VERSION "DNNBNNNYNNNNNNNNNNNNNNNNNNNNNNNNNNNNNNNNNN/4/%%%/4/'%**4NNN///"

NS_ :

BS_:

BU_: Vector__XXX Verdeck TSG_Fahrer TSG_Beifahrer Standheizung SMLS SitzMemo_Fahrer SitzMemo_Beifahrer Reifendruck_VW Reifendruck_Audi PTC_Heizung Multifunktions_SG Komfort_SG Gateway_K FHSG_hinten_rechts FHSG_hinten_links Einparkhilfe Clima BSG Anhaenger_SG

BO_ 1425 mZKE_4: 7 Komfort_SG
 SG_ ZK4_ZVOeffnung : 40|2@1+ (1,0) [0|3] ""  Gateway_K
 SG_ ZK4_verriegelt_int : 8|1@1+ (1,0) [0|1] ""  SitzMemo_Fahrer,BSG,TSG_Beifahrer,TSG_Fahrer,Gateway_K
 SG_ ZK4_verriegelt_ext : 9|1@1+ (1,0) [0|1] ""  SitzMemo_Fahrer,BSG,TSG_Beifahrer,TSG_Fahrer,Gateway_K
 SG_ ZK4_Verdeck_enable : 21|1@1+ (1,0) [0|1] ""  Verdeck,Gateway_K
 SG_ ZK4_Verbau_ZV : 19|1@1+ (1,0) [0|1] ""  Gateway_K
 SG_ ZK4_Verbau_Viertuerer : 16|1@1+ (1,0) [0|1] ""  Gateway_K
 SG_ ZK4_Verbau_Neigung : 34|1@1+ (1,0) [0|1] ""  Gateway_K
 SG_ ZK4_Verbau_eFH_vorn : 17|1@1+ (1,0) [0|1] ""  Gateway_K
 SG_ ZK4_Verbau_eFH_hinten : 18|1@1+ (1,0) [0|1] ""  Gateway_K
 SG_ ZK4_Synchro_Spiegel : 38|1@1+ (1,0) [0|1] ""  TSG_Beifahrer,TSG_Fahrer,Gateway_K
 SG_ ZK4_SD_Komfortoeffnen : 45|1@1+ (1,0) [0|1] ""  Gateway_K
 SG_ ZK4_Schlosstyp : 49|1@1+ (1,0) [0|1] ""  TSG_Beifahrer,TSG_Fahrer
 SG_ ZK4_SAD_Freigabe : 1|1@1+ (1,0) [0|1] ""  Verdeck,BSG,Gateway_K
 SG_ ZK4_Rechtslenker : 20|1@1+ (1,0) [0|1] "" Vector__XXX
 SG_ ZK4_Neigung_aktiv : 27|1@1+ (1,0) [0|1] ""  TSG_Fahrer,Gateway_K
 SG_ ZK4_Komfortfkt_Enable : 2|1@1+ (1,0) [0|1] ""  Verdeck,FHSG_hinten_rechts,FHSG_hinten_links,TSG_Beifahrer,TSG_Fahrer,Gateway_K
 SG_ ZK4_KD_Fehler : 23|1@1+ (1,0) [0|1] ""  Gateway_K
 SG_ ZK4_ist_verriegelt_intern : 35|1@1+ (1,0) [0|1] ""  TSG_Beifahrer,TSG_Fahrer,Gateway_K
 SG_ ZK4_IRUE_aktiv : 28|1@1+ (1,0) [0|1] ""  Gateway_K
 SG_ ZK4_HR_Tuer_offen : 37|1@1+ (1,0) [0|1] ""  BSG,TSG_Beifahrer,TSG_Fahrer,Gateway_K
 SG_ ZK4_HL_Tuer_offen : 36|1@1+ (1,0) [0|1] ""  BSG,TSG_Beifahrer,TSG_Fahrer,Gateway_K
 SG_ ZK4_HDOeffnung : 42|1@1+ (1,0) [0|1] ""  Gateway_K
 SG_ ZK4_HD_Vorraste : 4|1@1+ (1,0) [0|1] ""  Gateway_K
 SG_ ZK4_HD_Hauptraste : 5|1@1+ (1,0) [0|1] ""  Verdeck,BSG,Gateway_K
 SG_ ZK4_HD_Auf_Taster : 26|1@1+ (1,0) [0|1] ""  TSG_Fahrer,Gateway_K
 SG_ ZK4_Handbremse_aktiv : 7|1@1+ (1,0) [0|1] ""  Gateway_K
 SG_ ZK4_gesafet_ext : 10|1@1+ (1,0) [0|1] ""  SitzMemo_Fahrer,BSG,TSG_Beifahrer,TSG_Fahrer,Gateway_K
 SG_ ZK4_FH_Komfortoeffnen : 44|1@1+ (1,0) [0|1] ""  Gateway_K
 SG_ ZK4_FH_Freigabe : 0|1@1+ (1,0) [0|1] ""  BSG,FHSG_hinten_rechts,FHSG_hinten_links,TSG_Beifahrer,TSG_Fahrer,Gateway_K
 SG_ ZK4_Einzeltuerentrieg : 11|1@1+ (1,0) [0|1] ""  SitzMemo_Fahrer,BSG,TSG_Beifahrer,TSG_Fahrer,Gateway_K
 SG_ ZK4_DWA_Akku_leer : 14|1@1+ (1,0) [0|1] ""  Gateway_K
 SG_ ZK4_Autolock : 43|1@1+ (1,0) [0|1] ""  Gateway_K
 SG_ ZK4_Auto_Unlock : 47|1@1+ (1,0) [0|1] ""  Gateway_K
 SG_ ZK4_AD_Komfortoeffnen : 46|1@1+ (1,0) [0|1] ""  Gateway_K
 SG_ ZK4_Absenk_Spiegel : 39|1@1+ (1,0) [0|1] ""  TSG_Beifahrer,TSG_Fahrer,Gateway_K

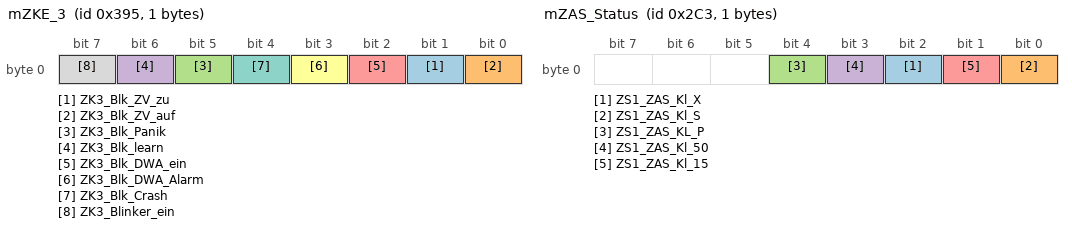
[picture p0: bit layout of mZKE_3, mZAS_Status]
BO_ 917 mZKE_3: 1 Komfort_SG
 SG_ ZK3_Blk_ZV_zu : 1|1@1+ (1,0) [0|1] ""  BSG
 SG_ ZK3_Blk_ZV_auf : 0|1@1+ (1,0) [0|1] ""  BSG
 SG_ ZK3_Blk_Panik : 5|1@1+ (1,0) [0|1] ""  BSG
 SG_ ZK3_Blk_learn : 6|1@1+ (1,0) [0|1] ""  BSG
 SG_ ZK3_Blk_DWA_ein : 2|1@1+ (1,0) [0|1] ""  BSG
 SG_ ZK3_Blk_DWA_Alarm : 3|1@1+ (1,0) [0|1] ""  BSG
 SG_ ZK3_Blk_Crash : 4|1@1+ (1,0) [0|1] ""  BSG
 SG_ ZK3_Blinker_ein : 7|1@1+ (1,0) [0|1] ""  BSG

BO_ 913 mZKE_2: 3 Komfort_SG
 SG_ ZK2_ZV_zu_Heck : 13|1@1+ (1,0) [0|1] ""  FHSG_hinten_rechts,FHSG_hinten_links,TSG_Beifahrer,TSG_Fahrer
 SG_ ZK2_ZV_zu_Funk : 15|1@1+ (1,0) [0|1] ""  BSG,FHSG_hinten_rechts,FHSG_hinten_links,TSG_Beifahrer,TSG_Fahrer
 SG_ ZK2_ZV_zu_FT : 9|1@1+ (1,0) [0|1] ""  BSG,FHSG_hinten_rechts,FHSG_hinten_links,TSG_Beifahrer,TSG_Fahrer
 SG_ ZK2_ZV_zu_BT : 11|1@1+ (1,0) [0|1] ""  BSG,FHSG_hinten_rechts,FHSG_hinten_links,TSG_Beifahrer,TSG_Fahrer
 SG_ ZK2_ZV_auf_Heck : 12|1@1+ (1,0) [0|1] ""  FHSG_hinten_rechts,FHSG_hinten_links,TSG_Beifahrer,TSG_Fahrer
 SG_ ZK2_ZV_auf_Funk : 14|1@1+ (1,0) [0|1] ""  BSG,FHSG_hinten_rechts,FHSG_hinten_links,TSG_Beifahrer,TSG_Fahrer
 SG_ ZK2_ZV_auf_FT : 8|1@1+ (1,0) [0|1] ""  BSG,FHSG_hinten_rechts,FHSG_hinten_links,TSG_Beifahrer,TSG_Fahrer
 SG_ ZK2_ZV_auf_BT : 10|1@1+ (1,0) [0|1] ""  BSG,FHSG_hinten_rechts,FHSG_hinten_links,TSG_Beifahrer,TSG_Fahrer
 SG_ ZK2_SAD_Zu : 18|1@1+ (1,0) [0|1] ""  Verdeck
 SG_ ZK2_SAD_Hoch : 16|1@1+ (1,0) [0|1] ""  Verdeck
 SG_ ZK2_SAD_Auf : 17|1@1+ (1,0) [0|1] ""  Verdeck
 SG_ ZK2_FH_Zu_Z_man : 20|1@1+ (1,0) [0|1] ""  FHSG_hinten_rechts,FHSG_hinten_links,TSG_Beifahrer,TSG_Fahrer
 SG_ ZK2_FH_Zu_Z_auto : 21|1@1+ (1,0) [0|1] ""  FHSG_hinten_rechts,FHSG_hinten_links,TSG_Beifahrer,TSG_Fahrer
 SG_ ZK2_FH_HR_tief : 7|1@1+ (1,0) [0|1] ""  FHSG_hinten_rechts
 SG_ ZK2_FH_HR_hoch : 6|1@1+ (1,0) [0|1] ""  FHSG_hinten_rechts
 SG_ ZK2_FH_HL_tief : 5|1@1+ (1,0) [0|1] ""  FHSG_hinten_links
 SG_ ZK2_FH_HL_hoch : 4|1@1+ (1,0) [0|1] ""  FHSG_hinten_links
 SG_ ZK2_FH_FT_tief : 1|1@1+ (1,0) [0|1] ""  TSG_Fahrer
 SG_ ZK2_FH_FT_hoch : 0|1@1+ (1,0) [0|1] ""  TSG_Fahrer
 SG_ ZK2_FH_BT_tief : 3|1@1+ (1,0) [0|1] ""  TSG_Beifahrer
 SG_ ZK2_FH_BT_hoch : 2|1@1+ (1,0) [0|1] ""  TSG_Beifahrer
 SG_ ZK2_FH_Auf_Z_man : 22|1@1+ (1,0) [0|1] ""  FHSG_hinten_rechts,FHSG_hinten_links,TSG_Beifahrer,TSG_Fahrer
 SG_ ZK2_FH_Auf_Z_auto : 23|1@1+ (1,0) [0|1] ""  FHSG_hinten_rechts,FHSG_hinten_links,TSG_Beifahrer,TSG_Fahrer

BO_ 657 mZKE_1: 5 Komfort_SG
 SG_ ZK1_Zent_safen : 16|1@1+ (1,0) [0|1] ""  BSG,TSG_Beifahrer,TSG_Fahrer
 SG_ ZK1_Zent_entsafen : 17|1@1+ (1,0) [0|1] ""  BSG,TSG_Beifahrer,TSG_Fahrer
 SG_ ZK1_Taste_Zu : 7|1@1+ (1,0) [0|1] ""  SitzMemo_Fahrer,FHSG_hinten_rechts,FHSG_hinten_links,TSG_Beifahrer,TSG_Fahrer
 SG_ ZK1_Taste_Panik : 5|1@1+ (1,0) [0|1] ""  TSG_Beifahrer,TSG_Fahrer
 SG_ ZK1_Taste_HDF : 4|1@1+ (1,0) [0|1] ""  TSG_Beifahrer,TSG_Fahrer
 SG_ ZK1_Taste_Auf : 6|1@1+ (1,0) [0|1] ""  SitzMemo_Fahrer,FHSG_hinten_rechts,FHSG_hinten_links,TSG_Beifahrer,TSG_Fahrer
 SG_ ZK1_LED_Uebernahme : 23|1@1+ (1,0) [0|1] ""  TSG_Fahrer
 SG_ ZK1_LED_Steuerung : 22|1@1+ (1,0) [0|1] ""  TSG_Fahrer
 SG_ ZK1_HR_verriegeln : 14|1@1+ (1,0) [0|1] "" Vector__XXX
 SG_ ZK1_HR_Tuer_offen : 37|1@1+ (1,0) [0|1] ""  FHSG_hinten_rechts
 SG_ ZK1_HR_entriegeln : 15|1@1+ (1,0) [0|1] "" Vector__XXX
 SG_ ZK1_HL_verriegeln : 12|1@1+ (1,0) [0|1] "" Vector__XXX
 SG_ ZK1_HL_Tuer_offen : 36|1@1+ (1,0) [0|1] ""  FHSG_hinten_links
 SG_ ZK1_HL_entriegeln : 13|1@1+ (1,0) [0|1] "" Vector__XXX
 SG_ ZK1_HD_verriegeln : 18|1@1+ (1,0) [0|1] "" Vector__XXX
 SG_ ZK1_HD_schliessen : 21|1@1+ (1,0) [0|1] "" Vector__XXX
 SG_ ZK1_HD_oeffnen : 20|1@1+ (1,0) [0|1] "" Vector__XXX
 SG_ ZK1_HD_entriegeln : 19|1@1+ (1,0) [0|1] "" Vector__XXX
 SG_ ZK1_Funkschl_Nr : 0|3@1+ (1,0) [0|7] ""  SitzMemo_Fahrer
 SG_ ZK1_FT_verriegeln : 8|1@1+ (1,0) [0|1] ""  SitzMemo_Fahrer,TSG_Fahrer
 SG_ ZK1_FT_entriegeln : 9|1@1+ (1,0) [0|1] ""  SitzMemo_Fahrer,TSG_Fahrer
 SG_ ZK1_BT_verriegeln : 10|1@1+ (1,0) [0|1] ""  TSG_Beifahrer
 SG_ ZK1_BT_entriegeln : 11|1@1+ (1,0) [0|1] ""  TSG_Beifahrer
 SG_ ZK1_433_MHz : 3|1@1+ (1,0) [0|1] ""  Reifendruck_VW,Reifendruck_Audi

BO_ 707 mZAS_Status: 1 SMLS
 SG_ ZS1_ZAS_Kl_X : 2|1@1+ (1,0) [0|1] ""  BSG,Gateway_K
 SG_ ZS1_ZAS_Kl_S : 0|1@1+ (1,0) [0|1] ""  Reifendruck_VW,Multifunktions_SG,SitzMemo_Beifahrer,SitzMemo_Fahrer,Anhaenger_SG,BSG,FHSG_hinten_rechts,FHSG_hinten_links,TSG_Beifahrer,TSG_Fahrer,Komfort_SG,Gateway_K
 SG_ ZS1_ZAS_KL_P : 4|1@1+ (1,0) [0|1] ""  BSG,Gateway_K
 SG_ ZS1_ZAS_Kl_50 : 3|1@1+ (1,0) [0|1] ""  BSG,Gateway_K
 SG_ ZS1_ZAS_Kl_15 : 1|1@1+ (1,0) [0|1] ""  BSG,Gateway_K

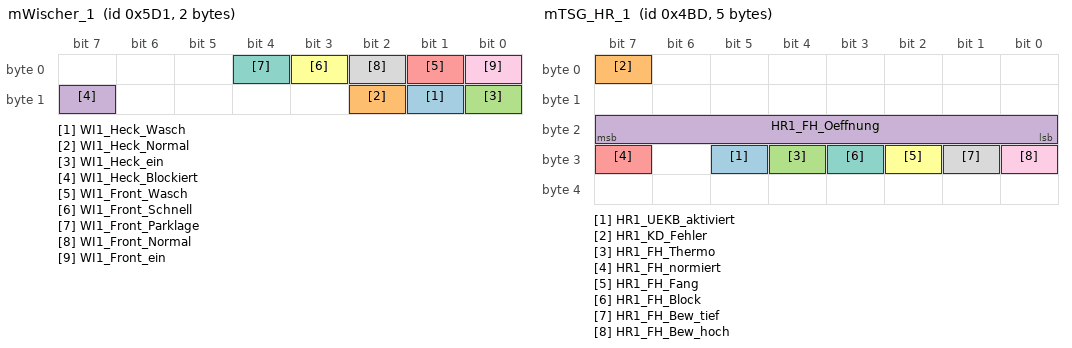
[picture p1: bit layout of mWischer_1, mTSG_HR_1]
BO_ 1489 mWischer_1: 2 BSG
 SG_ WI1_Heck_Wasch : 9|1@1+ (1,0) [0|1] "" Vector__XXX
 SG_ WI1_Heck_Normal : 10|1@1+ (1,0) [0|1] "" Vector__XXX
 SG_ WI1_Heck_ein : 8|1@1+ (1,0) [0|1] ""  Komfort_SG
 SG_ WI1_Heck_Blockiert : 15|1@1+ (1,0) [0|1] "" Vector__XXX
 SG_ WI1_Front_Wasch : 1|1@1+ (1,0) [0|1] ""  Multifunktions_SG
 SG_ WI1_Front_Schnell : 3|1@1+ (1,0) [0|1] ""  Multifunktions_SG
 SG_ WI1_Front_Parklage : 4|1@1+ (1,0) [0|1] "" Vector__XXX
 SG_ WI1_Front_Normal : 2|1@1+ (1,0) [0|1] ""  Multifunktions_SG
 SG_ WI1_Front_ein : 0|1@1+ (1,0) [0|1] ""  Gateway_K

BO_ 1361 mWFS_1: 1 Gateway_K
 SG_ WF1_Schluessel : 0|4@1+ (1,0) [0|15] ""  SitzMemo_Beifahrer,SitzMemo_Fahrer,Clima,Komfort_SG

BO_ 1497 mVSG_1: 5 Verdeck
 SG_ VS1_Verdeck_Anf : 22|1@1+ (1,0) [0|1] ""  Komfort_SG
 SG_ VS1_VD_Zwischenposition : 19|1@1+ (1,0) [0|1] "" Vector__XXX
 SG_ VS1_VD_zu_ver : 16|1@1+ (1,0) [0|1] ""  Komfort_SG
 SG_ VS1_VD_offen_ver : 18|1@1+ (1,0) [0|1] ""  Komfort_SG
 SG_ VS1_VD_Fehler : 24|1@1+ (1,0) [0|1] "" Vector__XXX
 SG_ VS1_VD_entriegelt : 17|1@1+ (1,0) [0|1] "" Vector__XXX
 SG_ VS1_VD_Bew_zu : 21|1@1+ (1,0) [0|1] ""  BSG
 SG_ VS1_VD_Bew_auf : 20|1@1+ (1,0) [0|1] ""  BSG
 SG_ VS1_Texte : 32|8@1+ (1,0) [0|255] "Tabelle"  Gateway_K
 SG_ VS1_Lampe_Blk : 25|1@1+ (1,0) [0|1] ""  Gateway_K
 SG_ VS1_KD_Fehler : 31|1@1+ (1,0) [0|1] "" Vector__XXX
 SG_ VS1_HHS_enable : 28|1@1+ (1,0) [0|1] ""  BSG
 SG_ VS1_Hardtop : 23|1@1+ (1,0) [0|1] "" Vector__XXX
 SG_ VS1_Freigabe_FH : 8|1@1+ (1,0) [0|1] ""  FHSG_hinten_rechts,FHSG_hinten_links,TSG_Beifahrer,TSG_Fahrer
 SG_ VS1_FH_HR_tief : 7|1@1+ (1,0) [0|1] ""  FHSG_hinten_rechts
 SG_ VS1_FH_HR_hoch : 6|1@1+ (1,0) [0|1] ""  FHSG_hinten_rechts
 SG_ VS1_FH_HL_tief : 5|1@1+ (1,0) [0|1] ""  FHSG_hinten_links
 SG_ VS1_FH_HL_hoch : 4|1@1+ (1,0) [0|1] ""  FHSG_hinten_links
 SG_ VS1_FH_FT_tief : 1|1@1+ (1,0) [0|1] ""  TSG_Fahrer
 SG_ VS1_FH_FT_hoch : 0|1@1+ (1,0) [0|1] ""  TSG_Fahrer
 SG_ VS1_FH_BT_tief : 3|1@1+ (1,0) [0|1] ""  TSG_Beifahrer
 SG_ VS1_FH_BT_hoch : 2|1@1+ (1,0) [0|1] ""  TSG_Beifahrer
 SG_ VS1_Buzzer : 27|1@1+ (1,0) [0|1] ""  Gateway_K

BO_ 1213 mTSG_HR_1: 5 FHSG_hinten_rechts
 SG_ HR1_UEKB_aktiviert : 29|1@1+ (1,0) [0|1] ""  Komfort_SG
 SG_ HR1_KD_Fehler : 7|1@1+ (1,0) [0|1] ""  Gateway_K
 SG_ HR1_FH_Thermo : 28|1@1+ (1,0) [0|1] ""  Komfort_SG
 SG_ HR1_FH_Oeffnung : 16|8@1+ (0.5,0) [0|100] "%"  Verdeck,Komfort_SG
 SG_ HR1_FH_normiert : 31|1@1+ (1,0) [0|1] ""  Komfort_SG
 SG_ HR1_FH_Fang : 26|1@1+ (1,0) [0|1] ""  Komfort_SG
 SG_ HR1_FH_Block : 27|1@1+ (1,0) [0|1] ""  Komfort_SG
 SG_ HR1_FH_Bew_tief : 25|1@1+ (1,0) [0|1] ""  BSG,Komfort_SG
 SG_ HR1_FH_Bew_hoch : 24|1@1+ (1,0) [0|1] ""  BSG,Komfort_SG

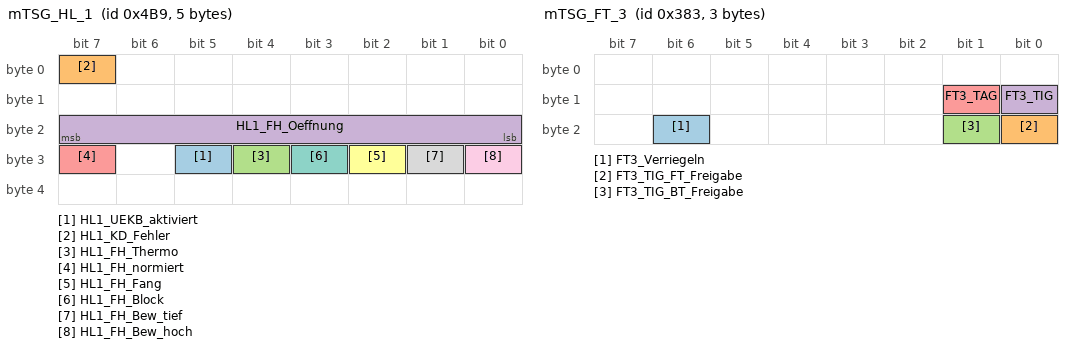
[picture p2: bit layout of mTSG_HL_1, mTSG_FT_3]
BO_ 1209 mTSG_HL_1: 5 FHSG_hinten_links
 SG_ HL1_UEKB_aktiviert : 29|1@1+ (1,0) [0|1] ""  Komfort_SG
 SG_ HL1_KD_Fehler : 7|1@1+ (1,0) [0|1] ""  Gateway_K
 SG_ HL1_FH_Thermo : 28|1@1+ (1,0) [0|1] ""  Komfort_SG
 SG_ HL1_FH_Oeffnung : 16|8@1+ (0.5,0) [0|100] "%"  Verdeck,Komfort_SG
 SG_ HL1_FH_normiert : 31|1@1+ (1,0) [0|1] ""  Komfort_SG
 SG_ HL1_FH_Fang : 26|1@1+ (1,0) [0|1] ""  Komfort_SG
 SG_ HL1_FH_Block : 27|1@1+ (1,0) [0|1] ""  Komfort_SG
 SG_ HL1_FH_Bew_tief : 25|1@1+ (1,0) [0|1] ""  BSG,Komfort_SG
 SG_ HL1_FH_Bew_hoch : 24|1@1+ (1,0) [0|1] ""  BSG,Komfort_SG

BO_ 899 mTSG_FT_3: 3 TSG_Fahrer
 SG_ FT3_Verriegeln : 22|1@1+ (1,0) [0|1] "" Vector__XXX
 SG_ FT3_TIG_FT_Freigabe : 16|1@1+ (1,0) [0|1] "" Vector__XXX
 SG_ FT3_TIG_BT_Freigabe : 17|1@1+ (1,0) [0|1] ""  TSG_Beifahrer
 SG_ FT3_TIG : 8|1@1+ (1,0) [0|1] "" Vector__XXX
 SG_ FT3_TAG : 9|1@1+ (1,0) [0|1] "" Vector__XXX

BO_ 897 mTSG_FT_1: 5 TSG_Fahrer
 SG_ FT1_verriegelt : 1|1@1+ (1,0) [0|1] ""  Komfort_SG
 SG_ FT1_Unlock_Taster : 5|1@1+ (1,0) [0|1] ""  Komfort_SG
 SG_ FT1_UEKB_aktiviert : 29|1@1+ (1,0) [0|1] ""  Komfort_SG
 SG_ FT1_Tuer_geoeffnet : 0|1@1+ (1,0) [0|1] ""  Reifendruck_Audi,Multifunktions_SG,BSG,TSG_Beifahrer,Komfort_SG
 SG_ FT1_Tankklappe_oeffnen : 36|1@1+ (1,0) [0|1] ""  Komfort_SG
 SG_ FT1_SP_Heizung_ein : 34|1@1+ (1,0) [0|1] ""  BSG
 SG_ FT1_SP_ausgerastet : 32|1@1+ (1,0) [0|1] "" Vector__XXX
 SG_ FT1_SP_AS_verbaut : 33|1@1+ (1,0) [0|1] "" Vector__XXX
 SG_ FT1_Schl_zu : 4|1@1+ (1,0) [0|1] ""  TSG_Beifahrer,Komfort_SG
 SG_ FT1_Schl_auf : 3|1@1+ (1,0) [0|1] ""  TSG_Beifahrer,Komfort_SG
 SG_ FT1_Neig_Taster : 38|1@1+ (1,0) [0|1] ""  Komfort_SG
 SG_ FT1_Lock_Taster : 6|1@1+ (1,0) [0|1] ""  Komfort_SG
 SG_ FT1_KD_Fehler : 7|1@1+ (1,0) [0|1] ""  Gateway_K
 SG_ FT1_IRUE_Taste : 35|1@1+ (1,0) [0|1] ""  Komfort_SG
 SG_ FT1_HD_oeffnen : 37|1@1+ (1,0) [0|1] ""  Komfort_SG
 SG_ FT1_gesafet : 2|1@1+ (1,0) [0|1] ""  Komfort_SG
 SG_ FT1_FH_Thermo : 28|1@1+ (1,0) [0|1] ""  Komfort_SG
 SG_ FT1_FH_Oeffnung : 16|8@1+ (0.5,0) [0|100] "%"  Verdeck,Komfort_SG
 SG_ FT1_FH_normiert : 31|1@1+ (1,0) [0|1] ""  Komfort_SG
 SG_ FT1_FH_HR_Freigabe : 11|1@1+ (1,0) [0|1] ""  FHSG_hinten_rechts
 SG_ FT1_FH_HL_Freigabe : 10|1@1+ (1,0) [0|1] ""  FHSG_hinten_links
 SG_ FT1_FH_FT_Freigabe : 8|1@1+ (1,0) [0|1] "" Vector__XXX
 SG_ FT1_FH_Fang : 26|1@1+ (1,0) [0|1] ""  Komfort_SG
 SG_ FT1_FH_BT_Freigabe : 9|1@1+ (1,0) [0|1] ""  TSG_Beifahrer
 SG_ FT1_FH_Block : 27|1@1+ (1,0) [0|1] ""  Komfort_SG
 SG_ FT1_FH_Bew_tief : 25|1@1+ (1,0) [0|1] ""  BSG,Komfort_SG
 SG_ FT1_FH_Bew_hoch : 24|1@1+ (1,0) [0|1] ""  BSG,Komfort_SG

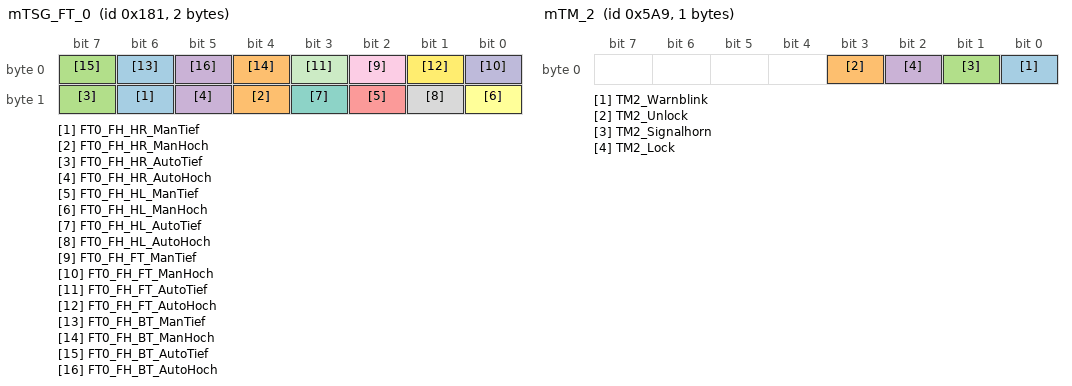
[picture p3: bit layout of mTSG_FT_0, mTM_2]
BO_ 385 mTSG_FT_0: 2 TSG_Fahrer
 SG_ FT0_FH_HR_ManTief : 14|1@1+ (1,0) [0|1] ""  FHSG_hinten_rechts
 SG_ FT0_FH_HR_ManHoch : 12|1@1+ (1,0) [0|1] ""  FHSG_hinten_rechts
 SG_ FT0_FH_HR_AutoTief : 15|1@1+ (1,0) [0|1] ""  FHSG_hinten_rechts
 SG_ FT0_FH_HR_AutoHoch : 13|1@1+ (1,0) [0|1] ""  FHSG_hinten_rechts
 SG_ FT0_FH_HL_ManTief : 10|1@1+ (1,0) [0|1] ""  FHSG_hinten_links
 SG_ FT0_FH_HL_ManHoch : 8|1@1+ (1,0) [0|1] ""  FHSG_hinten_links
 SG_ FT0_FH_HL_AutoTief : 11|1@1+ (1,0) [0|1] ""  FHSG_hinten_links
 SG_ FT0_FH_HL_AutoHoch : 9|1@1+ (1,0) [0|1] ""  FHSG_hinten_links
 SG_ FT0_FH_FT_ManTief : 2|1@1+ (1,0) [0|1] ""  Komfort_SG
 SG_ FT0_FH_FT_ManHoch : 0|1@1+ (1,0) [0|1] ""  Komfort_SG
 SG_ FT0_FH_FT_AutoTief : 3|1@1+ (1,0) [0|1] ""  Multifunktions_SG,Komfort_SG
 SG_ FT0_FH_FT_AutoHoch : 1|1@1+ (1,0) [0|1] ""  Multifunktions_SG,Komfort_SG
 SG_ FT0_FH_BT_ManTief : 6|1@1+ (1,0) [0|1] ""  TSG_Beifahrer
 SG_ FT0_FH_BT_ManHoch : 4|1@1+ (1,0) [0|1] ""  TSG_Beifahrer
 SG_ FT0_FH_BT_AutoTief : 7|1@1+ (1,0) [0|1] ""  Multifunktions_SG,TSG_Beifahrer
 SG_ FT0_FH_BT_AutoHoch : 5|1@1+ (1,0) [0|1] ""  Multifunktions_SG,TSG_Beifahrer

BO_ 949 mTSG_BT_1: 5 TSG_Beifahrer
 SG_ BT1_verriegelt : 1|1@1+ (1,0) [0|1] ""  Komfort_SG
 SG_ BT1_Unlock_Taster : 5|1@1+ (1,0) [0|1] ""  Komfort_SG
 SG_ BT1_UEKB_aktiviert : 29|1@1+ (1,0) [0|1] ""  Komfort_SG
 SG_ BT1_Tuer_geoeffnet : 0|1@1+ (1,0) [0|1] ""  BSG,TSG_Fahrer,Komfort_SG
 SG_ BT1_SP_Heizung_ein : 34|1@1+ (1,0) [0|1] ""  BSG
 SG_ BT1_SP_ausgerastet : 32|1@1+ (1,0) [0|1] ""  TSG_Fahrer
 SG_ BT1_SP_AS_verbaut : 33|1@1+ (1,0) [0|1] "" Vector__XXX
 SG_ BT1_Schl_zu : 4|1@1+ (1,0) [0|1] ""  TSG_Fahrer,Komfort_SG
 SG_ BT1_Schl_auf : 3|1@1+ (1,0) [0|1] ""  TSG_Fahrer,Komfort_SG
 SG_ BT1_Lock_Taster : 6|1@1+ (1,0) [0|1] ""  Komfort_SG
 SG_ BT1_KD_Fehler : 7|1@1+ (1,0) [0|1] ""  Gateway_K
 SG_ BT1_gesafet : 2|1@1+ (1,0) [0|1] ""  Komfort_SG
 SG_ BT1_FH_Thermo : 28|1@1+ (1,0) [0|1] ""  Komfort_SG
 SG_ BT1_FH_Oeffnung : 16|8@1+ (0.5,0) [0|100] "%"  Verdeck,Komfort_SG
 SG_ BT1_FH_normiert : 31|1@1+ (1,0) [0|1] ""  Komfort_SG
 SG_ BT1_FH_Fang : 26|1@1+ (1,0) [0|1] ""  Komfort_SG
 SG_ BT1_FH_Block : 27|1@1+ (1,0) [0|1] ""  Komfort_SG
 SG_ BT1_FH_Bew_tief : 25|1@1+ (1,0) [0|1] ""  BSG,Komfort_SG
 SG_ BT1_FH_Bew_hoch : 24|1@1+ (1,0) [0|1] ""  BSG,Komfort_SG

BO_ 562 mTP_Er_Wischermodul: 7 BSG
 SG_ Wischermodul_TP_Er : 0|56@1+ (1,0) [0|0] ""  Gateway_K

BO_ 560 mTP_Er_VSG: 7 Verdeck
 SG_ VSG_TP_Er : 0|56@1+ (1,0) [0|0] ""  Gateway_K

BO_ 549 mTP_Er_TSG_HR: 7 FHSG_hinten_rechts
 SG_ HR_TP_Er : 0|56@1+ (1,0) [0|0] ""  Gateway_K

BO_ 548 mTP_Er_TSG_HL: 7 FHSG_hinten_links
 SG_ HL_TP_Er : 0|56@1+ (1,0) [0|0] ""  Gateway_K

BO_ 546 mTP_Er_TSG_FT: 7 TSG_Fahrer
 SG_ FT_TP_Er : 0|56@1+ (1,0) [0|0] ""  Gateway_K

BO_ 547 mTP_Er_TSG_BT: 7 TSG_Beifahrer
 SG_ BT_TP_Er : 0|56@1+ (1,0) [0|0] ""  Gateway_K

BO_ 512 mTP_Er_Tester: 7 Gateway_K
 SG_ Tester_TP_Er : 0|56@1+ (1,0) [0|0] ""  Reifendruck_VW,Reifendruck_Audi,Multifunktions_SG,SMLS,SitzMemo_Beifahrer,SitzMemo_Fahrer,Einparkhilfe,Verdeck,PTC_Heizung,Standheizung,Clima,Anhaenger_SG,BSG,FHSG_hinten_rechts,FHSG_hinten_links,TSG_Beifahrer,TSG_Fahrer,Komfort_SG

BO_ 554 mTP_Er_SMLS: 7 SMLS
 SG_ SMLS_TP_Er : 0|56@1+ (1,0) [0|0] ""  Gateway_K

BO_ 559 mTP_Er_SH: 7 Standheizung
 SG_ SH_TP_Er : 0|56@1+ (1,0) [0|0] ""  Gateway_K

BO_ 553 mTP_Er_RDK: 7 Reifendruck_Audi
 SG_ RDK_TP_Er : 0|56@1+ (1,0) [0|0] ""  Gateway_K

BO_ 558 mTP_Er_PTC: 7 PTC_Heizung
 SG_ PTC_TP_Er : 0|56@1+ (1,0) [0|0] ""  Gateway_K

BO_ 570 mTP_Er_MFG: 7 Multifunktions_SG
 SG_ MFG_TP_Er : 0|56@1+ (1,0) [0|0] ""  Gateway_K

BO_ 565 mTP_Er_Mem_BF: 7 SitzMemo_Beifahrer
 SG_ Mem_BF_TP_Er : 0|56@1+ (1,0) [0|0] ""  Gateway_K

BO_ 550 mTP_Er_MEM: 7 SitzMemo_Fahrer
 SG_ MEM_TP_Er : 0|56@1+ (1,0) [0|0] ""  Gateway_K

BO_ 545 mTP_Er_KSG: 7 Komfort_SG
 SG_ KSG_TP_Er : 0|56@1+ (1,0) [0|0] ""  Gateway_K

BO_ 543 mTP_Er_Gateway: 7 Gateway_K
 SG_ Gateway_TP_Er : 0|56@1+ (1,0) [0|0] "" Vector__XXX

BO_ 556 mTP_Er_Clima: 7 Clima
 SG_ CL_TP_Er : 0|56@1+ (1,0) [0|0] ""  Gateway_K

BO_ 544 mTP_Er_BSG: 7 BSG
 SG_ BSG_TP_Er : 0|56@1+ (1,0) [0|0] ""  Gateway_K

BO_ 557 mTP_Er_APS: 7 Einparkhilfe
 SG_ APS_TP_Er : 0|56@1+ (1,0) [0|0] ""  Gateway_K

BO_ 579 mTP_Er_AnhaengerSG: 7 Anhaenger_SG
 SG_ AAG_TP_Er : 0|56@1+ (1,0) [0|0] ""  Gateway_K

BO_ 811 mTP_Dyn_VSG_2: 8 Gateway_K
 SG_ TPDyn_VSG_2 : 0|64@1+ (1,0) [0|0] ""  Verdeck

BO_ 810 mTP_Dyn_VSG_1: 8 Gateway_K
 SG_ TPDyn_VSG_1 : 0|64@1+ (1,0) [0|0] ""  Verdeck

BO_ 791 mTP_Dyn_TSG_HR_2: 8 Gateway_K
 SG_ TPDyn_TSG_HR_2 : 0|64@1+ (1,0) [0|0] ""  FHSG_hinten_rechts

BO_ 790 mTP_Dyn_TSG_HR_1: 8 Gateway_K
 SG_ TPDyn_TSG_HR_1 : 0|64@1+ (1,0) [0|0] ""  FHSG_hinten_rechts

BO_ 789 mTP_Dyn_TSG_HL_2: 8 Gateway_K
 SG_ TPDyn_TSG_HL_2 : 0|64@1+ (1,0) [0|0] ""  FHSG_hinten_links

BO_ 788 mTP_Dyn_TSG_HL_1: 8 Gateway_K
 SG_ TPDyn_TSG_HL_1 : 0|64@1+ (1,0) [0|0] ""  FHSG_hinten_links

BO_ 785 mTP_Dyn_TSG_F_2: 8 Gateway_K
 SG_ TPDyn_TSG_F_2 : 0|64@1+ (1,0) [0|0] ""  TSG_Fahrer

BO_ 784 mTP_Dyn_TSG_F_1: 8 Gateway_K
 SG_ TPDyn_TSG_F_1 : 0|64@1+ (1,0) [0|0] ""  TSG_Fahrer

BO_ 787 mTP_Dyn_TSG_BF_2: 8 Gateway_K
 SG_ TPDyn_TSG_BF_2 : 0|64@1+ (1,0) [0|0] ""  TSG_Beifahrer

BO_ 786 mTP_Dyn_TSG_BF_1: 8 Gateway_K
 SG_ TPDyn_TSG_BF_1 : 0|64@1+ (1,0) [0|0] ""  TSG_Beifahrer

BO_ 765 mTP_Dyn_SMLS_2: 8 Gateway_K
 SG_ TPDyn_SMLS_2 : 0|64@1+ (1,0) [0|0] ""  SMLS

BO_ 764 mTP_Dyn_SMLS_1: 8 Gateway_K
 SG_ TPDyn_SMLS_1 : 0|64@1+ (1,0) [0|0] ""  SMLS

BO_ 805 mTP_Dyn_SH_2: 8 Gateway_K
 SG_ TPDyn_SH_2 : 0|64@1+ (1,0) [0|0] ""  Standheizung

BO_ 804 mTP_Dyn_SH_1: 8 Gateway_K
 SG_ TPDyn_SH_1 : 0|64@1+ (1,0) [0|0] ""  Standheizung

BO_ 803 mTP_Dyn_RDK_2: 8 Gateway_K
 SG_ TPDyn_RDK_2 : 0|64@1+ (1,0) [0|0] ""  Reifendruck_VW,Reifendruck_Audi

BO_ 802 mTP_Dyn_RDK_1: 8 Gateway_K
 SG_ TPDyn_RDK_1 : 0|64@1+ (1,0) [0|0] ""  Reifendruck_VW,Reifendruck_Audi

BO_ 827 mTP_Dyn_PTC_2: 8 Gateway_K
 SG_ TPDyn_PTC_2 : 0|64@1+ (1,0) [0|0] ""  PTC_Heizung

BO_ 826 mTP_Dyn_PTC_1: 8 Gateway_K
 SG_ TPDyn_PTC_1 : 0|64@1+ (1,0) [0|0] ""  PTC_Heizung

BO_ 767 mTP_Dyn_MFG_2: 8 Gateway_K
 SG_ TPDyn_MFG_2 : 0|64@1+ (1,0) [0|0] ""  Multifunktions_SG

BO_ 766 mTP_Dyn_MFG_1: 8 Gateway_K
 SG_ TPDyn_MFG_1 : 0|64@1+ (1,0) [0|0] ""  Multifunktions_SG

BO_ 793 mTP_Dyn_Mem_F_2: 8 Gateway_K
 SG_ TPDyn_Mem_F_2 : 0|64@1+ (1,0) [0|0] ""  SitzMemo_Fahrer

BO_ 792 mTP_Dyn_Mem_F_1: 8 Gateway_K
 SG_ TPDyn_Mem_F_1 : 0|64@1+ (1,0) [0|0] ""  SitzMemo_Fahrer

BO_ 795 mTP_Dyn_MEM_BF_2: 8 Gateway_K
 SG_ TPDyn_MEM_BF_2 : 0|64@1+ (1,0) [0|0] ""  SitzMemo_Beifahrer

BO_ 794 mTP_Dyn_MEM_BF_1: 8 Gateway_K
 SG_ TPDyn_MEM_BF_1 : 0|64@1+ (1,0) [0|0] ""  SitzMemo_Beifahrer

BO_ 809 mTP_Dyn_KSG_2: 8 Gateway_K
 SG_ TPDyn_KSG_2 : 0|64@1+ (1,0) [0|0] ""  Komfort_SG

BO_ 808 mTP_Dyn_KSG_1: 8 Gateway_K
 SG_ TPDyn_KSG_1 : 0|64@1+ (1,0) [0|0] ""  Komfort_SG

BO_ 815 mTP_Dyn_GW_2: 8 Vector__XXX
 SG_ TPDyn_GW_2 : 0|64@1+ (1,0) [0|0] ""  Gateway_K

BO_ 814 mTP_Dyn_GW_1: 8 Vector__XXX
 SG_ TPDyn_GW_1 : 0|64@1+ (1,0) [0|0] ""  Gateway_K

BO_ 1235 mTP_Dyn_Grafik_4: 8 Komfort_SG
 SG_ TPDyn_Grafik_4 : 0|64@1+ (1,0) [0|0] ""  Gateway_K

BO_ 1234 mTP_Dyn_Grafik_3: 8 Komfort_SG
 SG_ TPDyn_Grafik_3 : 0|64@1+ (1,0) [0|0] ""  Gateway_K

BO_ 1233 mTP_Dyn_Grafik_2: 8 Komfort_SG
 SG_ TPDyn_Grafik_2 : 0|64@1+ (1,0) [0|0] ""  Gateway_K

BO_ 1232 mTP_Dyn_Grafik_1: 8 Komfort_SG
 SG_ TPDyn_Grafik_1 : 0|64@1+ (1,0) [0|0] ""  Gateway_K

BO_ 829 mTP_Dyn_Clima_2: 8 Gateway_K
 SG_ TPDyn_Clima_2 : 0|64@1+ (1,0) [0|0] ""  Clima

BO_ 828 mTP_Dyn_Clima_1: 8 Gateway_K
 SG_ TPDyn_Clima_1 : 0|64@1+ (1,0) [0|0] ""  Clima

BO_ 825 mTP_Dyn_BSG_2: 8 Gateway_K
 SG_ TPDyn_BSG_2 : 0|64@1+ (1,0) [0|0] ""  BSG

BO_ 824 mTP_Dyn_BSG_1: 8 Gateway_K
 SG_ TPDyn_BSG_1 : 0|64@1+ (1,0) [0|0] ""  BSG

BO_ 819 mTP_Dyn_APS_2: 8 Gateway_K
 SG_ TPDyn_APS_2 : 0|64@1+ (1,0) [0|0] ""  Einparkhilfe

BO_ 818 mTP_Dyn_APS_1: 8 Gateway_K
 SG_ TPDyn_APS_1 : 0|64@1+ (1,0) [0|0] ""  Einparkhilfe

BO_ 823 mTP_Dyn_AAG_2: 8 Gateway_K
 SG_ TPDyn_AAG_2 : 0|64@1+ (1,0) [0|0] ""  Anhaenger_SG

BO_ 822 mTP_Dyn_AAG_1: 8 Gateway_K
 SG_ TPDyn_AAG_1 : 0|64@1+ (1,0) [0|0] ""  Anhaenger_SG

BO_ 1449 mTM_2: 1 Gateway_K
 SG_ TM2_Warnblink : 0|1@1+ (1,0) [0|1] "" Vector__XXX
 SG_ TM2_Unlock : 3|1@1+ (1,0) [0|1] "" Vector__XXX
 SG_ TM2_Signalhorn : 1|1@1+ (1,0) [0|1] "" Vector__XXX
 SG_ TM2_Lock : 2|1@1+ (1,0) [0|1] "" Vector__XXX

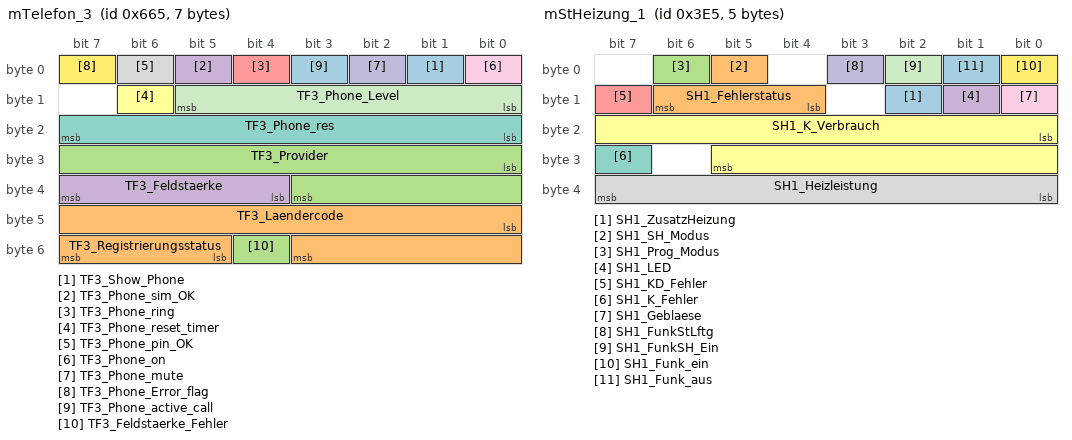
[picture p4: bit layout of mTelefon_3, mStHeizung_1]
BO_ 1637 mTelefon_3: 7 Gateway_K
 SG_ TF3_Show_Phone : 1|1@1+ (1,0) [0|1] "" Vector__XXX
 SG_ TF3_Registrierungsstatus : 53|3@1+ (1,0) [0|7] "" Vector__XXX
 SG_ TF3_Provider : 24|12@1+ (1,0) [0|4095] "" Vector__XXX
 SG_ TF3_Phone_sim_OK : 5|1@1+ (1,0) [0|1] "" Vector__XXX
 SG_ TF3_Phone_ring : 4|1@1+ (1,0) [0|1] ""  SMLS
 SG_ TF3_Phone_reset_timer : 14|1@1+ (1,0) [0|1] "" Vector__XXX
 SG_ TF3_Phone_res : 16|8@1+ (1,0) [0|255] "" Vector__XXX
 SG_ TF3_Phone_pin_OK : 6|1@1+ (1,0) [0|1] "" Vector__XXX
 SG_ TF3_Phone_on : 0|1@1+ (1,0) [0|1] ""  SMLS
 SG_ TF3_Phone_mute : 2|1@1+ (1,0) [0|1] "" Vector__XXX
 SG_ TF3_Phone_Level : 8|6@1+ (1,0) [0|63] "" Vector__XXX
 SG_ TF3_Phone_Error_flag : 7|1@1+ (1,0) [0|1] "" Vector__XXX
 SG_ TF3_Phone_active_call : 3|1@1+ (1,0) [0|1] ""  SMLS
 SG_ TF3_Laendercode : 40|12@1+ (1,0) [0|4095] "" Vector__XXX
 SG_ TF3_Feldstaerke_Fehler : 52|1@1+ (1,0) [0|1] "" Vector__XXX
 SG_ TF3_Feldstaerke : 36|4@1+ (1,0) [0|15] "" Vector__XXX

BO_ 1617 mSysteminfo_1: 6 Gateway_K
 SG_ SY1_Viertuerer : 29|1@1+ (1,0) [0|1] ""  Clima,BSG,FHSG_hinten_rechts,FHSG_hinten_links,TSG_Beifahrer,TSG_Fahrer
 SG_ SY1_VersLowCAN_Komfort : 32|4@1+ (1,0) [0|15] ""  Reifendruck_VW,SitzMemo_Beifahrer,SitzMemo_Fahrer,Einparkhilfe,PTC_Heizung,Standheizung,Clima,Anhaenger_SG,BSG,FHSG_hinten_rechts,FHSG_hinten_links,TSG_Beifahrer,TSG_Fahrer,Komfort_SG
 SG_ SY1_VersLowCAN_Antrieb : 40|4@1+ (1,0) [0|15] ""  Reifendruck_VW,SitzMemo_Beifahrer,SitzMemo_Fahrer,PTC_Heizung,Standheizung,Clima,Anhaenger_SG,BSG,FHSG_hinten_rechts,FHSG_hinten_links,TSG_Beifahrer,TSG_Fahrer,Komfort_SG
 SG_ SY1_VersHighCAN_Komfort : 36|4@1+ (1,0) [0|15] ""  Reifendruck_VW,SitzMemo_Beifahrer,SitzMemo_Fahrer,Einparkhilfe,PTC_Heizung,Standheizung,Clima,Anhaenger_SG,BSG,FHSG_hinten_rechts,FHSG_hinten_links,TSG_Beifahrer,TSG_Fahrer,Komfort_SG
 SG_ SY1_VersHighCAN_Antrieb : 44|4@1+ (1,0) [0|15] ""  Reifendruck_VW,SitzMemo_Beifahrer,SitzMemo_Fahrer,PTC_Heizung,Standheizung,Clima,Anhaenger_SG,BSG,FHSG_hinten_rechts,FHSG_hinten_links,TSG_Beifahrer,TSG_Fahrer,Komfort_SG
 SG_ SY1_Verbauliste_gueltig : 7|1@1+ (1,0) [0|1] ""  Reifendruck_VW,SitzMemo_Beifahrer,SitzMemo_Fahrer,Verdeck,PTC_Heizung,Standheizung,Clima,BSG,FHSG_hinten_rechts,FHSG_hinten_links,TSG_Beifahrer,TSG_Fahrer,Komfort_SG
 SG_ SY1_Transportmode : 30|1@1+ (1,0) [0|1] ""  Reifendruck_VW,Reifendruck_Audi,Multifunktions_SG,SMLS,SitzMemo_Beifahrer,SitzMemo_Fahrer,Einparkhilfe,Verdeck,PTC_Heizung,Standheizung,Clima,Anhaenger_SG,BSG,FHSG_hinten_rechts,FHSG_hinten_links,TSG_Beifahrer,TSG_Fahrer,Komfort_SG
 SG_ SY1_Sleep_Komfort : 2|1@1+ (1,0) [0|1] "" Vector__XXX
 SG_ SY1_Sleep_Infotainment : 4|1@1+ (1,0) [0|1] "" Vector__XXX
 SG_ SY1_Rechtslenker : 28|1@1+ (1,0) [0|1] ""  SitzMemo_Beifahrer,SitzMemo_Fahrer,Standheizung,Clima,BSG,TSG_Beifahrer,TSG_Fahrer
 SG_ SY1_Marke : 12|4@1+ (1,0) [0|4] "Tabelle"  Reifendruck_VW,SitzMemo_Beifahrer,SitzMemo_Fahrer,Verdeck,PTC_Heizung,Standheizung,Clima,Anhaenger_SG,BSG,FHSG_hinten_rechts,FHSG_hinten_links,TSG_Beifahrer,TSG_Fahrer,Komfort_SG
 SG_ SY1_Klasse : 8|4@1+ (1,0) [0|9] "Tabelle"  Reifendruck_VW,SitzMemo_Beifahrer,SitzMemo_Fahrer,Verdeck,PTC_Heizung,Standheizung,Clima,Anhaenger_SG,BSG,FHSG_hinten_rechts,FHSG_hinten_links,TSG_Beifahrer,TSG_Fahrer,Komfort_SG
 SG_ SY1_KD_Fehler : 31|1@1+ (1,0) [0|1] "" Vector__XXX
 SG_ SY1_Infotainment : 6|1@1+ (1,0) [0|1] "" Vector__XXX
 SG_ SY1_Generation : 20|4@1+ (1,0) [0|7] "Tabelle"  Reifendruck_VW,SitzMemo_Beifahrer,SitzMemo_Fahrer,Verdeck,PTC_Heizung,Standheizung,Clima,Anhaenger_SG,BSG,FHSG_hinten_rechts,FHSG_hinten_links,TSG_Beifahrer,TSG_Fahrer,Komfort_SG
 SG_ SY1_Erweiterung : 24|4@1+ (1,0) [0|9] "Tabelle"  Reifendruck_VW,SitzMemo_Beifahrer,SitzMemo_Fahrer,Verdeck,PTC_Heizung,Standheizung,Clima,BSG,FHSG_hinten_rechts,FHSG_hinten_links,TSG_Beifahrer,TSG_Fahrer,Komfort_SG
 SG_ SY1_Diag_Komfort : 3|1@1+ (1,0) [0|1] ""  Reifendruck_VW,SitzMemo_Beifahrer,SitzMemo_Fahrer,Verdeck,PTC_Heizung,Standheizung,Clima,BSG,FHSG_hinten_rechts,FHSG_hinten_links,TSG_Beifahrer,TSG_Fahrer,Komfort_SG
 SG_ SY1_Diag_Infotainment : 5|1@1+ (1,0) [0|1] "" Vector__XXX
 SG_ SY1_Diag_Antrieb : 1|1@1+ (1,0) [0|1] "" Vector__XXX
 SG_ SY1_Derivat : 16|4@1+ (1,0) [0|9] "Tabelle"  Reifendruck_VW,SitzMemo_Beifahrer,SitzMemo_Fahrer,Verdeck,PTC_Heizung,Standheizung,Clima,Anhaenger_SG,BSG,FHSG_hinten_rechts,FHSG_hinten_links,TSG_Beifahrer,TSG_Fahrer,Komfort_SG
 SG_ SY1_CAN_Extern : 0|1@1+ (1,0) [0|1] ""  Reifendruck_VW,Clima

BO_ 997 mStHeizung_1: 5 Standheizung
 SG_ SH1_ZusatzHeizung : 10|1@1+ (1,0) [0|1] ""  Gateway_K
 SG_ SH1_SH_Modus : 5|1@1+ (1,0) [0|1] ""  Clima
 SG_ SH1_Prog_Modus : 6|1@1+ (1,0) [0|1] ""  Gateway_K
 SG_ SH1_LED : 9|1@1+ (1,0) [0|1] ""  BSG,Gateway_K
 SG_ SH1_KD_Fehler : 15|1@1+ (1,0) [0|1] ""  Gateway_K
 SG_ SH1_K_Verbrauch : 16|14@1+ (1,0) [0|8191] "ml"  Gateway_K
 SG_ SH1_K_Fehler : 31|1@1+ (1,0) [0|1] ""  Gateway_K
 SG_ SH1_Heizleistung : 32|8@1+ (1,0) [0|255] ""  Clima
 SG_ SH1_Geblaese : 8|1@1+ (1,0) [0|1] ""  Clima,BSG,Komfort_SG
 SG_ SH1_FunkStLftg : 3|1@1+ (1,0) [0|1] ""  Clima
 SG_ SH1_FunkSH_Ein : 2|1@1+ (1,0) [0|1] ""  Clima
 SG_ SH1_Funk_ein : 0|1@1+ (1,0) [0|1] ""  Clima,Gateway_K
 SG_ SH1_Funk_aus : 1|1@1+ (1,0) [0|1] ""  Clima,Gateway_K
 SG_ SH1_Fehlerstatus : 12|3@1+ (1,0) [0|7] ""  Clima,Gateway_K

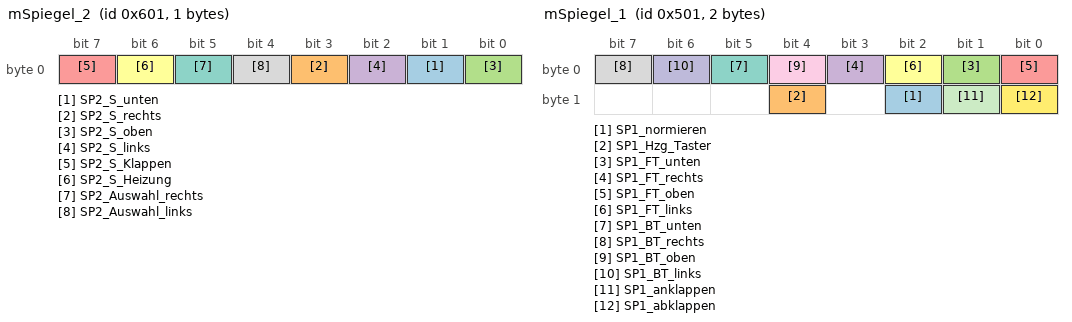
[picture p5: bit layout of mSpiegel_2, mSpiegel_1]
BO_ 1537 mSpiegel_2: 1 TSG_Fahrer
 SG_ SP2_S_unten : 1|1@1+ (1,0) [0|1] "" Vector__XXX
 SG_ SP2_S_rechts : 3|1@1+ (1,0) [0|1] ""  SitzMemo_Fahrer
 SG_ SP2_S_oben : 0|1@1+ (1,0) [0|1] "" Vector__XXX
 SG_ SP2_S_links : 2|1@1+ (1,0) [0|1] "" Vector__XXX
 SG_ SP2_S_Klappen : 7|1@1+ (1,0) [0|1] "" Vector__XXX
 SG_ SP2_S_Heizung : 6|1@1+ (1,0) [0|1] ""  BSG
 SG_ SP2_Auswahl_rechts : 5|1@1+ (1,0) [0|1] ""  TSG_Beifahrer
 SG_ SP2_Auswahl_links : 4|1@1+ (1,0) [0|1] ""  TSG_Beifahrer

BO_ 1281 mSpiegel_1: 2 TSG_Fahrer
 SG_ SP1_normieren : 10|1@1+ (1,0) [0|1] ""  TSG_Beifahrer
 SG_ SP1_Hzg_Taster : 12|1@1+ (1,0) [0|1] ""  BSG,TSG_Beifahrer
 SG_ SP1_FT_unten : 1|1@1+ (1,0) [0|1] ""  TSG_Beifahrer
 SG_ SP1_FT_rechts : 3|1@1+ (1,0) [0|1] ""  TSG_Beifahrer
 SG_ SP1_FT_oben : 0|1@1+ (1,0) [0|1] ""  TSG_Beifahrer
 SG_ SP1_FT_links : 2|1@1+ (1,0) [0|1] ""  TSG_Beifahrer
 SG_ SP1_BT_unten : 5|1@1+ (1,0) [0|1] ""  TSG_Beifahrer
 SG_ SP1_BT_rechts : 7|1@1+ (1,0) [0|1] ""  TSG_Beifahrer
 SG_ SP1_BT_oben : 4|1@1+ (1,0) [0|1] ""  TSG_Beifahrer
 SG_ SP1_BT_links : 6|1@1+ (1,0) [0|1] ""  TSG_Beifahrer
 SG_ SP1_anklappen : 9|1@1+ (1,0) [0|1] ""  TSG_Beifahrer
 SG_ SP1_abklappen : 8|1@1+ (1,0) [0|1] ""  TSG_Beifahrer

BO_ 1621 mSollverbau_neu: 8 Gateway_K
 SG_ VBN_VSG_K : 40|1@1+ (1,0) [0|1] ""  Verdeck,BSG
 SG_ VBN_TV_Tuner_I : 60|1@1+ (1,0) [0|1] "" Vector__XXX
 SG_ VBN_TSG_HR_K : 29|1@1+ (1,0) [0|1] ""  BSG,FHSG_hinten_rechts,Komfort_SG
 SG_ VBN_TSG_HL_K : 28|1@1+ (1,0) [0|1] ""  BSG,FHSG_hinten_links,Komfort_SG
 SG_ VBN_TSG_FT_K : 26|1@1+ (1,0) [0|1] ""  BSG,TSG_Fahrer,Komfort_SG
 SG_ VBN_TSG_BT_K : 27|1@1+ (1,0) [0|1] ""  BSG,TSG_Beifahrer,Komfort_SG
 SG_ VBN_Telematik_I : 58|1@1+ (1,0) [0|1] "" Vector__XXX
 SG_ VBN_Telefon_I : 63|1@1+ (1,0) [0|1] "" Vector__XXX
 SG_ VBN_Standhzg_K : 39|1@1+ (1,0) [0|1] ""  Standheizung,BSG
 SG_ VBN_Spracheingabe_I : 61|1@1+ (1,0) [0|1] "" Vector__XXX
 SG_ VBN_Sonderfahrzeug_SG_K : 50|1@1+ (1,0) [0|1] "" Vector__XXX
 SG_ VBN_Soll_Ist_OK : 23|1@1+ (1,0) [0|1] ""  Verdeck,TSG_Fahrer,TSG_Beifahrer,Standheizung,SMLS,SitzMemo_Fahrer,SitzMemo_Beifahrer,Reifendruck_VW,PTC_Heizung,Multifunktions_SG,Komfort_SG,FHSG_hinten_rechts,FHSG_hinten_links,Einparkhilfe,BSG,Anhaenger_SG
 SG_ VBN_SMLS_K : 34|1@1+ (1,0) [0|1] ""  SMLS,BSG
 SG_ VBN_RDK_K : 33|1@1+ (1,0) [0|1] ""  Reifendruck_VW
 SG_ VBN_Radio_I : 62|1@1+ (1,0) [0|1] "" Vector__XXX
 SG_ VBN_PTC_Heizung_K : 38|1@1+ (1,0) [0|1] ""  PTC_Heizung,Standheizung,BSG
 SG_ VBN_Navigation_I : 59|1@1+ (1,0) [0|1] "" Vector__XXX
 SG_ VBN_Motor_A : 0|1@1+ (1,0) [0|1] "" Vector__XXX
 SG_ VBN_Memory_K : 30|1@1+ (1,0) [0|1] ""  TSG_Fahrer,TSG_Beifahrer,SitzMemo_Fahrer,BSG
 SG_ VBN_Mem_BF_K : 45|1@1+ (1,0) [0|1] ""  SitzMemo_Beifahrer,BSG
 SG_ VBN_LSM_A : 4|1@1+ (1,0) [0|1] ""  BSG
 SG_ VBN_Lenkhilfe_A : 6|1@1+ (1,0) [0|1] ""  BSG
 SG_ VBN_KSG_K : 25|1@1+ (1,0) [0|1] ""  BSG
 SG_ VBN_Kombi_A : 3|1@1+ (1,0) [0|1] "" Vector__XXX
 SG_ VBN_Getriebe_A : 1|1@1+ (1,0) [0|1] ""  BSG
 SG_ VBN_Gateway_K : 35|1@1+ (1,0) [0|1] ""  BSG
 SG_ VBN_dyn_LWR_A : 7|1@1+ (1,0) [0|1] "" Vector__XXX
 SG_ VBN_DSP_I : 56|1@1+ (1,0) [0|1] "" Vector__XXX
 SG_ VBN_Clima_K : 36|1@1+ (1,0) [0|1] ""  BSG
 SG_ VBN_BSG_K : 24|1@1+ (1,0) [0|1] ""  BSG
 SG_ VBN_Bremse_A : 2|1@1+ (1,0) [0|1] ""  TSG_Fahrer
 SG_ VBN_APS_K : 37|1@1+ (1,0) [0|1] ""  Einparkhilfe
 SG_ VBN_Allrad_A : 9|1@1+ (1,0) [0|1] "" Vector__XXX
 SG_ VBN_Airbag_A : 5|1@1+ (1,0) [0|1] ""  BSG,Komfort_SG
 SG_ VBN_AAG_K : 44|1@1+ (1,0) [0|1] ""  Einparkhilfe,BSG

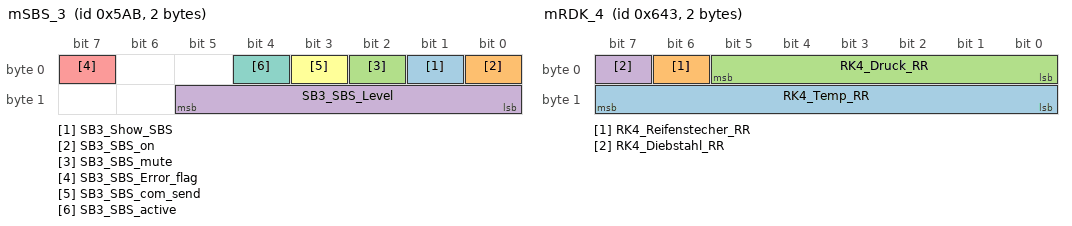
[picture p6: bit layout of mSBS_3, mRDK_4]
BO_ 1451 mSBS_3: 2 Gateway_K
 SG_ SB3_Show_SBS : 1|1@1+ (1,0) [0|1] "" Vector__XXX
 SG_ SB3_SBS_on : 0|1@1+ (1,0) [0|1] ""  SMLS
 SG_ SB3_SBS_mute : 2|1@1+ (1,0) [0|1] "" Vector__XXX
 SG_ SB3_SBS_Level : 8|6@1+ (1,0) [0|63] "" Vector__XXX
 SG_ SB3_SBS_Error_flag : 7|1@1+ (1,0) [0|1] "" Vector__XXX
 SG_ SB3_SBS_com_send : 3|1@1+ (1,0) [0|1] "" Vector__XXX
 SG_ SB3_SBS_active : 4|1@1+ (1,0) [0|1] ""  SMLS,Clima

BO_ 1603 mRDK_4: 2 Reifendruck_VW
 SG_ RK4_Temp_RR : 8|8@1+ (1,-60) [-60|194] "°C" Vector__XXX
 SG_ RK4_Reifenstecher_RR : 6|1@1+ (1,0) [0|1] "" Vector__XXX
 SG_ RK4_Druck_RR : 0|6@1+ (0.1,0) [0|6.3] "bar" Vector__XXX
 SG_ RK4_Diebstahl_RR : 7|1@1+ (1,0) [0|1] "" Vector__XXX

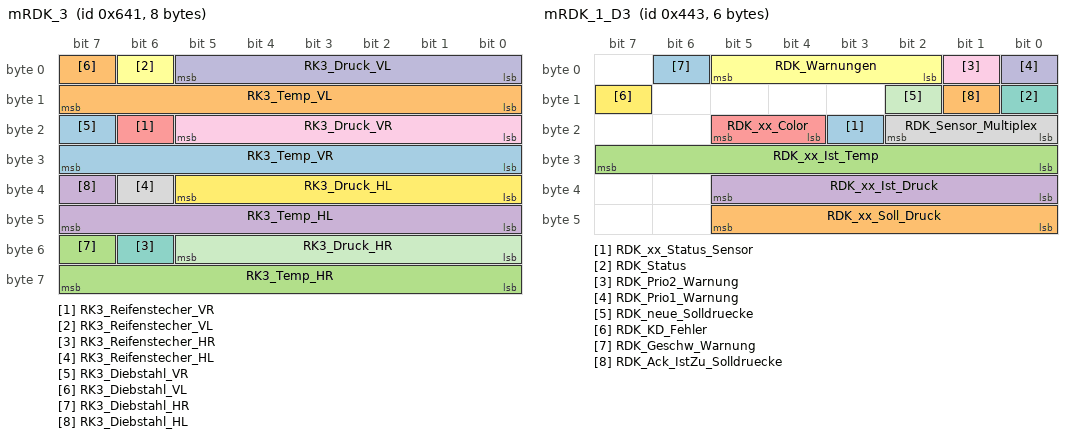
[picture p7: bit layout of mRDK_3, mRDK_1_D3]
BO_ 1601 mRDK_3: 8 Reifendruck_VW
 SG_ RK3_Temp_VR : 24|8@1+ (1,-60) [-60|194] "°C" Vector__XXX
 SG_ RK3_Temp_VL : 8|8@1+ (1,-60) [-60|194] "°C" Vector__XXX
 SG_ RK3_Temp_HR : 56|8@1+ (1,-60) [-60|194] "°C" Vector__XXX
 SG_ RK3_Temp_HL : 40|8@1+ (1,-60) [-60|194] "°C" Vector__XXX
 SG_ RK3_Reifenstecher_VR : 22|1@1+ (1,0) [0|1] "" Vector__XXX
 SG_ RK3_Reifenstecher_VL : 6|1@1+ (1,0) [0|1] "" Vector__XXX
 SG_ RK3_Reifenstecher_HR : 54|1@1+ (1,0) [0|1] "" Vector__XXX
 SG_ RK3_Reifenstecher_HL : 38|1@1+ (1,0) [0|1] "" Vector__XXX
 SG_ RK3_Druck_VR : 16|6@1+ (0.1,0) [0|6.3] "bar" Vector__XXX
 SG_ RK3_Druck_VL : 0|6@1+ (0.1,0) [0|6.3] "bar" Vector__XXX
 SG_ RK3_Druck_HR : 48|6@1+ (0.1,0) [0|6.3] "bar" Vector__XXX
 SG_ RK3_Druck_HL : 32|6@1+ (0.1,0) [0|6.3] "bar" Vector__XXX
 SG_ RK3_Diebstahl_VR : 23|1@1+ (1,0) [0|1] "" Vector__XXX
 SG_ RK3_Diebstahl_VL : 7|1@1+ (1,0) [0|1] "" Vector__XXX
 SG_ RK3_Diebstahl_HR : 55|1@1+ (1,0) [0|1] "" Vector__XXX
 SG_ RK3_Diebstahl_HL : 39|1@1+ (1,0) [0|1] "" Vector__XXX

BO_ 833 mRDK_2: 5 Reifendruck_VW
 SG_ RK2_Warnung_2 : 5|1@1+ (1,0) [0|1] ""  Gateway_K
 SG_ RK2_Warnung_1 : 6|1@1+ (1,0) [0|1] ""  Gateway_K
 SG_ RK2_Text_5 : 20|1@1+ (1,0) [0|1] ""  Gateway_K
 SG_ RK2_Text_3 : 18|1@1+ (1,0) [0|1] ""  Gateway_K
 SG_ RK2_Text_2 : 17|1@1+ (1,0) [0|1] ""  Gateway_K
 SG_ RK2_Text_1 : 16|1@1+ (1,0) [0|1] ""  Gateway_K
 SG_ RK2_Sytem_Aus : 13|1@1+ (1,0) [0|1] ""  Gateway_K
 SG_ RK2_Systemfehler : 7|1@1+ (1,0) [0|1] ""  Gateway_K
 SG_ RK2_Reifen_VR : 1|1@1+ (1,0) [0|1] ""  Gateway_K
 SG_ RK2_Reifen_VL : 0|1@1+ (1,0) [0|1] ""  Gateway_K
 SG_ RK2_Reifen_RR : 4|1@1+ (1,0) [0|1] ""  Gateway_K
 SG_ RK2_Reifen_HR : 3|1@1+ (1,0) [0|1] ""  Gateway_K
 SG_ RK2_Reifen_HL : 2|1@1+ (1,0) [0|1] ""  Gateway_K
 SG_ RK2_KD_Fehler : 15|1@1+ (1,0) [0|1] ""  Gateway_K
 SG_ RK2_Kalibrier_abgew : 8|1@1+ (1,0) [0|1] ""  Gateway_K
 SG_ RK2_Gelaendedruck : 14|1@1+ (1,0) [0|1] ""  Gateway_K
 SG_ RK2_Funkstoerung : 12|1@1+ (1,0) [0|1] ""  Gateway_K
 SG_ RK2_Druckdiff_Vorn : 9|1@1+ (1,0) [0|1] ""  Gateway_K
 SG_ RK2_Druckdiff_Hinten : 10|1@1+ (1,0) [0|1] ""  Gateway_K
 SG_ RK2_Befuellung_RR_low : 11|1@1+ (1,0) [0|1] ""  Gateway_K

BO_ 1091 mRDK_1_D3: 6 Reifendruck_Audi
 SG_ RDK_xx_Status_Sensor : 19|1@1+ (1,0) [0|1] ""  Gateway_K
 SG_ RDK_xx_Soll_Druck : 40|6@1+ (0.1,0) [0|6.3] "bar"  Gateway_K
 SG_ RDK_xx_Ist_Temp : 24|8@1+ (1,-60) [-60|194] "°C"  Gateway_K
 SG_ RDK_xx_Ist_Druck : 32|6@1+ (0.1,0) [0|6.3] "bar"  Gateway_K
 SG_ RDK_xx_Color : 20|2@1+ (1,0) [0|2] ""  Gateway_K
 SG_ RDK_Warnungen : 2|4@1+ (1,0) [0|1] ""  Gateway_K
 SG_ RDK_Status : 8|1@1+ (1,0) [0|1] ""  Gateway_K
 SG_ RDK_Sensor_Multiplex : 16|3@1+ (1,0) [0|4] ""  Gateway_K
 SG_ RDK_Prio2_Warnung : 1|1@1+ (1,0) [0|1] ""  Gateway_K
 SG_ RDK_Prio1_Warnung : 0|1@1+ (1,0) [0|1] ""  Gateway_K
 SG_ RDK_neue_Solldruecke : 10|1@1+ (1,0) [0|1] ""  Gateway_K
 SG_ RDK_KD_Fehler : 15|1@1+ (1,0) [0|1] ""  Gateway_K
 SG_ RDK_Geschw_Warnung : 6|1@1+ (1,0) [0|1] ""  Gateway_K
 SG_ RDK_Ack_IstZu_Solldruecke : 9|1@1+ (1,0) [0|1] ""  Gateway_K

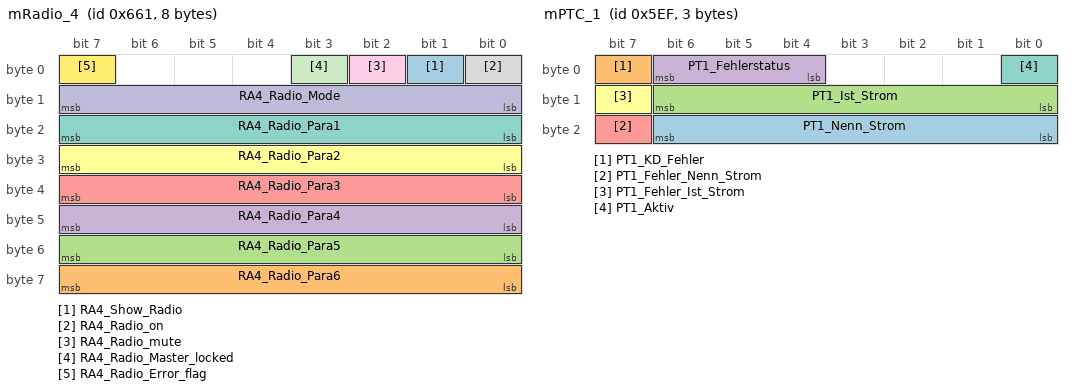
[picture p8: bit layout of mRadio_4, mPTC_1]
BO_ 1633 mRadio_4: 8 Gateway_K
 SG_ RA4_Show_Radio : 1|1@1+ (1,0) [0|1] "" Vector__XXX
 SG_ RA4_Radio_Para6 : 56|8@1+ (1,0) [0|255] "" Vector__XXX
 SG_ RA4_Radio_Para5 : 48|8@1+ (1,0) [0|255] "" Vector__XXX
 SG_ RA4_Radio_Para4 : 40|8@1+ (1,0) [0|255] "" Vector__XXX
 SG_ RA4_Radio_Para3 : 32|8@1+ (1,0) [0|255] "" Vector__XXX
 SG_ RA4_Radio_Para2 : 24|8@1+ (1,0) [0|255] "" Vector__XXX
 SG_ RA4_Radio_Para1 : 16|8@1+ (1,0) [0|255] "" Vector__XXX
 SG_ RA4_Radio_on : 0|1@1+ (1,0) [0|1] ""  SMLS
 SG_ RA4_Radio_mute : 2|1@1+ (1,0) [0|1] "" Vector__XXX
 SG_ RA4_Radio_Mode : 8|8@1+ (1,0) [0|255] "" Vector__XXX
 SG_ RA4_Radio_Master_locked : 3|1@1+ (1,0) [0|1] "" Vector__XXX
 SG_ RA4_Radio_Error_flag : 7|1@1+ (1,0) [0|1] "" Vector__XXX

BO_ 1519 mPTC_1: 3 PTC_Heizung
 SG_ PT1_Nenn_Strom : 16|7@1+ (1,0) [0|127] "A"  BSG
 SG_ PT1_KD_Fehler : 7|1@1+ (1,0) [0|1] ""  Gateway_K
 SG_ PT1_Ist_Strom : 8|7@1+ (1,0) [0|127] "A"  BSG
 SG_ PT1_Fehlerstatus : 4|3@1+ (1,0) [0|7] ""  Clima
 SG_ PT1_Fehler_Nenn_Strom : 23|1@1+ (1,0) [0|1] ""  BSG
 SG_ PT1_Fehler_Ist_Strom : 15|1@1+ (1,0) [0|1] ""  BSG
 SG_ PT1_Aktiv : 0|1@1+ (1,0) [0|1] ""  Clima,BSG

BO_ 1349 mParkhilfe_3: 4 Einparkhilfe
 SG_ PA3_Tongeber_v_defekt : 5|1@1+ (1,0) [0|1] "" Vector__XXX
 SG_ PA3_Tongeber_h_defekt : 6|1@1+ (1,0) [0|1] "" Vector__XXX
 SG_ PA3_Taster_aktiviert : 2|1@1+ (1,0) [0|1] "" Vector__XXX
 SG_ PA3_System_codierung : 0|1@1+ (1,0) [0|1] "" Vector__XXX
 SG_ PA3_Sensor_vrr_defekt : 23|1@1+ (1,0) [0|1] "" Vector__XXX
 SG_ PA3_Sensor_vrm_defekt : 22|1@1+ (1,0) [0|1] "" Vector__XXX
 SG_ PA3_Sensor_vlm_defekt : 21|1@1+ (1,0) [0|1] "" Vector__XXX
 SG_ PA3_Sensor_vll_defekt : 20|1@1+ (1,0) [0|1] "" Vector__XXX
 SG_ PA3_Sensor_hrr_defekt : 19|1@1+ (1,0) [0|1] "" Vector__XXX
 SG_ PA3_Sensor_hrm_defekt : 18|1@1+ (1,0) [0|1] "" Vector__XXX
 SG_ PA3_Sensor_hlm_defekt : 17|1@1+ (1,0) [0|1] "" Vector__XXX
 SG_ PA3_Sensor_hll_defekt : 16|1@1+ (1,0) [0|1] "" Vector__XXX
 SG_ PA3_Schlechtweg_aus : 9|1@1+ (1,0) [0|1] "" Vector__XXX
 SG_ PA3_Rueckwaertsgang_aktiv : 3|1@1+ (1,0) [0|1] "" Vector__XXX
 SG_ PA3_KD_Fehler : 15|1@1+ (1,0) [0|1] ""  Gateway_K
 SG_ PA3_Geschwindigkeit_aus : 4|1@1+ (1,0) [0|1] "" Vector__XXX
 SG_ PA3_Eis_aus : 8|1@1+ (1,0) [0|1] "" Vector__XXX
 SG_ PA3_Bereit : 24|1@1+ (1,0) [0|1] "" Vector__XXX
 SG_ PA3_Bereich_vo : 26|2@1+ (1,0) [0|3] "" Vector__XXX
 SG_ PA3_Bereich_hi : 28|2@1+ (1,0) [0|3] "" Vector__XXX
 SG_ PA3_Aufbau_erk : 31|1@1+ (1,0) [0|1] "" Vector__XXX
 SG_ PA3_Anlage_defekt : 1|1@1+ (1,0) [0|1] "" Vector__XXX
 SG_ PA3_Akust_aus : 30|1@1+ (1,0) [0|1] "" Vector__XXX

BO_ 1025 mNM_ZKE: 6 Komfort_SG
 SG_ NMZK_ZK_Neigungssensor : 42|1@1+ (1,0) [0|0] ""  Komfort_SG
 SG_ NMZK_SleepInd : 12|1@1+ (1,0) [0|0] ""  Reifendruck_VW,Reifendruck_Audi,Multifunktions_SG,SMLS,SitzMemo_Beifahrer,SitzMemo_Fahrer,Einparkhilfe,Verdeck,PTC_Heizung,Standheizung,Clima,Anhaenger_SG,BSG,FHSG_hinten_rechts,FHSG_hinten_links,TSG_Beifahrer,TSG_Fahrer,Komfort_SG,Gateway_K
 SG_ NMZK_SleepAck : 13|1@1+ (1,0) [0|0] ""  Reifendruck_VW,Reifendruck_Audi,Multifunktions_SG,SMLS,SitzMemo_Beifahrer,SitzMemo_Fahrer,Einparkhilfe,Verdeck,PTC_Heizung,Standheizung,Clima,Anhaenger_SG,BSG,FHSG_hinten_rechts,FHSG_hinten_links,TSG_Beifahrer,TSG_Fahrer,Komfort_SG,Gateway_K
 SG_ NMZK_Receiver : 0|8@1+ (1,0) [0|0] ""  Reifendruck_VW,Reifendruck_Audi,Multifunktions_SG,SMLS,SitzMemo_Beifahrer,SitzMemo_Fahrer,Einparkhilfe,Verdeck,PTC_Heizung,Standheizung,Clima,Anhaenger_SG,BSG,FHSG_hinten_rechts,FHSG_hinten_links,TSG_Beifahrer,TSG_Fahrer,Komfort_SG,Gateway_K
 SG_ NMZK_NWake : 22|1@1+ (1,0) [0|0] ""  Komfort_SG
 SG_ NMZK_Kl_30_Reset : 20|1@1+ (1,0) [0|0] ""  Komfort_SG
 SG_ NMZK_IRUE_Ausloesung : 31|1@1+ (1,0) [0|0] ""  Komfort_SG
 SG_ NMZK_HD_Vorraste : 36|1@1+ (1,0) [0|0] ""  Komfort_SG
 SG_ NMZK_HD_Taster : 26|1@1+ (1,0) [0|0] ""  Komfort_SG
 SG_ NMZK_HD_Schloss_zu : 25|1@1+ (1,0) [0|0] ""  Komfort_SG
 SG_ NMZK_HD_Schloss_auf : 24|1@1+ (1,0) [0|0] ""  Komfort_SG
 SG_ NMZK_HD_Hauptraste : 37|1@1+ (1,0) [0|0] ""  Komfort_SG
 SG_ NMZK_Fond_Lock : 44|1@1+ (1,0) [0|0] ""  Komfort_SG
 SG_ NMZK_Fkt_Nachlauf : 21|1@1+ (1,0) [0|0] ""  Komfort_SG
 SG_ NMZK_CmdRing : 8|1@1+ (1,0) [0|0] ""  Reifendruck_VW,Reifendruck_Audi,Multifunktions_SG,SMLS,SitzMemo_Beifahrer,SitzMemo_Fahrer,Einparkhilfe,Verdeck,PTC_Heizung,Standheizung,Clima,Anhaenger_SG,BSG,FHSG_hinten_rechts,FHSG_hinten_links,TSG_Beifahrer,TSG_Fahrer,Komfort_SG,Gateway_K
 SG_ NMZK_CmdLimpHome : 10|1@1+ (1,0) [0|0] ""  Reifendruck_VW,Reifendruck_Audi,Multifunktions_SG,SMLS,SitzMemo_Beifahrer,SitzMemo_Fahrer,Einparkhilfe,Verdeck,PTC_Heizung,Standheizung,Clima,Anhaenger_SG,BSG,FHSG_hinten_rechts,FHSG_hinten_links,TSG_Beifahrer,TSG_Fahrer,Komfort_SG,Gateway_K
 SG_ NMZK_CmdAlive : 9|1@1+ (1,0) [0|0] ""  Reifendruck_VW,Reifendruck_Audi,Multifunktions_SG,SMLS,SitzMemo_Beifahrer,SitzMemo_Fahrer,Einparkhilfe,Verdeck,PTC_Heizung,Standheizung,Clima,Anhaenger_SG,BSG,FHSG_hinten_rechts,FHSG_hinten_links,TSG_Beifahrer,TSG_Fahrer,Komfort_SG,Gateway_K
 SG_ NMZK_CAN : 23|1@1+ (1,0) [0|0] ""  Komfort_SG
 SG_ NMZK_Bremslicht : 46|1@1+ (1,0) [0|0] ""  Komfort_SG

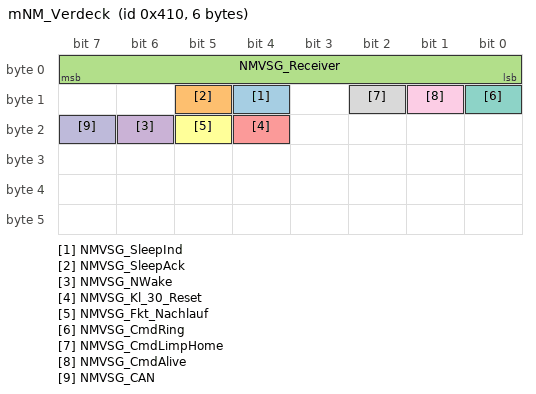
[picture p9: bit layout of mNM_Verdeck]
BO_ 1040 mNM_Verdeck: 6 Verdeck
 SG_ NMVSG_SleepInd : 12|1@1+ (1,0) [0|0] ""  Reifendruck_VW,Reifendruck_Audi,Multifunktions_SG,SMLS,SitzMemo_Beifahrer,SitzMemo_Fahrer,Einparkhilfe,Verdeck,PTC_Heizung,Standheizung,Clima,Anhaenger_SG,BSG,FHSG_hinten_rechts,FHSG_hinten_links,TSG_Beifahrer,TSG_Fahrer,Komfort_SG,Gateway_K
 SG_ NMVSG_SleepAck : 13|1@1+ (1,0) [0|0] ""  Reifendruck_VW,Reifendruck_Audi,Multifunktions_SG,SMLS,SitzMemo_Beifahrer,SitzMemo_Fahrer,Einparkhilfe,Verdeck,PTC_Heizung,Standheizung,Clima,Anhaenger_SG,BSG,FHSG_hinten_rechts,FHSG_hinten_links,TSG_Beifahrer,TSG_Fahrer,Komfort_SG,Gateway_K
 SG_ NMVSG_Receiver : 0|8@1+ (1,0) [0|0] ""  Reifendruck_VW,Reifendruck_Audi,Multifunktions_SG,SMLS,SitzMemo_Beifahrer,SitzMemo_Fahrer,Einparkhilfe,Verdeck,PTC_Heizung,Standheizung,Clima,Anhaenger_SG,BSG,FHSG_hinten_rechts,FHSG_hinten_links,TSG_Beifahrer,TSG_Fahrer,Komfort_SG,Gateway_K
 SG_ NMVSG_NWake : 22|1@1+ (1,0) [0|0] ""  Verdeck
 SG_ NMVSG_Kl_30_Reset : 20|1@1+ (1,0) [0|0] ""  Verdeck
 SG_ NMVSG_Fkt_Nachlauf : 21|1@1+ (1,0) [0|0] ""  Verdeck
 SG_ NMVSG_CmdRing : 8|1@1+ (1,0) [0|0] ""  Reifendruck_VW,Reifendruck_Audi,Multifunktions_SG,SMLS,SitzMemo_Beifahrer,SitzMemo_Fahrer,Einparkhilfe,Verdeck,PTC_Heizung,Standheizung,Clima,Anhaenger_SG,BSG,FHSG_hinten_rechts,FHSG_hinten_links,TSG_Beifahrer,TSG_Fahrer,Komfort_SG,Gateway_K
 SG_ NMVSG_CmdLimpHome : 10|1@1+ (1,0) [0|0] ""  Reifendruck_VW,Reifendruck_Audi,Multifunktions_SG,SMLS,SitzMemo_Beifahrer,SitzMemo_Fahrer,Einparkhilfe,Verdeck,PTC_Heizung,Standheizung,Clima,Anhaenger_SG,BSG,FHSG_hinten_rechts,FHSG_hinten_links,TSG_Beifahrer,TSG_Fahrer,Komfort_SG,Gateway_K
 SG_ NMVSG_CmdAlive : 9|1@1+ (1,0) [0|0] ""  Reifendruck_VW,Reifendruck_Audi,Multifunktions_SG,SMLS,SitzMemo_Beifahrer,SitzMemo_Fahrer,Einparkhilfe,Verdeck,PTC_Heizung,Standheizung,Clima,Anhaenger_SG,BSG,FHSG_hinten_rechts,FHSG_hinten_links,TSG_Beifahrer,TSG_Fahrer,Komfort_SG,Gateway_K
 SG_ NMVSG_CAN : 23|1@1+ (1,0) [0|0] ""  Verdeck

BO_ 1029 mNM_TSG_HR: 6 FHSG_hinten_rechts
 SG_ NMHR_Verr_Zustand : 38|1@1+ (1,0) [0|0] ""  FHSG_hinten_rechts
 SG_ NMHR_Verr_Taster : 32|1@1+ (1,0) [0|0] ""  FHSG_hinten_rechts
 SG_ NMHR_Unlock : 24|1@1+ (1,0) [0|0] ""  FHSG_hinten_rechts
 SG_ NMHR_Tuergriff_Innern : 29|1@1+ (1,0) [0|0] ""  FHSG_hinten_rechts
 SG_ NMHR_Tuergriff_Aussen : 30|1@1+ (1,0) [0|0] ""  FHSG_hinten_rechts
 SG_ NMHR_SleepInd : 12|1@1+ (1,0) [0|0] ""  Reifendruck_VW,Reifendruck_Audi,Multifunktions_SG,SMLS,SitzMemo_Beifahrer,SitzMemo_Fahrer,Einparkhilfe,Verdeck,PTC_Heizung,Standheizung,Clima,Anhaenger_SG,BSG,FHSG_hinten_rechts,FHSG_hinten_links,TSG_Beifahrer,TSG_Fahrer,Komfort_SG,Gateway_K
 SG_ NMHR_SleepAck : 13|1@1+ (1,0) [0|0] ""  Reifendruck_VW,Reifendruck_Audi,Multifunktions_SG,SMLS,SitzMemo_Beifahrer,SitzMemo_Fahrer,Einparkhilfe,Verdeck,PTC_Heizung,Standheizung,Clima,Anhaenger_SG,BSG,FHSG_hinten_rechts,FHSG_hinten_links,TSG_Beifahrer,TSG_Fahrer,Komfort_SG,Gateway_K
 SG_ NMHR_Safe_Zustand : 39|1@1+ (1,0) [0|0] ""  FHSG_hinten_rechts
 SG_ NMHR_Receiver : 0|8@1+ (1,0) [0|0] ""  Reifendruck_VW,Reifendruck_Audi,Multifunktions_SG,SMLS,SitzMemo_Beifahrer,SitzMemo_Fahrer,Einparkhilfe,Verdeck,PTC_Heizung,Standheizung,Clima,Anhaenger_SG,BSG,FHSG_hinten_rechts,FHSG_hinten_links,TSG_Beifahrer,TSG_Fahrer,Komfort_SG,Gateway_K
 SG_ NMHR_PTT_Taste : 33|1@1+ (1,0) [0|0] ""  FHSG_hinten_rechts
 SG_ NMHR_NWake : 22|1@1+ (1,0) [0|0] ""  FHSG_hinten_rechts
 SG_ NMHR_Lock : 25|1@1+ (1,0) [0|0] ""  FHSG_hinten_rechts
 SG_ NMHR_Kl_30_Reset : 20|1@1+ (1,0) [0|0] ""  FHSG_hinten_rechts
 SG_ NMHR_Fkt_Nachlauf : 21|1@1+ (1,0) [0|0] ""  FHSG_hinten_rechts
 SG_ NMHR_Drehfalle : 26|1@1+ (1,0) [0|0] ""  FHSG_hinten_rechts
 SG_ NMHR_CmdRing : 8|1@1+ (1,0) [0|0] ""  Reifendruck_VW,Reifendruck_Audi,Multifunktions_SG,SMLS,SitzMemo_Beifahrer,SitzMemo_Fahrer,Einparkhilfe,Verdeck,PTC_Heizung,Standheizung,Clima,Anhaenger_SG,BSG,FHSG_hinten_rechts,FHSG_hinten_links,TSG_Beifahrer,TSG_Fahrer,Komfort_SG,Gateway_K
 SG_ NMHR_CmdLimpHome : 10|1@1+ (1,0) [0|0] ""  Reifendruck_VW,Reifendruck_Audi,Multifunktions_SG,SMLS,SitzMemo_Beifahrer,SitzMemo_Fahrer,Einparkhilfe,Verdeck,PTC_Heizung,Standheizung,Clima,Anhaenger_SG,BSG,FHSG_hinten_rechts,FHSG_hinten_links,TSG_Beifahrer,TSG_Fahrer,Komfort_SG,Gateway_K
 SG_ NMHR_CmdAlive : 9|1@1+ (1,0) [0|0] ""  Reifendruck_VW,Reifendruck_Audi,Multifunktions_SG,SMLS,SitzMemo_Beifahrer,SitzMemo_Fahrer,Einparkhilfe,Verdeck,PTC_Heizung,Standheizung,Clima,Anhaenger_SG,BSG,FHSG_hinten_rechts,FHSG_hinten_links,TSG_Beifahrer,TSG_Fahrer,Komfort_SG,Gateway_K
 SG_ NMHR_CAN : 23|1@1+ (1,0) [0|0] ""  FHSG_hinten_rechts

BO_ 1028 mNM_TSG_HL: 6 FHSG_hinten_links
 SG_ NMHL_Verr_Zustand : 38|1@1+ (1,0) [0|0] ""  FHSG_hinten_links
 SG_ NMHL_Verr_Taster : 32|1@1+ (1,0) [0|0] ""  FHSG_hinten_links
 SG_ NMHL_Unlock : 24|1@1+ (1,0) [0|0] ""  FHSG_hinten_links
 SG_ NMHL_Tuergriff_Innern : 29|1@1+ (1,0) [0|0] ""  FHSG_hinten_links
 SG_ NMHL_Tuergriff_Aussen : 30|1@1+ (1,0) [0|0] ""  FHSG_hinten_links
 SG_ NMHL_SleepInd : 12|1@1+ (1,0) [0|0] ""  Reifendruck_VW,Reifendruck_Audi,Multifunktions_SG,SMLS,SitzMemo_Beifahrer,SitzMemo_Fahrer,Einparkhilfe,Verdeck,PTC_Heizung,Standheizung,Clima,Anhaenger_SG,BSG,FHSG_hinten_rechts,FHSG_hinten_links,TSG_Beifahrer,TSG_Fahrer,Komfort_SG,Gateway_K
 SG_ NMHL_SleepAck : 13|1@1+ (1,0) [0|0] ""  Reifendruck_VW,Reifendruck_Audi,Multifunktions_SG,SMLS,SitzMemo_Beifahrer,SitzMemo_Fahrer,Einparkhilfe,Verdeck,PTC_Heizung,Standheizung,Clima,Anhaenger_SG,BSG,FHSG_hinten_rechts,FHSG_hinten_links,TSG_Beifahrer,TSG_Fahrer,Komfort_SG,Gateway_K
 SG_ NMHL_Safe_Zustand : 39|1@1+ (1,0) [0|0] ""  FHSG_hinten_links
 SG_ NMHL_Receiver : 0|8@1+ (1,0) [0|0] ""  Reifendruck_VW,Reifendruck_Audi,Multifunktions_SG,SMLS,SitzMemo_Beifahrer,SitzMemo_Fahrer,Einparkhilfe,Verdeck,PTC_Heizung,Standheizung,Clima,Anhaenger_SG,BSG,FHSG_hinten_rechts,FHSG_hinten_links,TSG_Beifahrer,TSG_Fahrer,Komfort_SG,Gateway_K
 SG_ NMHL_PTT_Taste : 33|1@1+ (1,0) [0|0] ""  FHSG_hinten_links
 SG_ NMHL_NWake : 22|1@1+ (1,0) [0|0] ""  FHSG_hinten_links
 SG_ NMHL_Lock : 25|1@1+ (1,0) [0|0] ""  FHSG_hinten_links
 SG_ NMHL_Kl_30_Reset : 20|1@1+ (1,0) [0|0] ""  FHSG_hinten_links
 SG_ NMHL_Fkt_Nachlauf : 21|1@1+ (1,0) [0|0] ""  FHSG_hinten_links
 SG_ NMHL_Drehfalle : 26|1@1+ (1,0) [0|0] ""  FHSG_hinten_links
 SG_ NMHL_CmdRing : 8|1@1+ (1,0) [0|0] ""  Reifendruck_VW,Reifendruck_Audi,Multifunktions_SG,SMLS,SitzMemo_Beifahrer,SitzMemo_Fahrer,Einparkhilfe,Verdeck,PTC_Heizung,Standheizung,Clima,Anhaenger_SG,BSG,FHSG_hinten_rechts,FHSG_hinten_links,TSG_Beifahrer,TSG_Fahrer,Komfort_SG,Gateway_K
 SG_ NMHL_CmdLimpHome : 10|1@1+ (1,0) [0|0] ""  Reifendruck_VW,Reifendruck_Audi,Multifunktions_SG,SMLS,SitzMemo_Beifahrer,SitzMemo_Fahrer,Einparkhilfe,Verdeck,PTC_Heizung,Standheizung,Clima,Anhaenger_SG,BSG,FHSG_hinten_rechts,FHSG_hinten_links,TSG_Beifahrer,TSG_Fahrer,Komfort_SG,Gateway_K
 SG_ NMHL_CmdAlive : 9|1@1+ (1,0) [0|0] ""  Reifendruck_VW,Reifendruck_Audi,Multifunktions_SG,SMLS,SitzMemo_Beifahrer,SitzMemo_Fahrer,Einparkhilfe,Verdeck,PTC_Heizung,Standheizung,Clima,Anhaenger_SG,BSG,FHSG_hinten_rechts,FHSG_hinten_links,TSG_Beifahrer,TSG_Fahrer,Komfort_SG,Gateway_K
 SG_ NMHL_CAN : 23|1@1+ (1,0) [0|0] ""  FHSG_hinten_links

BO_ 1026 mNM_TSG_FT: 6 TSG_Fahrer
 SG_ NMFT_Verr_Zustand : 38|1@1+ (1,0) [0|0] ""  TSG_Fahrer
 SG_ NMFT_Verr_Taster : 32|1@1+ (1,0) [0|0] ""  TSG_Fahrer
 SG_ NMFT_Unlock : 24|1@1+ (1,0) [0|0] ""  TSG_Fahrer
 SG_ NMFT_Tuergriff_Innern : 29|1@1+ (1,0) [0|0] ""  TSG_Fahrer
 SG_ NMFT_Tuergriff_Aussen : 30|1@1+ (1,0) [0|0] ""  TSG_Fahrer
 SG_ NMFT_Taster_Tankklappe : 40|1@1+ (1,0) [0|0] ""  TSG_Fahrer
 SG_ NMFT_SleepInd : 12|1@1+ (1,0) [0|0] ""  Reifendruck_VW,Reifendruck_Audi,Multifunktions_SG,SMLS,SitzMemo_Beifahrer,SitzMemo_Fahrer,Einparkhilfe,Verdeck,PTC_Heizung,Standheizung,Clima,Anhaenger_SG,BSG,FHSG_hinten_rechts,FHSG_hinten_links,TSG_Beifahrer,TSG_Fahrer,Komfort_SG,Gateway_K
 SG_ NMFT_SleepAck : 13|1@1+ (1,0) [0|0] ""  Reifendruck_VW,Reifendruck_Audi,Multifunktions_SG,SMLS,SitzMemo_Beifahrer,SitzMemo_Fahrer,Einparkhilfe,Verdeck,PTC_Heizung,Standheizung,Clima,Anhaenger_SG,BSG,FHSG_hinten_rechts,FHSG_hinten_links,TSG_Beifahrer,TSG_Fahrer,Komfort_SG,Gateway_K
 SG_ NMFT_Schloss_zu : 28|1@1+ (1,0) [0|0] ""  TSG_Fahrer
 SG_ NMFT_Schloss_auf : 27|1@1+ (1,0) [0|0] ""  TSG_Fahrer
 SG_ NMFT_Safe_Zustand : 39|1@1+ (1,0) [0|0] ""  TSG_Fahrer
 SG_ NMFT_Receiver : 0|8@1+ (1,0) [0|0] ""  Reifendruck_VW,Reifendruck_Audi,Multifunktions_SG,SMLS,SitzMemo_Beifahrer,SitzMemo_Fahrer,Einparkhilfe,Verdeck,PTC_Heizung,Standheizung,Clima,Anhaenger_SG,BSG,FHSG_hinten_rechts,FHSG_hinten_links,TSG_Beifahrer,TSG_Fahrer,Komfort_SG,Gateway_K
 SG_ NMFT_NWake : 22|1@1+ (1,0) [0|0] ""  TSG_Fahrer
 SG_ NMFT_Lock : 25|1@1+ (1,0) [0|0] ""  TSG_Fahrer
 SG_ NMFT_Kl_30_Reset : 20|1@1+ (1,0) [0|0] ""  TSG_Fahrer
 SG_ NMFT_Fkt_Nachlauf : 21|1@1+ (1,0) [0|0] ""  TSG_Fahrer
 SG_ NMFT_FH_Fahrer : 44|1@1+ (1,0) [0|0] ""  TSG_Fahrer
 SG_ NMFT_Drehfalle : 26|1@1+ (1,0) [0|0] ""  TSG_Fahrer
 SG_ NMFT_CmdRing : 8|1@1+ (1,0) [0|0] ""  Reifendruck_VW,Reifendruck_Audi,Multifunktions_SG,SMLS,SitzMemo_Beifahrer,SitzMemo_Fahrer,Einparkhilfe,Verdeck,PTC_Heizung,Standheizung,Clima,Anhaenger_SG,BSG,FHSG_hinten_rechts,FHSG_hinten_links,TSG_Beifahrer,TSG_Fahrer,Komfort_SG,Gateway_K
 SG_ NMFT_CmdLimpHome : 10|1@1+ (1,0) [0|0] ""  Reifendruck_VW,Reifendruck_Audi,Multifunktions_SG,SMLS,SitzMemo_Beifahrer,SitzMemo_Fahrer,Einparkhilfe,Verdeck,PTC_Heizung,Standheizung,Clima,Anhaenger_SG,BSG,FHSG_hinten_rechts,FHSG_hinten_links,TSG_Beifahrer,TSG_Fahrer,Komfort_SG,Gateway_K
 SG_ NMFT_CmdAlive : 9|1@1+ (1,0) [0|0] ""  Reifendruck_VW,Reifendruck_Audi,Multifunktions_SG,SMLS,SitzMemo_Beifahrer,SitzMemo_Fahrer,Einparkhilfe,Verdeck,PTC_Heizung,Standheizung,Clima,Anhaenger_SG,BSG,FHSG_hinten_rechts,FHSG_hinten_links,TSG_Beifahrer,TSG_Fahrer,Komfort_SG,Gateway_K
 SG_ NMFT_CAN : 23|1@1+ (1,0) [0|0] ""  TSG_Fahrer

BO_ 1027 mNM_TSG_BT: 6 TSG_Beifahrer
 SG_ NMBT_Verr_Zustand : 38|1@1+ (1,0) [0|0] ""  TSG_Beifahrer
 SG_ NMBT_Verr_Taster : 32|1@1+ (1,0) [0|0] ""  TSG_Beifahrer
 SG_ NMBT_Unlock : 24|1@1+ (1,0) [0|0] ""  TSG_Beifahrer
 SG_ NMBT_Tuergriff_Innern : 29|1@1+ (1,0) [0|0] ""  TSG_Beifahrer
 SG_ NMBT_Tuergriff_Aussen : 30|1@1+ (1,0) [0|0] ""  TSG_Beifahrer
 SG_ NMBT_SleepInd : 12|1@1+ (1,0) [0|0] ""  Reifendruck_VW,Reifendruck_Audi,Multifunktions_SG,SMLS,SitzMemo_Beifahrer,SitzMemo_Fahrer,Einparkhilfe,Verdeck,PTC_Heizung,Standheizung,Clima,Anhaenger_SG,BSG,FHSG_hinten_rechts,FHSG_hinten_links,TSG_Beifahrer,TSG_Fahrer,Komfort_SG,Gateway_K
 SG_ NMBT_SleepAck : 13|1@1+ (1,0) [0|0] ""  Reifendruck_VW,Reifendruck_Audi,Multifunktions_SG,SMLS,SitzMemo_Beifahrer,SitzMemo_Fahrer,Einparkhilfe,Verdeck,PTC_Heizung,Standheizung,Clima,Anhaenger_SG,BSG,FHSG_hinten_rechts,FHSG_hinten_links,TSG_Beifahrer,TSG_Fahrer,Komfort_SG,Gateway_K
 SG_ NMBT_Schloss_zu : 28|1@1+ (1,0) [0|0] ""  TSG_Beifahrer
 SG_ NMBT_Schloss_auf : 27|1@1+ (1,0) [0|0] ""  TSG_Beifahrer
 SG_ NMBT_Safe_Zustand : 39|1@1+ (1,0) [0|0] ""  TSG_Beifahrer
 SG_ NMBT_Receiver : 0|8@1+ (1,0) [0|0] ""  Reifendruck_VW,Reifendruck_Audi,Multifunktions_SG,SMLS,SitzMemo_Beifahrer,SitzMemo_Fahrer,Einparkhilfe,Verdeck,PTC_Heizung,Standheizung,Clima,Anhaenger_SG,BSG,FHSG_hinten_rechts,FHSG_hinten_links,TSG_Beifahrer,TSG_Fahrer,Komfort_SG,Gateway_K
 SG_ NMBT_PTT_Taster : 33|1@1+ (1,0) [0|0] ""  TSG_Beifahrer
 SG_ NMBT_NWake : 22|1@1+ (1,0) [0|0] ""  TSG_Beifahrer
 SG_ NMBT_Lock : 25|1@1+ (1,0) [0|0] ""  TSG_Beifahrer
 SG_ NMBT_Kl_30_Reset : 20|1@1+ (1,0) [0|0] ""  TSG_Beifahrer
 SG_ NMBT_Fkt_Nachlauf : 21|1@1+ (1,0) [0|0] ""  TSG_Beifahrer
 SG_ NMBT_Drehfalle : 26|1@1+ (1,0) [0|0] ""  TSG_Beifahrer
 SG_ NMBT_CmdRing : 8|1@1+ (1,0) [0|0] ""  Reifendruck_VW,Reifendruck_Audi,Multifunktions_SG,SMLS,SitzMemo_Beifahrer,SitzMemo_Fahrer,Einparkhilfe,Verdeck,PTC_Heizung,Standheizung,Clima,Anhaenger_SG,BSG,FHSG_hinten_rechts,FHSG_hinten_links,TSG_Beifahrer,TSG_Fahrer,Komfort_SG,Gateway_K
 SG_ NMBT_CmdLimpHome : 10|1@1+ (1,0) [0|0] ""  Reifendruck_VW,Reifendruck_Audi,Multifunktions_SG,SMLS,SitzMemo_Beifahrer,SitzMemo_Fahrer,Einparkhilfe,Verdeck,PTC_Heizung,Standheizung,Clima,Anhaenger_SG,BSG,FHSG_hinten_rechts,FHSG_hinten_links,TSG_Beifahrer,TSG_Fahrer,Komfort_SG,Gateway_K
 SG_ NMBT_CmdAlive : 9|1@1+ (1,0) [0|0] ""  Reifendruck_VW,Reifendruck_Audi,Multifunktions_SG,SMLS,SitzMemo_Beifahrer,SitzMemo_Fahrer,Einparkhilfe,Verdeck,PTC_Heizung,Standheizung,Clima,Anhaenger_SG,BSG,FHSG_hinten_rechts,FHSG_hinten_links,TSG_Beifahrer,TSG_Fahrer,Komfort_SG,Gateway_K
 SG_ NMBT_CAN : 23|1@1+ (1,0) [0|0] ""  TSG_Beifahrer

BO_ 1034 mNM_SMLS: 6 SMLS
 SG_ NMLS_SleepInd : 12|1@1+ (1,0) [0|0] ""  Reifendruck_VW,Reifendruck_Audi,Multifunktions_SG,SMLS,SitzMemo_Beifahrer,SitzMemo_Fahrer,Einparkhilfe,Verdeck,PTC_Heizung,Standheizung,Clima,Anhaenger_SG,BSG,FHSG_hinten_rechts,FHSG_hinten_links,TSG_Beifahrer,TSG_Fahrer,Komfort_SG,Gateway_K
 SG_ NMLS_SleepAck : 13|1@1+ (1,0) [0|0] ""  Reifendruck_VW,Reifendruck_Audi,Multifunktions_SG,SMLS,SitzMemo_Beifahrer,SitzMemo_Fahrer,Einparkhilfe,Verdeck,PTC_Heizung,Standheizung,Clima,Anhaenger_SG,BSG,FHSG_hinten_rechts,FHSG_hinten_links,TSG_Beifahrer,TSG_Fahrer,Komfort_SG,Gateway_K
 SG_ NMLS_S_Kontakt_ein_aus : 29|1@1+ (1,0) [0|0] ""  SMLS
 SG_ NMLS_S_Kontakt_aus_ein : 25|1@1+ (1,0) [0|0] ""  SMLS
 SG_ NMLS_Receiver : 0|8@1+ (1,0) [0|0] ""  Reifendruck_VW,Reifendruck_Audi,Multifunktions_SG,SMLS,SitzMemo_Beifahrer,SitzMemo_Fahrer,Einparkhilfe,Verdeck,PTC_Heizung,Standheizung,Clima,Anhaenger_SG,BSG,FHSG_hinten_rechts,FHSG_hinten_links,TSG_Beifahrer,TSG_Fahrer,Komfort_SG,Gateway_K
 SG_ NMLS_Parklicht_ein_aus : 30|1@1+ (1,0) [0|0] ""  SMLS
 SG_ NMLS_Parklicht_aus_ein : 26|1@1+ (1,0) [0|0] ""  SMLS
 SG_ NMLS_NWake : 22|1@1+ (1,0) [0|0] ""  SMLS
 SG_ NMLS_LSV : 33|1@1+ (1,0) [0|0] ""  SMLS
 SG_ NMLS_Lichthupe_ein_aus : 31|1@1+ (1,0) [0|0] ""  SMLS
 SG_ NMLS_Lichthupe_aus_ein : 27|1@1+ (1,0) [0|0] ""  SMLS
 SG_ NMLS_Klemme15 : 24|1@1+ (1,0) [0|0] ""  SMLS
 SG_ NMLS_Kl_30_Reset : 20|1@1+ (1,0) [0|0] ""  SMLS
 SG_ NMLS_Fkt_Nachlauf : 21|1@1+ (1,0) [0|0] ""  SMLS
 SG_ NMLS_CmdRing : 8|1@1+ (1,0) [0|0] ""  Reifendruck_VW,Reifendruck_Audi,Multifunktions_SG,SMLS,SitzMemo_Beifahrer,SitzMemo_Fahrer,Einparkhilfe,Verdeck,PTC_Heizung,Standheizung,Clima,Anhaenger_SG,BSG,FHSG_hinten_rechts,FHSG_hinten_links,TSG_Beifahrer,TSG_Fahrer,Komfort_SG,Gateway_K
 SG_ NMLS_CmdLimpHome : 10|1@1+ (1,0) [0|0] ""  Reifendruck_VW,Reifendruck_Audi,Multifunktions_SG,SMLS,SitzMemo_Beifahrer,SitzMemo_Fahrer,Einparkhilfe,Verdeck,PTC_Heizung,Standheizung,Clima,Anhaenger_SG,BSG,FHSG_hinten_rechts,FHSG_hinten_links,TSG_Beifahrer,TSG_Fahrer,Komfort_SG,Gateway_K
 SG_ NMLS_CmdAlive : 9|1@1+ (1,0) [0|0] ""  Reifendruck_VW,Reifendruck_Audi,Multifunktions_SG,SMLS,SitzMemo_Beifahrer,SitzMemo_Fahrer,Einparkhilfe,Verdeck,PTC_Heizung,Standheizung,Clima,Anhaenger_SG,BSG,FHSG_hinten_rechts,FHSG_hinten_links,TSG_Beifahrer,TSG_Fahrer,Komfort_SG,Gateway_K
 SG_ NMLS_CAN : 23|1@1+ (1,0) [0|0] ""  SMLS

CM_ BO_ 1425 "
Byte 1:Zusatzfunktionen 1
Byte 2:Zusatzfunktionen 2
Byte 3:Systemcodierung
Byte 6:Konfigurationsstatus";
CM_ SG_ 1425 ZK4_ZVOeffnung "Oeffnungsmodus Zentralverriegelung /n'Konfiguriert";
CM_ SG_ 1425 ZK4_verriegelt_int "Fahrzeug verriegelt per Innentaster (Soll) /n1 = F";
CM_ SG_ 1425 ZK4_verriegelt_ext "Fahrzeug verriegelt per Funk/Schl. (Soll) /n1 = Fa";
CM_ SG_ 1425 ZK4_Verdeck_enable "Verdeckbetrieb erlaubt /n1 = Verdeckbetrieb erlaub";
CM_ SG_ 1425 ZK4_Verbau_ZV "Verbau Zentralverriegelung /n1 = ZV verbaut";
CM_ SG_ 1425 ZK4_Verbau_Viertuerer "Verbau Viertuerer /n'1 = Viertuerer; 0 = Zweituere";
CM_ SG_ 1425 ZK4_Verbau_Neigung "Neigungssensor vorhanden /n'1 = Neigungssensor ver";
CM_ SG_ 1425 ZK4_Verbau_eFH_vorn "Verbau elektrische FH vorne /n1 = FH vorn";
CM_ SG_ 1425 ZK4_Verbau_eFH_hinten "Verbau elektrische FH hinten /n1 = FH hinten";
CM_ SG_ 1425 ZK4_Synchro_Spiegel "Synchrone Spiegelverstellung /n1 = Synchronversate";
CM_ SG_ 1425 ZK4_SD_Komfortoeffnen "Komfortoeffnen fuer Schiebedach /n1 = Oeffnen des";
CM_ SG_ 1425 ZK4_Schlosstyp "Art der in den Tueren verbauten Schloessern /nDas";
CM_ SG_ 1425 ZK4_SAD_Freigabe "Freigabe der Funktion SAD /n1 = Funktionsfreigabe";
CM_ SG_ 1425 ZK4_Rechtslenker "Rechtslenker-Fahrzeug /n'1 = Rechtslenker; 0 = Lin";
CM_ SG_ 1425 ZK4_Neigung_aktiv "Neigungssensor aktiv /n'1 = Neigungssensor deaktiv";
CM_ SG_ 1425 ZK4_Komfortfkt_Enable "Enable Komfortoeffnen/-schliessen /n1 = globale Fr";
CM_ SG_ 1425 ZK4_KD_Fehler "Kundendienstfehler /n1 = mindestens 1 Kundendienst";
CM_ SG_ 1425 ZK4_ist_verriegelt_intern "Zustandmeldung Fahrzeug ist verriegelt /n1 = Inter";
CM_ SG_ 1425 ZK4_IRUE_aktiv "Innenraumueberwachung aktiv /n'1 = IRUE deaktiv; 0";
CM_ SG_ 1425 ZK4_HR_Tuer_offen "Tuer HR offen, Drehfallen-Kontakt /n1 = Tuer geoef";
CM_ SG_ 1425 ZK4_HL_Tuer_offen "Tuer HL offen, Drehfallen-Kontakt /n1 = Tuer geoef";
CM_ SG_ 1425 ZK4_HDOeffnung "Oeffnungsmodus Heckdeckel /n0 = Heckdeckel nicht i";
CM_ SG_ 1425 ZK4_HD_Vorraste "Heckdeckel_Vorraste aktiv (Tuer geoeffnet) /n1 = V";
CM_ SG_ 1425 ZK4_HD_Hauptraste "Heckdeckel_Hauptraste aktiv (Tuer geoeffnet) /n1 =";
CM_ SG_ 1425 ZK4_HD_Auf_Taster "Oeffnungstaster Heck betaetigt /nAutorisierung zum";
CM_ SG_ 1425 ZK4_Handbremse_aktiv "Handbremse festgestellt";
CM_ SG_ 1425 ZK4_gesafet_ext "Fahrzeug gesafet per Funk/Schl. (Soll) /n1 = Fahrz";
CM_ SG_ 1425 ZK4_FH_Komfortoeffnen "Komfortoeffnen fuer Fensterheber /n1 = Oeffnen all";
CM_ SG_ 1425 ZK4_FH_Freigabe "Freigabe der Funktion Fensterheber /n1 = Funktions";
CM_ SG_ 1425 ZK4_Einzeltuerentrieg "Einzeltuerentriegelung /n1 = Fahrzeug an Einzeltue";
CM_ SG_ 1425 ZK4_DWA_Akku_leer "DWA-Akku leer (s. BSG_Kombi) /n1 = DWA-Akku leer b";
CM_ SG_ 1425 ZK4_Autolock "Autolock der ZV /n1 = Autolock der ZV ist konfigur";
CM_ SG_ 1425 ZK4_Auto_Unlock "Auto Unlock der ZV /n1 = Auto Unlock der ZV ist ko";
CM_ SG_ 1425 ZK4_AD_Komfortoeffnen "Komfortoeffnen fuer Aufstelldach /n1 = Oeffnen des";
CM_ SG_ 1425 ZK4_Absenk_Spiegel "Absenken der Aussenspiegel bei Rueckwaertsfahrt /n";
CM_ BO_ 917 "
Byte 1:Blinkfunktionen";
CM_ SG_ 917 ZK3_Blk_ZV_zu "Modesignal: Blinkerquittierung ZV zu /nZusatzinfo,";
CM_ SG_ 917 ZK3_Blk_ZV_auf "Modesignal: Blinkerquittierung ZV auf /nZusatzinfo";
CM_ SG_ 917 ZK3_Blk_Panik "Modesignal: Panik-Blinken /nZusatzinfo, statisch z";
CM_ SG_ 917 ZK3_Blk_learn "Modesignal: Schluessel lernen /nZusatzinfo, statis";
CM_ SG_ 917 ZK3_Blk_DWA_ein "Modesignal: Blinkerquittierung DWA ein /nZusatzinf";
CM_ SG_ 917 ZK3_Blk_DWA_Alarm "Modesignal: Alarmblinken DWA /nZusatzinfo, statisc";
CM_ SG_ 917 ZK3_Blk_Crash "Modesignal: Crash-Blinken /nZusatzinfo, statisch z";
CM_ SG_ 917 ZK3_Blinker_ein "Blinklampe ein /n'0 = Blinkerlampe aus; 1 = Blinke";
CM_ BO_ 913 "
Byte 1:Komfortfunktion Fensterheber
Byte 2:SchliessStellen-Information
Byte 3:Komfortfunktionen Erweitert";
CM_ SG_ 913 ZK2_ZV_zu_Heck "ZV_zu von SchliessStelle Heck /n'Befehl' fuer die";
CM_ SG_ 913 ZK2_ZV_zu_Funk "ZV_zu von SchliessStelle Funk /n'Befehl' fuer die";
CM_ SG_ 913 ZK2_ZV_zu_FT "ZV_zu von SchliessStelle FT /n'Befehl' fuer die FH";
CM_ SG_ 913 ZK2_ZV_zu_BT "ZV_zu von SchliessStelle BT /n'Befehl' fuer die FH";
CM_ SG_ 913 ZK2_ZV_auf_Heck "ZV_auf von SchliessStelle Heck /n'Befehl' fuer die";
CM_ SG_ 913 ZK2_ZV_auf_Funk "ZV_auf von SchliessStelle Funk /n'Befehl' fuer die";
CM_ SG_ 913 ZK2_ZV_auf_FT "ZV_auf von SchliessStelle FT /n'Befehl' fuer die F";
CM_ SG_ 913 ZK2_ZV_auf_BT "ZV_auf von SchliessStelle BT /n'Befehl' fuer die F";
CM_ SG_ 913 ZK2_SAD_Zu "SAD schliessen /nFreigabeinformation der Komfortfu";
CM_ SG_ 913 ZK2_SAD_Hoch "SAD aufstellen /nFreigabeinformation der Komfortfu";
CM_ SG_ 913 ZK2_SAD_Auf "SAD oeffnen /nFreigabeinformation der Komfortfunkt";
CM_ SG_ 913 ZK2_FH_Zu_Z_man "Zentrales Schliessen Fensterheber manuell /nCabrio";
CM_ SG_ 913 ZK2_FH_Zu_Z_auto "Zentrales Schliessen Fensterheber automatisch /nCa";
CM_ SG_ 913 ZK2_FH_HR_tief "Fenster hinten rechts tief /nFreigabeinformation f";
CM_ SG_ 913 ZK2_FH_HR_hoch "Fenster hinten rechts hoch /nFreigabeinformation f";
CM_ SG_ 913 ZK2_FH_HL_tief "Fenster hinten links tief /nFreigabeinformation fu";
CM_ SG_ 913 ZK2_FH_HL_hoch "Fenster hinten links hoch /nFreigabeinformation fu";
CM_ SG_ 913 ZK2_FH_FT_tief "Fenster Fahrer tief /nFreigabeinformation fuer die";
CM_ SG_ 913 ZK2_FH_FT_hoch "Fenster Fahrer hoch /nFreigabeinformation fuer die";
CM_ SG_ 913 ZK2_FH_BT_tief "Fenster Beifahrer tief /nFreigabeinformation fuer";
CM_ SG_ 913 ZK2_FH_BT_hoch "Fenster Beifahrer hoch /nFreigabeinformation fuer";
CM_ SG_ 913 ZK2_FH_Auf_Z_man "Zentrales Oeffnen Fensterheber manuell /nCabrio li";
CM_ SG_ 913 ZK2_FH_Auf_Z_auto "Zentrales Oeffnen Fensterheber automatisch /nCabri";
CM_ BO_ 657 "
Byte 1:Funkschluessel-Zusatzinformation
Byte 2:Zentralverriegelungs-Befehle
Byte 3:Zusatzfunktionen ZV";
CM_ SG_ 657 ZK1_Zent_safen "Zentral safen";
CM_ SG_ 657 ZK1_Zent_entsafen "Zentral entsafen";
CM_ SG_ 657 ZK1_Taste_Zu "Taste ZV_zu betaetigt";
CM_ SG_ 657 ZK1_Taste_Panik "Panik-Taste betaetigt";
CM_ SG_ 657 ZK1_Taste_HDF "Taste HD-Fernentriegelung betaetigt";
CM_ SG_ 657 ZK1_Taste_Auf "Taste ZV_auf betaetigt /n'1 = Funkschluessel Taste";
CM_ SG_ 657 ZK1_LED_Uebernahme "Uebernahme der Steuerung /nAudi W10: Uebernahme LE";
CM_ SG_ 657 ZK1_LED_Steuerung "Ansteuerung der LED's /nAnst. der LED in den Tuere";
CM_ SG_ 657 ZK1_HR_verriegeln "Tuer hinten rechts verriegeln";
CM_ SG_ 657 ZK1_HR_Tuer_offen "Tuer HR offen, schneller Drehfallen-Kontakt /n1 =";
CM_ SG_ 657 ZK1_HR_entriegeln "Tuer hinten rechts entriegeln";
CM_ SG_ 657 ZK1_HL_verriegeln "Tuer hinten links verriegeln";
CM_ SG_ 657 ZK1_HL_Tuer_offen "Tuer HL offen, schneller Drehfallen-Kontakt /n1 =";
CM_ SG_ 657 ZK1_HL_entriegeln "Tuer hinten links entriegeln";
CM_ SG_ 657 ZK1_HD_verriegeln "Heckdeckel verriegeln";
CM_ SG_ 657 ZK1_HD_schliessen "Heckdeckel schliessen";
CM_ SG_ 657 ZK1_HD_oeffnen "Heckdeckel oeffnen /n1 = Heckdeckel oeffnen";
CM_ SG_ 657 ZK1_HD_entriegeln "Heckdeckel entriegeln";
CM_ SG_ 657 ZK1_Funkschl_Nr "Nummer des Funkschluessels /n(Bit 2, 1, 0 ) 000 =";
CM_ SG_ 657 ZK1_FT_verriegeln "Fahrertuer verriegeln";
CM_ SG_ 657 ZK1_FT_entriegeln "Fahrertuer entriegeln";
CM_ SG_ 657 ZK1_BT_verriegeln "Beifahrertuer verriegeln";
CM_ SG_ 657 ZK1_BT_entriegeln "Beifahrertuer entriegeln";
CM_ SG_ 657 ZK1_433_MHz "433 - MHz-System /n'1 = 433 MHZ; 0=315 MHz'";
CM_ BO_ 707 "
Byte 1:Zuendanlassschloss";
CM_ SG_ 707 ZS1_ZAS_Kl_X "Klemme X (Startvorgang) /n'0=keine Spannung; 1 =Sp";
CM_ SG_ 707 ZS1_ZAS_Kl_S "S-Kontakt (Schluessel steckt) /n1 = Schluessel ste";
CM_ SG_ 707 ZS1_ZAS_KL_P "Klemme P (Parklichtstellung) /n1 = Klemme P ein (P";
CM_ SG_ 707 ZS1_ZAS_Kl_50 "Klemme 50 (Starten) /n1 = Klemme 50 ein; 0 = Klemm";
CM_ SG_ 707 ZS1_ZAS_Kl_15 "Klemme 15 (Zuendung ein) /n1 = Klemme 15 ein, 0 =";
CM_ BO_ 1489 "
Byte 1:Frontwischersteuerung
Byte 2:Heckwischersteuerung";
CM_ SG_ 1489 WI1_Heck_Wasch "Ansteuerung Wascher Heck /n1 = Wascherpumpe Heck a";
CM_ SG_ 1489 WI1_Heck_Normal "Ansteuerung Scheibenwischer Heck Normal /n1 = Heck";
CM_ SG_ 1489 WI1_Heck_ein "Scheibenwischer Heck eingeschaltet /n1 = Heckwisch";
CM_ SG_ 1489 WI1_Heck_Blockiert "Blockierung Heckwischer erkannt /n1 = Heckwischer";
CM_ SG_ 1489 WI1_Front_Wasch "Ansteuerung Wascher Front /n1 = Wascherpumpe Front";
CM_ SG_ 1489 WI1_Front_Schnell "Ansteuerung Frontwischer Schnell /n'1 = Frontwisch";
CM_ SG_ 1489 WI1_Front_Parklage "Parklage Frontwischer /n1= Frontwischer in Parklag";
CM_ SG_ 1489 WI1_Front_Normal "Ansteuerung Frontwischer Normal /n'1 = Frontwische";
CM_ SG_ 1489 WI1_Front_ein "Frontwischer eingeschaltet /n1 = Frontwischer akti";
CM_ BO_ 1361 "
Byte 1:Schluesselinfo";
CM_ SG_ 1361 WF1_Schluessel "Schluesselinformation (s. Kombi_3) /n0 = ungueltig";
CM_ BO_ 1497 "
Byte 1:Befehle Fensterheber
Byte 2:Zusatzfunktionen Verdeck
Byte 3:Status Verdeck
Byte 4:Meldungen Verdeck
Byte 5:Texte";
CM_ SG_ 1497 VS1_Verdeck_Anf "Anforderung Verdeck";
CM_ SG_ 1497 VS1_VD_Zwischenposition "Verdeck in Zwischenposition /n1 = Verdeck in Zwisc";
CM_ SG_ 1497 VS1_VD_zu_ver "Verdeck geschlossen und verriegelt /n1 = Zustand d";
CM_ SG_ 1497 VS1_VD_offen_ver "Verdeck offen und verriegelt /n1 = Zustand des Ver";
CM_ SG_ 1497 VS1_VD_Fehler "Verdeck Fehlerzustand /n1 = Fehlerzustand Verdeck";
CM_ SG_ 1497 VS1_VD_entriegelt "Verdeck entriegelt /n1 = Zustand des Verdeck entri";
CM_ SG_ 1497 VS1_VD_Bew_zu "Verdeck in Bewegung zu /n1 = Verdeck in Bewegung z";
CM_ SG_ 1497 VS1_VD_Bew_auf "Verdeck in Bewegung auf /n1 = Verdeck in Bewegung";
CM_ SG_ 1497 VS1_Texte "Texte in der Kombianzeige /nAnzeige von Texten im";
CM_ SG_ 1497 VS1_Lampe_Blk "Ansteuerung der Fehlerlampe /nAnsteuerung Lampe im";
CM_ SG_ 1497 VS1_KD_Fehler "Kundendienstfehler /n1 = mindestens 1 Kundendienst";
CM_ SG_ 1497 VS1_HHS_enable "HHS Betrieb erlaubt (Heckscheibenheizung) /n1 = He";
CM_ SG_ 1497 VS1_Hardtop "Hardtop montiert /n1 = Hardtop ist montiert";
CM_ SG_ 1497 VS1_Freigabe_FH "Freigabe Fensterheber fuer Komfortfunktionen /nFre";
CM_ SG_ 1497 VS1_FH_HR_tief "Fenster hinten rechts tief";
CM_ SG_ 1497 VS1_FH_HR_hoch "Fenster hinten rechts hoch";
CM_ SG_ 1497 VS1_FH_HL_tief "Fenster hinten links tief";
CM_ SG_ 1497 VS1_FH_HL_hoch "Fenster hinten links hoch";
CM_ SG_ 1497 VS1_FH_FT_tief "Fenster Fahrer tief";
CM_ SG_ 1497 VS1_FH_FT_hoch "Fenster Fahrer hoch /nAnsteuerung Fensterheber vom";
CM_ SG_ 1497 VS1_FH_BT_tief "Fenster Beifahrer tief";
CM_ SG_ 1497 VS1_FH_BT_hoch "Fenster Beifahrer hoch";
CM_ SG_ 1497 VS1_Buzzer "Buzzeransteuerung /nAnsteuerung Buzzer im Kombi";
CM_ BO_ 1213 "
Byte 3:Fensterstellung
Byte 4:Status_Fenster";
CM_ SG_ 1213 HR1_UEKB_aktiviert "UEKB-Fall erkannt";
CM_ SG_ 1213 HR1_KD_Fehler "Kundendienstfehler /n1 = mindestens 1 Kundendienst";
CM_ SG_ 1213 HR1_FH_Thermo "Thermoschutz Fensterheber aktiv";
CM_ SG_ 1213 HR1_FH_Oeffnung "Fensteroeffnung /n0% = Fenster geschlossen oder ni";
CM_ SG_ 1213 HR1_FH_normiert "FH normiert";
CM_ SG_ 1213 HR1_FH_Fang "Fenster im Fangbereich";
CM_ SG_ 1213 HR1_FH_Block "Fenster im Block";
CM_ SG_ 1213 HR1_FH_Bew_tief "Fenster in Bewegung tief";
CM_ SG_ 1213 HR1_FH_Bew_hoch "Fenster in Bewegung hoch";
CM_ BO_ 1209 "
Byte 3:Fensterstellung
Byte 4:Status_Fenster";
CM_ SG_ 1209 HL1_UEKB_aktiviert "UEKB-Fall erkannt";
CM_ SG_ 1209 HL1_KD_Fehler "Kundendienstfehler /n1 = mindestens 1 Kundendienst";
CM_ SG_ 1209 HL1_FH_Thermo "Thermoschutz aktiv";
CM_ SG_ 1209 HL1_FH_Oeffnung "Fensteroeffnung /n0% = Fenster geschlossen oder ni";
CM_ SG_ 1209 HL1_FH_normiert "FH normiert";
CM_ SG_ 1209 HL1_FH_Fang "Fenster im Fangbereich";
CM_ SG_ 1209 HL1_FH_Block "Fenster im Block";
CM_ SG_ 1209 HL1_FH_Bew_tief "Fenster in Bewegung tief";
CM_ SG_ 1209 HL1_FH_Bew_hoch "Fenster in Bewegung hoch";
CM_ BO_ 899 "
Byte 2:Status_Oeffnungshilfe
Byte 3:Zusatzfunktionen";
CM_ SG_ 899 FT3_Verriegeln "Verriegelungstaster betaetigt /n1 = Verriegelungst";
CM_ SG_ 899 FT3_TIG_FT_Freigabe "Tuerinnengriff-Freigabe Fahrertuer /n1 = Freigabe";
CM_ SG_ 899 FT3_TIG_BT_Freigabe "Tuerinnengriff-Freigabe Beifahrertuer /n1 = Freiga";
CM_ SG_ 899 FT3_TIG "Tuerinnengriff betaetigt";
CM_ SG_ 899 FT3_TAG "Tueraussengriff betaetigt";
CM_ BO_ 897 "
Byte 1:Status Zentralverriegelung
Byte 2:Status Fensterheberschalter
Byte 3:Fensterstellung
Byte 4:Status_Fenster
Byte 5:Status_Zusatzfunktion";
CM_ SG_ 897 FT1_verriegelt "Tuerschloss verriegelt /n1 = Tuer verriegelt, 0 =";
CM_ SG_ 897 FT1_Unlock_Taster "Innentaster fuer ZV_auf aktiv (bewertete Info) /n1";
CM_ SG_ 897 FT1_UEKB_aktiviert "UEKB-Fall erkannt";
CM_ SG_ 897 FT1_Tuer_geoeffnet "Tuer offen, Drehfallen-Kontakt /n1 = Tuer geoeffne";
CM_ SG_ 897 FT1_Tankklappe_oeffnen "Tankklappe oeffnen /n1 = Taste Tankklappe oeffnen";
CM_ SG_ 897 FT1_SP_Heizung_ein "Spiegelheizung ist aktiv /nRueckmeldung";
CM_ SG_ 897 FT1_SP_ausgerastet "Spiegel ist ausgerastet";
CM_ SG_ 897 FT1_SP_AS_verbaut "Spiegelausrastschalter verbaut";
CM_ SG_ 897 FT1_Schl_zu "Schluesselschalter fuer Schliessen aktiv";
CM_ SG_ 897 FT1_Schl_auf "Schluesselschalter fuer Oeffnen aktiv";
CM_ SG_ 897 FT1_Neig_Taster "Neigungssensor Ein/Aus Taster betaetigt /n'1 = Tas";
CM_ SG_ 897 FT1_Lock_Taster "Innentaster fuer ZV_zu aktiv (bewertete Info) /n1";
CM_ SG_ 897 FT1_KD_Fehler "Kundendienstfehler /n1 = mindestens 1 Kundendienst";
CM_ SG_ 897 FT1_IRUE_Taste "Innenraumueberw. Ein/Aus Taster beaetigt /n'1 = Ta";
CM_ SG_ 897 FT1_HD_oeffnen "Heckdeckel oeffnen /n1 = Taste Heckdeckel oeffnen";
CM_ SG_ 897 FT1_gesafet "Tuerschloss gesafet";
CM_ SG_ 897 FT1_FH_Thermo "Thermoschutz Fensterheber aktiv";
CM_ SG_ 897 FT1_FH_Oeffnung "Fensteroeffnung /n0% = Fenster geschlossen oder ni";
CM_ SG_ 897 FT1_FH_normiert "FH normiert";
CM_ SG_ 897 FT1_FH_HR_Freigabe "FH-Freigabe hinten rechts /n1 = Freigabe FH, z.B.";
CM_ SG_ 897 FT1_FH_HL_Freigabe "FH-Freigabe hinten links /n1 = Freigabe FH, z.B. K";
CM_ SG_ 897 FT1_FH_FT_Freigabe "FH-Freigabe Fahrertuer /n1 = Freigabe FH, z.B. Kin";
CM_ SG_ 897 FT1_FH_Fang "Fenster im Fangbereich";
CM_ SG_ 897 FT1_FH_BT_Freigabe "FH-Freigabe Beifahrertuer /n1 = Freigabe FH, z.B.";
CM_ SG_ 897 FT1_FH_Block "Fenster im Block";
CM_ SG_ 897 FT1_FH_Bew_tief "Fenster in Bewegung tief";
CM_ SG_ 897 FT1_FH_Bew_hoch "Fenster in Bewegung hoch";
CM_ BO_ 385 "
Byte 1:Fensterheberschalter Befehle
Byte 2:Fensterheberschalter Befehle";
CM_ SG_ 385 FT0_FH_HR_ManTief "Fenster hinten rechts manuell tief (bewertete Info";
CM_ SG_ 385 FT0_FH_HR_ManHoch "Fenster hinten rechts manuell hoch (bewertete Info";
CM_ SG_ 385 FT0_FH_HR_AutoTief "Fenster hinten rechts auto tief (bewertete Info) /";
CM_ SG_ 385 FT0_FH_HR_AutoHoch "Fenster hinten rechts auto hoch (bewertete Info) /";
CM_ SG_ 385 FT0_FH_HL_ManTief "Fenster hinten links manuell tief (bewertete Info)";
CM_ SG_ 385 FT0_FH_HL_ManHoch "Fenster hinten links manuell hoch (bewertete Info)";
CM_ SG_ 385 FT0_FH_HL_AutoTief "Fenster hinten links auto tief (bewertete Info) /n";
CM_ SG_ 385 FT0_FH_HL_AutoHoch "Fenster hinten links auto hoch (bewertete Info) /n";
CM_ SG_ 385 FT0_FH_FT_ManTief "Fenster Fahrer manuell tief (bewertete Info) /n1 =";
CM_ SG_ 385 FT0_FH_FT_ManHoch "Fenster Fahrer manuell hoch (bewertete Info) /n1 =";
CM_ SG_ 385 FT0_FH_FT_AutoTief "Fenster Fahrer auto tief (bewertete Info) /n1 = Sc";
CM_ SG_ 385 FT0_FH_FT_AutoHoch "Fenster Fahrer auto hoch (bewertete Info) /n1 = Sc";
CM_ SG_ 385 FT0_FH_BT_ManTief "Fenster Beifahrer manuell tief (bewertete Info)";
CM_ SG_ 385 FT0_FH_BT_ManHoch "Fenster Beifahrer manuell hoch (bewertete Info)";
CM_ SG_ 385 FT0_FH_BT_AutoTief "Fenster Beifahrer auto tief (bewertete Info)";
CM_ SG_ 385 FT0_FH_BT_AutoHoch "Fenster Beifahrer auto hoch (bewertete Info)";
CM_ BO_ 949 "
Byte 1:Status Zentralverriegelung
Byte 3:Fensterstellung
Byte 4:Status_Fenster
Byte 5:Status_Zusatzfunktion";
CM_ SG_ 949 BT1_verriegelt "Tuerschloss verriegelt";
CM_ SG_ 949 BT1_Unlock_Taster "Innentaster fuer ZV_auf aktiv /n1 = Unlock-Taster";
CM_ SG_ 949 BT1_UEKB_aktiviert "UEKB-Fall erkannt";
CM_ SG_ 949 BT1_Tuer_geoeffnet "Tuer offen, Drehfallen-Kontakt";
CM_ SG_ 949 BT1_SP_Heizung_ein "Spiegelheizung ist aktiv /nRueckmeldung";
CM_ SG_ 949 BT1_SP_ausgerastet "Spiegel ist ausgerastet";
CM_ SG_ 949 BT1_SP_AS_verbaut "Spiegelausrastschalter verbaut";
CM_ SG_ 949 BT1_Schl_zu "Schluesselschalter fuer Schliessen aktiv";
CM_ SG_ 949 BT1_Schl_auf "Schluesselschalter fuer Oeffnen aktiv";
CM_ SG_ 949 BT1_Lock_Taster "Innentaster fuer ZV_zu aktiv /n1 = Lock-Taster (Be";
CM_ SG_ 949 BT1_KD_Fehler "Kundendienstfehler /n1 = mindestens 1 Kundendienst";
CM_ SG_ 949 BT1_gesafet "Tuerschloss gesafet";
CM_ SG_ 949 BT1_FH_Thermo "Thermoschutz Fensterheber aktiv";
CM_ SG_ 949 BT1_FH_Oeffnung "Fensteroeffnung /n0% = Fenster geschlossen oder ni";
CM_ SG_ 949 BT1_FH_normiert "FH normiert";
CM_ SG_ 949 BT1_FH_Fang "Fenster im Fangbereich";
CM_ SG_ 949 BT1_FH_Block "Fenster im Block";
CM_ SG_ 949 BT1_FH_Bew_tief "Fenster in Bewegung tief";
CM_ SG_ 949 BT1_FH_Bew_hoch "Fenster in Bewegung hoch";
CM_ BO_ 562 "
Byte 1:TP_Wischermodul_Eroeffnung";
CM_ SG_ 562 Wischermodul_TP_Er "TP 2.0 Eroeffnungskanal /nWischermodul";
CM_ BO_ 560 "
Byte 1:TP_VSG_Eroeffnung";
CM_ SG_ 560 VSG_TP_Er "TP 2.0 Eroeffnungskanal /nVerdecksteuergeraet / Sc";
CM_ BO_ 549 "
Byte 1:TP_TSG_HR_Eroeffnung";
CM_ SG_ 549 HR_TP_Er "TP 2.0 Eroeffnungskanal";
CM_ BO_ 548 "
Byte 1:TP_TSG_HL_Eroeffnung";
CM_ SG_ 548 HL_TP_Er "TP 2.0 Eroeffnungskanal";
CM_ BO_ 546 "
Byte 1:TP_TSG_FT_Eroeffnung";
CM_ SG_ 546 FT_TP_Er "TP 2.0 Eroeffnungskanal";
CM_ BO_ 547 "
Byte 1:TP_TSG_BT_Eroeffnung";
CM_ SG_ 547 BT_TP_Er "TP 2.0 Eroeffnungskanal";
CM_ BO_ 512 "
Byte 1:TP_Tester_Eroeffnung";
CM_ SG_ 512 Tester_TP_Er "TP 2.0 Eroeffnungskanal /n'Transportkanaleroeffnun";
CM_ BO_ 554 "
Byte 1:TP_SMLS_Eroeffnung";
CM_ SG_ 554 SMLS_TP_Er "TP 2.0 Eroeffnungskanal /nLenksaeulenmodul SMSL =";
CM_ BO_ 559 "
Byte 1:TP_SH_Eroeffnung";
CM_ SG_ 559 SH_TP_Er "TP 2.0 Eroeffnungskanal /nStandheizung";
CM_ BO_ 553 "
Byte 1:TP_RDK_Eroeffnung";
CM_ SG_ 553 RDK_TP_Er "TP 2.0 Eroeffnungskanal /nReifendruckkontrolle";
CM_ BO_ 558 "
Byte 1:TP_PTC_Eroeffnung";
CM_ SG_ 558 PTC_TP_Er "TP 2.0 Eroeffnungskanal /nPTC-Heizung";
CM_ BO_ 570 "
Byte 1:TP_SFzg_Eroeffnung";
CM_ SG_ 570 MFG_TP_Er "TP 2.0 Eroeffnungskanal /nSonderfahrzeugsteuergera";
CM_ BO_ 565 "
Byte 1:TP_Mem_BF_Eroeffnung";
CM_ SG_ 565 Mem_BF_TP_Er "TP 2.0 Eroeffnungskanal /nMemorySteuergeraet Beifa";
CM_ BO_ 550 "
Byte 1:TP_MEM_Eroeffnung";
CM_ SG_ 550 MEM_TP_Er "TP 2.0 Eroeffnungskanal /nSitzmemory Fahrer";
CM_ BO_ 545 "
Byte 1:TP_KSG_Eroeffnung";
CM_ SG_ 545 KSG_TP_Er "TP 2.0 Eroeffnungskanal /nKomfortsteuergeraet, Zen";
CM_ BO_ 543 "
Byte 1:TP_Gateway_Eroeffnung";
CM_ SG_ 543 Gateway_TP_Er "TP 2.0 Eroeffnungskanal /nGateway";
CM_ BO_ 556 "
Byte 1:TP_Clima_Eroeffnung";
CM_ SG_ 556 CL_TP_Er "TP 2.0 Eroeffnungskanal /nClima";
CM_ BO_ 544 "
Byte 1:TP_BSG_Eroeffnung";
CM_ SG_ 544 BSG_TP_Er "TP 2.0 Eroeffnungskanal /nILM, BSG";
CM_ BO_ 557 "
Byte 1:TP_APS_Eroeffnung";
CM_ SG_ 557 APS_TP_Er "TP 2.0 Eroeffnungskanal /nEinparkhilfe (Automatisc";
CM_ BO_ 579 "
Byte 1:TP_AnhaengerSG_Eroeffnung";
CM_ SG_ 579 AAG_TP_Er "TP 2.0 Eroeffnungskanal /nAnhaengeranschlussgeraet";
CM_ BO_ 811 "
Byte 1:Dyn. TP 2.0 Empfangskanal";
CM_ SG_ 811 TPDyn_VSG_2 "TP 2.0 Empfangskanal 2 fuer Verdeck_SG /nVerdeckst";
CM_ BO_ 810 "
Byte 1:Dyn. TP 2.0 Empfangskanal";
CM_ SG_ 810 TPDyn_VSG_1 "TP 2.0 Empfangskanal 1 fuer Verdeck_SG /nVerdeckst";
CM_ BO_ 791 "
Byte 1:Dyn. TP 2.0 Empfangskanal";
CM_ SG_ 791 TPDyn_TSG_HR_2 "TP 2.0 Empfangskanal 2 fuer Tuer_SG_hinten_rechts";
CM_ BO_ 790 "
Byte 1:Dyn. TP 2.0 Empfangskanal";
CM_ SG_ 790 TPDyn_TSG_HR_1 "TP 2.0 Empfangskanal 1 fuer Tuer_SG_hinten_rechts";
CM_ BO_ 789 "
Byte 1:Dyn. TP 2.0 Empfangskanal";
CM_ SG_ 789 TPDyn_TSG_HL_2 "TP 2.0 Empfangskanal 2 fuer Tuer_SG_hinten_links /";
CM_ BO_ 788 "
Byte 1:Dyn. TP 2.0 Empfangskanal";
CM_ SG_ 788 TPDyn_TSG_HL_1 "TP 2.0 Empfangskanal 1 fuer Tuer_SG_hinten_links /";
CM_ BO_ 785 "
Byte 1:Dyn. TP 2.0 Empfangskanal";
CM_ SG_ 785 TPDyn_TSG_F_2 "TP 2.0 Empfangskanal 2 fuer Fahrertuer_SG /nTuerst";
CM_ BO_ 784 "
Byte 1:Dyn. TP 2.0 Empfangskanal";
CM_ SG_ 784 TPDyn_TSG_F_1 "TP 2.0 Empfangskanal 1 fuer Fahrertuer_SG /nTuerst";
CM_ BO_ 787 "
Byte 1:Dyn. TP 2.0 Empfangskanal";
CM_ SG_ 787 TPDyn_TSG_BF_2 "TP 2.0 Empfangskanal 2 fuer Beifahrertuer_SG /nTue";
CM_ BO_ 786 "
Byte 1:Dyn. TP 2.0 Empfangskanal";
CM_ SG_ 786 TPDyn_TSG_BF_1 "TP 2.0 Empfangskanal 1 fuer Beifahrertuer_SG /nTue";
CM_ BO_ 765 "
Byte 1:Dyn. TP 2.0 Empfangskanal";
CM_ SG_ 765 TPDyn_SMLS_2 "TP 2.0 Empfangskanal 2 fuer Lenksaeulenmodul /nSch";
CM_ BO_ 764 "
Byte 1:Dyn. TP 2.0 Empfangskanal";
CM_ SG_ 764 TPDyn_SMLS_1 "TP 2.0 Empfangskanal 1 fuer Lenksaeulenmodul /nSch";
CM_ BO_ 805 "
Byte 1:Dyn. TP 2.0 Empfangskanal";
CM_ SG_ 805 TPDyn_SH_2 "TP 2.0 Empfangskanal 2 fuer Standheizung_SG /nStan";
CM_ BO_ 804 "
Byte 1:Dyn. TP 2.0 Empfangskanal";
CM_ SG_ 804 TPDyn_SH_1 "TP 2.0 Empfangskanal 1 fuer Standheizung_SG /nStan";
CM_ BO_ 803 "
Byte 1:Dyn. TP 2.0 Empfangskanal";
CM_ SG_ 803 TPDyn_RDK_2 "TP 2.0 Empfangskanal 2 fuer Reifendruckkontrolle /";
CM_ BO_ 802 "
Byte 1:Dyn. TP 2.0 Empfangskanal";
CM_ SG_ 802 TPDyn_RDK_1 "TP 2.0 Empfangskanal 1 fuer Reifendruckkontrolle /";
CM_ BO_ 827 "
Byte 1:Dyn. TP 2.0 Empfangskanal";
CM_ SG_ 827 TPDyn_PTC_2 "TP 2.0 Empfangskanal 2 fuer PTC_Heizung_SG /nPTC-H";
CM_ BO_ 826 "
Byte 1:Dyn. TP 2.0 Empfangskanal";
CM_ SG_ 826 TPDyn_PTC_1 "TP 2.0 Empfangskanal 1 fuer PTC_Heizung_SG /nPTC-H";
CM_ BO_ 767 "
Byte 1:Dyn. TP 2.0 Empfangskanal";
CM_ SG_ 767 TPDyn_MFG_2 "TP 2.0 Empfangskanal 2 fuer Multifunktions_SG /nMu";
CM_ BO_ 766 "
Byte 1:Dyn. TP 2.0 Empfangskanal";
CM_ SG_ 766 TPDyn_MFG_1 "TP 2.0 Empfangskanal 1 fuer Multifunktions_SG /nMu";
CM_ BO_ 793 "
Byte 1:Dyn. TP 2.0 Empfangskanal";
CM_ SG_ 793 TPDyn_Mem_F_2 "TP 2.0 Empfangskanal 2 fuer Sitzmemory_Fahrer /nSi";
CM_ BO_ 792 "
Byte 1:Dyn. TP 2.0 Empfangskanal";
CM_ SG_ 792 TPDyn_Mem_F_1 "TP 2.0 Empfangskanal 1 fuer Sitzmemory_Fahrer /nSi";
CM_ BO_ 795 "
Byte 1:Dyn. TP 2.0 Empfangskanal";
CM_ SG_ 795 TPDyn_MEM_BF_2 "TP 2.0 Empfangskanal 2 fuer Sitzmemory_Beifahrer /";
CM_ BO_ 794 "
Byte 1:Dyn. TP 2.0 Empfangskanal";
CM_ SG_ 794 TPDyn_MEM_BF_1 "TP 2.0 Empfangskanal 1 fuer Sitzmemory_Beifahrer /";
CM_ BO_ 809 "
Byte 1:Dyn. TP 2.0 Empfangskanal";
CM_ SG_ 809 TPDyn_KSG_2 "TP 2.0 Empfangskanal 2 fuer Komfort_SG /nKomfortst";
CM_ BO_ 808 "
Byte 1:Dyn. TP 2.0 Empfangskanal";
CM_ SG_ 808 TPDyn_KSG_1 "TP 2.0 Empfangskanal 1 fuer Komfort_SG /nKomfortst";
CM_ BO_ 815 "
Byte 1:Dyn. TP 2.0 Empfangskanal";
CM_ SG_ 815 TPDyn_GW_2 "TP 2.0 Empfangskanal 2 fuer Gateway_SG /nGateway";
CM_ BO_ 814 "
Byte 1:Dyn. TP 2.0 Empfangskanal";
CM_ SG_ 814 TPDyn_GW_1 "TP 2.0 Empfangskanal 1 fuer Gateway_SG /nGateway";
CM_ BO_ 1235 "
Byte 1:Dyn. TP 2.0 Empfangskanal";
CM_ SG_ 1235 TPDyn_Grafik_4 "TP 2.0 Empfangskanal 4 fuer Grafikeinheit /nGrafik";
CM_ BO_ 1234 "
Byte 1:Dyn. TP 2.0 Empfangskanal";
CM_ SG_ 1234 TPDyn_Grafik_3 "TP 2.0 Empfangskanal 3 fuer Grafikeinheit /nGrafik";
CM_ BO_ 1233 "
Byte 1:Dyn. TP 2.0 Empfangskanal";
CM_ SG_ 1233 TPDyn_Grafik_2 "TP 2.0 Empfangskanal 2 fuer Grafikeinheit /nGrafik";
CM_ BO_ 1232 "
Byte 1:Dyn. TP 2.0 Empfangskanal";
CM_ SG_ 1232 TPDyn_Grafik_1 "TP 2.0 Empfangskanal 1 fuer Grafikeinheit /nGrafik";
CM_ BO_ 829 "
Byte 1:Dyn. TP 2.0 Empfangskanal";
CM_ SG_ 829 TPDyn_Clima_2 "TP 2.0 Empfangskanal 2 fuer Clima_SG /nClimaanlage";
CM_ BO_ 828 "
Byte 1:Dyn. TP 2.0 Empfangskanal";
CM_ SG_ 828 TPDyn_Clima_1 "TP 2.0 Empfangskanal 1 fuer Clima_SG /nClimaanlage";
CM_ BO_ 825 "
Byte 1:Dyn. TP 2.0 Empfangskanal";
CM_ SG_ 825 TPDyn_BSG_2 "TP 2.0 Empfangskanal 2 fuer Bordnetz_SG /nBordnetz";
CM_ BO_ 824 "
Byte 1:Dyn. TP 2.0 Empfangskanal";
CM_ SG_ 824 TPDyn_BSG_1 "TP 2.0 Empfangskanal 1 fuer Bordnetz_SG /nBordnetz";
CM_ BO_ 819 "
Byte 1:Dyn. TP 2.0 Empfangskanal";
CM_ SG_ 819 TPDyn_APS_2 "TP 2.0 Empfangskanal 2 fuer Einparkhilfe /nEinpark";
CM_ BO_ 818 "
Byte 1:Dyn. TP 2.0 Empfangskanal";
CM_ SG_ 818 TPDyn_APS_1 "TP 2.0 Empfangskanal 1 fuer Einparkhilfe /nEinpark";
CM_ BO_ 823 "
Byte 1:Dyn. TP 2.0 Empfangskanal";
CM_ SG_ 823 TPDyn_AAG_2 "TP 2.0 Empfangskanal 2 fuer Anhaenger_SG /nAnhaeng";
CM_ BO_ 822 "
Byte 1:Dyn. TP 2.0 Empfangskanal,";
CM_ SG_ 822 TPDyn_AAG_1 "TP 2.0 Empfangskanal 1 fuer Anhaenger_SG /nAnhaeng";
CM_ SG_ 1449 TM2_Warnblink "Warnblinker ein /n0: Warnblinker sind ausgeschalte";
CM_ SG_ 1449 TM2_Unlock "ZV entriegeln /nZV auf/ Entriegeln";
CM_ SG_ 1449 TM2_Signalhorn "Hupe ein /n0 = Hupe aus;1 = Hupe ein; Der Takt mus";
CM_ SG_ 1449 TM2_Lock "ZV verriegeln /nZV zu/ Verriegeln";
CM_ BO_ 1637 "
Byte 1:Statusmeldung
Byte 2:Statusmeldung 2
Byte 3:Statusmeldung 3
Byte 4:Verbindungsinfo
Byte 6:Status Land Registrierung";
CM_ SG_ 1637 TF3_Show_Phone "Kombi soll Tel-Daten anzeigen /n1 = Radioanzeige d";
CM_ SG_ 1637 TF3_Registrierungsstatus "Status der Registrierung /n'Netzregistrierungsstat";
CM_ SG_ 1637 TF3_Provider "Netzwerkprovidercode (MNC) BCD codiert /nMNC Codie";
CM_ SG_ 1637 TF3_Phone_sim_OK "Simkarte eingelegt /n1 = gueltige Simkarte eingele";
CM_ SG_ 1637 TF3_Phone_ring "Eingehender Anruf /n1 = Anrufsignalisierung";
CM_ SG_ 1637 TF3_Phone_reset_timer "Reset ADR-Timer im Kombi /nReset des Anzeigetimers";
CM_ SG_ 1637 TF3_Phone_res "Vorhalt Mute_Msg_code";
CM_ SG_ 1637 TF3_Phone_pin_OK "Pin richtig eingegeben /n1 = PIN richtig eingegebe";
CM_ SG_ 1637 TF3_Phone_on "Telefon eingeschaltet /n1 = Telefon eingeschaltet";
CM_ SG_ 1637 TF3_Phone_mute "Car_Radio_mute /n1 =Car Radio Mute (CRM) / Vorhalt";
CM_ SG_ 1637 TF3_Phone_Level "Lautstaerke Handsfree Line_Out";
CM_ SG_ 1637 TF3_Phone_Error_flag "Fehlereintrag vorhanden /n1 = mindestens ein Kunde";
CM_ SG_ 1637 TF3_Phone_active_call "Ein-/Ausgehender Anruf /n1 = Verbindungsaufbau/Ges";
CM_ SG_ 1637 TF3_Laendercode "Laendercode (MCC) BCD codiert /nMCC Codierung gema";
CM_ SG_ 1637 TF3_Feldstaerke_Fehler "Feldstaekeinfo nicht verfuegbar oder Fehler /n1 =";
CM_ SG_ 1637 TF3_Feldstaerke "Aktuelle Feldstaerke des Netzes /nFeldstaerkeinfor";
CM_ BO_ 1617 "
Byte 1:CAN_Extern
Byte 2:Plattform_Info_1
Byte 3:Plattform_Info_2
Byte 4:Plattform_Info_3
Byte 5:CAN_Vers_Komfort
Byte 6:CAN_Vers_Antrieb";
CM_ SG_ 1617 SY1_Viertuerer "Fahrzeug besitzt vier Tueren /n1 = Viertuerfahrzeu";
CM_ SG_ 1617 SY1_VersLowCAN_Komfort "Version CAN-Komfort, 1. Nachkommastelle /nn = Nach";
CM_ SG_ 1617 SY1_VersLowCAN_Antrieb "Version CAN-Antrieb, 1. Nachkommastelle /nn = Nach";
CM_ SG_ 1617 SY1_VersHighCAN_Komfort "Version CAN-Komfort, Vorkomma /nv = Vorkomma fuer";
CM_ SG_ 1617 SY1_VersHighCAN_Antrieb "Version CAN-Antrieb, Vorkomma /nv = Vorkomma fuer";
CM_ SG_ 1617 SY1_Verbauliste_gueltig "Verbauliste gueltig nach Lernalgorithmus /n1 = Ver";
CM_ SG_ 1617 SY1_Transportmode "Transportmode /n1 = Transportmodus aktiv";
CM_ SG_ 1617 SY1_Sleep_Komfort "CAN-Komfort in Busruhe /n1 = CAN-Komfort ist in Bu";
CM_ SG_ 1617 SY1_Sleep_Infotainment "CAN-Infotainment in Busruhe /n1 = CAN-Infotainment";
CM_ SG_ 1617 SY1_Rechtslenker "Fahrzeug ist Rechtslenker /n1 = Rechtslenkerfahrze";
CM_ SG_ 1617 SY1_Marke "Fahrzeug-Marke /n'0 = VW; 1=AU; 2 = SE; 3 = SK; 4";
CM_ SG_ 1617 SY1_Klasse "Fahrzeug-Klasse /n'0 = A000; 1 = A00; 2 = A0; 3 =";
CM_ SG_ 1617 SY1_KD_Fehler "Kundendienstfehler im SG eingetragen /n1 = mindest";
CM_ SG_ 1617 SY1_Infotainment "CAN- Infotainment-Netzwerk verbaut /n1 = Infotaine";
CM_ SG_ 1617 SY1_Generation "Fahrzeug-Generation /n'x = Generation (1...7); Nac";
CM_ SG_ 1617 SY1_Erweiterung "Fahrzeug-Index /n'0 = kurzer Radstand; 1= langer R";
CM_ SG_ 1617 SY1_Diag_Komfort "CAN-Komfort in Diagnose /n1 = Diagnoseanforderung";
CM_ SG_ 1617 SY1_Diag_Infotainment "CAN -Infotainment in Diagnose /n1 = Diagnoseanford";
CM_ SG_ 1617 SY1_Diag_Antrieb "CAN-Antrieb in Diagnose /n1 = Diagnoseanfoderung e";
CM_ SG_ 1617 SY1_Derivat "Fahrzeug-Derivat /n'0 = Kurzheck; 1 = Stufenheck;";
CM_ SG_ 1617 SY1_CAN_Extern "CAN-Extern zugeschaltet /n1 = CAN_Extern-Schalter";
CM_ BO_ 997 "
Byte 1:Funkfernbedienung
Byte 2:Status_Standheizung
Byte 3:Kraftstoffverbrauch
Byte 5:Heizleistung";
CM_ SG_ 997 SH1_ZusatzHeizung "Verbrennungszuheizer ein /n1 = Verbrennungszuheize";
CM_ SG_ 997 SH1_SH_Modus "Befehl Standheizungsmodus aktivieren";
CM_ SG_ 997 SH1_Prog_Modus "Programmierung /n1 = Standheizungsprogrammierung a";
CM_ SG_ 997 SH1_LED "Kontrolllampe Standheizung ein /n1 = Kontroll-LED";
CM_ SG_ 997 SH1_KD_Fehler "Kundendienstfehler /n1 = mindestens 1 Kundendienst";
CM_ SG_ 997 SH1_K_Verbrauch "Kraftstoffsignal";
CM_ SG_ 997 SH1_K_Fehler "Kraftstoffverbrauch Fehlerstatus /n1 = Kraftstoffv";
CM_ SG_ 997 SH1_Heizleistung "Heizleistung";
CM_ SG_ 997 SH1_Geblaese "Fahrzeuggeblaese ein /n1 = Geblaese ein";
CM_ SG_ 997 SH1_FunkStLftg "'Funkbefehl 'Standlueftung ein' erhalten'";
CM_ SG_ 997 SH1_FunkSH_Ein "'Funkbefehl 'Standheizung ein' erhalten'";
CM_ SG_ 997 SH1_Funk_ein "Funkbefehl 'Standheizung/-Luefung ein' erhalten' /";
CM_ SG_ 997 SH1_Funk_aus "Funkbefehl 'Standheizung/-Lueftung aus' erhalten'";
CM_ SG_ 997 SH1_Fehlerstatus "Fehlerstatus Standheizung /n0 = kein Fehler; 1 = B";
CM_ BO_ 1537 "
Byte 1:Spiegelschalter";
CM_ SG_ 1537 SP2_S_unten "Spiegelschalter in Richtung unten";
CM_ SG_ 1537 SP2_S_rechts "Spiegelschalter in Richtung rechts";
CM_ SG_ 1537 SP2_S_oben "Spiegelschalter in Richtung oben";
CM_ SG_ 1537 SP2_S_links "Spiegelschalter in Richtung links";
CM_ SG_ 1537 SP2_S_Klappen "Spiegelschalter Anklappen";
CM_ SG_ 1537 SP2_S_Heizung "Spiegelschalter / Taster Heizung ein";
CM_ SG_ 1537 SP2_Auswahl_rechts "Spiegelschalter Auswahl rechts";
CM_ SG_ 1537 SP2_Auswahl_links "Spiegelschalter Auswahl links";
CM_ BO_ 1281 "
Byte 1:Spiegelverstellung
Byte 2:Zusatzfunktionen";
CM_ SG_ 1281 SP1_normieren "Anklappung_normieren";
CM_ SG_ 1281 SP1_Hzg_Taster "Heizungstaster / schalter betaetigt /n1 = Heizungs";
CM_ SG_ 1281 SP1_FT_unten "Spiegel Fahrer nach unten -Y /nIdentifier entweder";
CM_ SG_ 1281 SP1_FT_rechts "Spiegel Fahrer nach rechts +X /nFahrertuer integri";
CM_ SG_ 1281 SP1_FT_oben "Spiegel Fahrer nach oben +Y /nJe nach Einbauort de";
CM_ SG_ 1281 SP1_FT_links "Spiegel Fahrer nach links -X /nMittelkonsole) oder";
CM_ SG_ 1281 SP1_BT_unten "Spiegel Beifahrer nach unten -Y";
CM_ SG_ 1281 SP1_BT_rechts "Spiegel Beifahrer nach rechts +X";
CM_ SG_ 1281 SP1_BT_oben "Spiegel Beifahrer nach oben +Y";
CM_ SG_ 1281 SP1_BT_links "Spiegel Beifahrer nach links -X";
CM_ SG_ 1281 SP1_anklappen "Spiegel anklappen(Garage)";
CM_ SG_ 1281 SP1_abklappen "Spiegel abklappen(Fahrer)";
CM_ BO_ 1621 "
Byte 1:Verbau_Antrieb_1
Byte 4:Verbau_Komfort_1
Byte 6:Verbau_Komfort_3
Byte 8:Verbau_Komfort_5";
CM_ SG_ 1621 VBN_VSG_K "Verdecksteuergeraet /nSollverbau";
CM_ SG_ 1621 VBN_TV_Tuner_I "TV_Tuner am CAN-Infotainment /nSollverbau";
CM_ SG_ 1621 VBN_TSG_HR_K "TSG_HR /nSollverbau";
CM_ SG_ 1621 VBN_TSG_HL_K "TSG_HL /nSollverbau";
CM_ SG_ 1621 VBN_TSG_FT_K "TSG_FT /nSollverbau";
CM_ SG_ 1621 VBN_TSG_BT_K "TSG_BT /nSollverbau";
CM_ SG_ 1621 VBN_Telematik_I "Telematik am CAN-Infotainment /nSollverbau";
CM_ SG_ 1621 VBN_Telefon_I "Telefon am CAN-Infotainment /nSollverbau";
CM_ SG_ 1621 VBN_Standhzg_K "Standheizung /nSollverbau";
CM_ SG_ 1621 VBN_Spracheingabe_I "Spracheingabe am CAN-Infotainment /nSollverbau";
CM_ SG_ 1621 VBN_Sonderfahrzeug_SG_K "Sonderfahrzeug-SG";
CM_ SG_ 1621 VBN_Soll_Ist_OK "Sollverbauliste gleich Istverbauliste /n1 = Sollve";
CM_ SG_ 1621 VBN_SMLS_K "Lenksaeulenmodul/Multifunktionslenkrad /nSollverba";
CM_ SG_ 1621 VBN_RDK_K "Reifendruck /nSollverbau";
CM_ SG_ 1621 VBN_Radio_I "Radio am CAN-Infotainment /nSollverbau; Fuer RNS w";
CM_ SG_ 1621 VBN_PTC_Heizung_K "PTC-Heizung /n1 = PTC-Heizung verbaut";
CM_ SG_ 1621 VBN_Navigation_I "Navigation am CAN-Infotainment /nSollverbau; Fuer";
CM_ SG_ 1621 VBN_Motor_A "Motorsteuergeraet /nimmer 1! (Motorsteuergeraet im";
CM_ SG_ 1621 VBN_Memory_K "Memory /nSollverbau";
CM_ SG_ 1621 VBN_Mem_BF_K "Sitzmemory_BF /nSollverbau";
CM_ SG_ 1621 VBN_LSM_A "Lenkwinkel /nSollverbau";
CM_ SG_ 1621 VBN_Lenkhilfe_A "Lenkhilfe";
CM_ SG_ 1621 VBN_KSG_K "ZKE /nSollverbau";
CM_ SG_ 1621 VBN_Kombi_A "Kombiinstrument am CAN-Antrieb /nimmer 1! (Kombi_A";
CM_ SG_ 1621 VBN_Getriebe_A "Getriebesteuergeraet /nSollverbau";
CM_ SG_ 1621 VBN_Gateway_K "Gatewaymodul am CAN-Komfort /nSollverbau";
CM_ SG_ 1621 VBN_dyn_LWR_A "Dynamische Leuchtweitenregulierung";
CM_ SG_ 1621 VBN_DSP_I "DSP am CAN-Infotainment /nSollverbau";
CM_ SG_ 1621 VBN_Clima_K "Climasteuerung am CAN-Komfort /nSollverbau";
CM_ SG_ 1621 VBN_BSG_K "BSG_Komfort bzw. ILM_Komfort /nSollverbau";
CM_ SG_ 1621 VBN_Bremse_A "ABS, ESP /nSollverbau, ABS fuer Schlechtweginforma";
CM_ SG_ 1621 VBN_APS_K "Einparkhilfe /nSollverbau";
CM_ SG_ 1621 VBN_Allrad_A "Allrad /nSollverbau";
CM_ SG_ 1621 VBN_Airbag_A "Airbag /nSollverbau";
CM_ SG_ 1621 VBN_AAG_K "Anhaengermodul /nSollverbau";
CM_ BO_ 1451 "
Byte 1:Statusbotschaft
Byte 2:NF_Level_Info";
CM_ SG_ 1451 SB3_Show_SBS "Vorhalt fuer Displayanzeige /nDisplay-Request durc";
CM_ SG_ 1451 SB3_SBS_on "Sprachbedienung Betriebsbereit /nBetriebsbereit be";
CM_ SG_ 1451 SB3_SBS_mute "NF-Stummschaltung /nBei Spracheingabe =1 wenn NF g";
CM_ SG_ 1451 SB3_SBS_Level "Lautstaerke SBS Line_Out /nPegel der Lautstaerke a";
CM_ SG_ 1451 SB3_SBS_Error_flag "Fehlereintrag vorhanden /nFehlereintrag liegt vor";
CM_ SG_ 1451 SB3_SBS_com_send "Befehl abgeschickt /nFlag fuer abgesendeten Befehl";
CM_ SG_ 1451 SB3_SBS_active "SBS Bedienung aktiv /nbei Aktivierung durch PTT=1";
CM_ BO_ 1603 "
Byte 1:Reserverad
Byte 2:Reifentemperatur RR";
CM_ SG_ 1603 RK4_Temp_RR "Reifentemperatur Reserverad /nAbschaltung bei 120";
CM_ SG_ 1603 RK4_Reifenstecher_RR "Reifenstecher Reserverad";
CM_ SG_ 1603 RK4_Druck_RR "Reifendruck Reserverad /nGemessener Reifendruck al";
CM_ SG_ 1603 RK4_Diebstahl_RR "Reifendiebstahl Reserverad /n1 = Diebstahl erkannt";
CM_ BO_ 1601 "
Byte 1:Reifen VL
Byte 2:Reifentemperatur VL
Byte 3:Reifen VR
Byte 4:Reifentemperatur VR
Byte 5:Reifen HL
Byte 6:Reifentemperatur HL
Byte 7:Reifen HR
Byte 8:Reifentemperatur HR";
CM_ SG_ 1601 RK3_Temp_VR "Reifentemperatur vorne rechts /nAbschaltung bei 12";
CM_ SG_ 1601 RK3_Temp_VL "Reifentemperatur vorne links /nAbschaltung bei 120";
CM_ SG_ 1601 RK3_Temp_HR "Reifentemperatur hinten rechts /nAbschaltung bei 1";
CM_ SG_ 1601 RK3_Temp_HL "Reifentemperatur hinten links /nAbschaltung bei 12";
CM_ SG_ 1601 RK3_Reifenstecher_VR "Reifenstecher vorne rechts";
CM_ SG_ 1601 RK3_Reifenstecher_VL "Reifenstecher vorne links";
CM_ SG_ 1601 RK3_Reifenstecher_HR "Reifenstecher hinten rechts";
CM_ SG_ 1601 RK3_Reifenstecher_HL "Reifenstecher hinten links";
CM_ SG_ 1601 RK3_Druck_VR "Reifendruck vorne rechts /nGemessener Reifendruck";
CM_ SG_ 1601 RK3_Druck_VL "Reifendruck vorne links /nGemessener Reifendruck a";
CM_ SG_ 1601 RK3_Druck_HR "Reifendruck hinten rechts /nGemessener Reifendruck";
CM_ SG_ 1601 RK3_Druck_HL "Reifendruck hinten links /nGemessener Reifendruck";
CM_ SG_ 1601 RK3_Diebstahl_VR "Reifendiebstahl vorne rechts erkannt /n1 = Diebsta";
CM_ SG_ 1601 RK3_Diebstahl_VL "Reifendiebstahl vorne links erkannt /n1 = Diebstah";
CM_ SG_ 1601 RK3_Diebstahl_HR "Reifendiebstahl hinten rechts erkannt /n1 = Diebst";
CM_ SG_ 1601 RK3_Diebstahl_HL "Reifendiebstahl hinten links erkannt /n1 = Diebsta";
CM_ BO_ 833 "
Byte 1:Warnstatus
Byte 2:Systemstoerung
Byte 3:Zusatztexte";
CM_ SG_ 833 RK2_Warnung_2 "Warnstufe 2 /n1 = Warnstufe aktiv";
CM_ SG_ 833 RK2_Warnung_1 "Warnstufe 1 /n1 = Warnstufe aktiv";
CM_ SG_ 833 RK2_Text_5 "Textausgabe 'Defektes Rad an Board' /n1 = Textausg";
CM_ SG_ 833 RK2_Text_3 "Text 'Zu grosser Differenzdruck VA zu HA erkannt'";
CM_ SG_ 833 RK2_Text_2 "Textausgabe 'RDKS Aktiv' /n'1 = Textausgabe 'RDKS";
CM_ SG_ 833 RK2_Text_1 "Textausgabe 'Inaktiv waehrend Lernphase' /n'Alle T";
CM_ SG_ 833 RK2_Sytem_Aus "System aus /n1 = RDK ist ausgeschaltet ; Schreibfe";
CM_ SG_ 833 RK2_Systemfehler "Lampe Systemfehler /n'1 = Stoerung; gelbe Warnlamp";
CM_ SG_ 833 RK2_Reifen_VR "Warnung fuer Reifen vorne rechts";
CM_ SG_ 833 RK2_Reifen_VL "Warnung fuer Reifen vorne links /n1 aus n-Codierun";
CM_ SG_ 833 RK2_Reifen_RR "Warnung fuer Reserverad";
CM_ SG_ 833 RK2_Reifen_HR "Warnung fuer Reifen hinten rechts";
CM_ SG_ 833 RK2_Reifen_HL "Warnung fuer Reifen hinten links";
CM_ SG_ 833 RK2_KD_Fehler "Kundendienstfehler /n1 = mindestens ein Fehler im";
CM_ SG_ 833 RK2_Kalibrier_abgew "Hinweis Abweisung Kalibrierung enthalten /n1 = Kal";
CM_ SG_ 833 RK2_Gelaendedruck "Gelaendedruck in den Reifen vorhanden /n1 = Druck";
CM_ SG_ 833 RK2_Funkstoerung "Funkstoerung erkannt /n1 = Funkstoerung erkannt";
CM_ SG_ 833 RK2_Druckdiff_Vorn "zu grosser Differenzdruck Vorne erkannt /n1 = zu g";
CM_ SG_ 833 RK2_Druckdiff_Hinten "zu grosser Differenzdruck Hinten erkannt /n1 = zu";
CM_ SG_ 833 RK2_Befuellung_RR_low "Befuelldruck Reserverad zu gering /n1 = Befuelldru";
CM_ BO_ 1091 "
Byte 1:Warnungen
Byte 2:Status
Byte 3:Multiplex 1
Byte 4:Multiplex 2
Byte 5:Multiplex 3
Byte 6:Multiplex 4";
CM_ SG_ 1091 RDK_xx_Status_Sensor "Status des einzelnen Sensors in Abhaengigkeit von";
CM_ SG_ 1091 RDK_xx_Soll_Druck "Solldruck des Reifens in Abhaengigkeit von Byte 3,";
CM_ SG_ 1091 RDK_xx_Ist_Temp "Isttemperatur des Reifens in Abhaengigkeit von Byt";
CM_ SG_ 1091 RDK_xx_Ist_Druck "Istdruck des Reifens in Abhaengigkeit von Byte 3,";
CM_ SG_ 1091 RDK_xx_Color "Farbdarstellung der Reifen im Kombi in Abhaengigke";
CM_ SG_ 1091 RDK_Warnungen "Warnmeldungen fuers Kombi /n0x00 = keine Warnung;";
CM_ SG_ 1091 RDK_Status "Status der RDK /nRDK Status Eins/Aus; 0 = System a";
CM_ SG_ 1091 RDK_Sensor_Multiplex "Multiplexinformation fuer die Auswahl eines Reifen";
CM_ SG_ 1091 RDK_Prio2_Warnung "Prio 2 Warnung fuer Kombi /n1 = Prio 2 Warnung";
CM_ SG_ 1091 RDK_Prio1_Warnung "Prio 1 Warnung fuer Kombi /n1 = Prio 1 Warnung";
CM_ SG_ 1091 RDK_neue_Solldruecke "RDK hat neue Solldruecke erkannt /n0 = keine neuen";
CM_ SG_ 1091 RDK_KD_Fehler "Kundendienstfehler /n1 = mindestens ein Fehler im";
CM_ SG_ 1091 RDK_Geschw_Warnung "Geschwindigkeitswarnung /n1 = Geschwindigkeitswarn";
CM_ SG_ 1091 RDK_Ack_IstZu_Solldruecke "Die aktuellen Istdruecke wurden zu neuen Solldruec";
CM_ BO_ 1633 "
Byte 1:Statusmeldung
Byte 2:Mode
Byte 3:Parameter_1
Byte 4:Parameter_2
Byte 5:Parameter_3
Byte 6:Parameter_4
Byte 7:Parameter_5
Byte 8:Parameter_6";
CM_ SG_ 1633 RA4_Show_Radio "Display_requirement_Vorhalt /n1 =Display request,";
CM_ SG_ 1633 RA4_Radio_Para6 "Vorhalt";
CM_ SG_ 1633 RA4_Radio_Para5 "Vorhalt";
CM_ SG_ 1633 RA4_Radio_Para4 "Parameter des jew. Modes";
CM_ SG_ 1633 RA4_Radio_Para3 "Parameter des jew. Modes /nbei Parmeter_2=12";
CM_ SG_ 1633 RA4_Radio_Para2 "Parameter des jew. Modes /n=12h (normaler Status)";
CM_ SG_ 1633 RA4_Radio_Para1 "Parameter des jew. Modes";
CM_ SG_ 1633 RA4_Radio_on "Radio ist eingeschaltet /n1 = Radio ein, 0 = Radio";
CM_ SG_ 1633 RA4_Radio_mute "NF_reqirement_Vorhalt /nVorhalt fuer NF request";
CM_ SG_ 1633 RA4_Radio_Mode "Mode-Information /n(01h: default)";
CM_ SG_ 1633 RA4_Radio_Master_locked "Radiokomponenten gesperrt nach Kl. 30 /n1 = Radio";
CM_ SG_ 1633 RA4_Radio_Error_flag "Fehlereintrag vorhanden";
CM_ BO_ 1519 "
Byte 1:Status_PTC
Byte 2:PTC_Iststrom
Byte 3:PTC_Nennstrom";
CM_ SG_ 1519 PT1_Nenn_Strom "Summe der Nennstroeme aller PTC-Heizelemente";
CM_ SG_ 1519 PT1_KD_Fehler "Kundendienstfehler im SG vorhanden /n1 = mindesten";
CM_ SG_ 1519 PT1_Ist_Strom "Summe der Iststroeme aller PTC-Heizelemente";
CM_ SG_ 1519 PT1_Fehlerstatus "Fehlerstatus PTC Zuheizer /n0 = kein Fehler; 1 = U";
CM_ SG_ 1519 PT1_Fehler_Nenn_Strom "Fehler bei der Nennstromermittlung /n1 = Fehler be";
CM_ SG_ 1519 PT1_Fehler_Ist_Strom "Fehler bei der Iststromermittlung /n1 = Fehler bei";
CM_ SG_ 1519 PT1_Aktiv "PTC-Elemente werden angesteuert /n1 = PTC-Elemente";
CM_ BO_ 1349 "
Byte 1:Statusmeldung_1
Byte 2:Statusmeldung_2
Byte 3:Fehlerstatus
Byte 4:Statusmeldung_3";
CM_ SG_ 1349 PA3_Tongeber_v_defekt "Tongeber Vorne defekt /n1 = Tongeber Vorne ist def";
CM_ SG_ 1349 PA3_Tongeber_h_defekt "Tongeber Hinten defekt /n1 = Tongeber Hinten ist d";
CM_ SG_ 1349 PA3_Taster_aktiviert "Aktivierung durch Taster (Nur 8-Kanal) /n1 = Anlag";
CM_ SG_ 1349 PA3_System_codierung "8/4-Kanal-Anlage /n'0 = 4 Kanal PDC / 1 = 8 Kanal";
CM_ SG_ 1349 PA3_Sensor_vrr_defekt "Sensor vorn rechts rechts defekt /n0 = Sensor OK /";
CM_ SG_ 1349 PA3_Sensor_vrm_defekt "Sensor vorn rechts mitte defekt /n0 = Sensor OK /";
CM_ SG_ 1349 PA3_Sensor_vlm_defekt "Sensor vorn links mitte defekt /n0 = Sensor OK / 1";
CM_ SG_ 1349 PA3_Sensor_vll_defekt "Sensor vorn links links defekt /n0 = Sensor OK / 1";
CM_ SG_ 1349 PA3_Sensor_hrr_defekt "Sensor hinten rechts rechts defekt /n0 = Sensor OK";
CM_ SG_ 1349 PA3_Sensor_hrm_defekt "Sensor hinten rechts mitte defekt /n0 = Sensor OK";
CM_ SG_ 1349 PA3_Sensor_hlm_defekt "Sensor hinten links mitte defekt /n0 = Sensor OK /";
CM_ SG_ 1349 PA3_Sensor_hll_defekt "Sensor hinten links links defekt /n0 = Sensor OK /";
CM_ SG_ 1349 PA3_Schlechtweg_aus "Abschaltung wegen Schlechtweg /n1 = Aufgrund von s";
CM_ SG_ 1349 PA3_Rueckwaertsgang_aktiv "Aktivierung durch Rueckwaertsgang /n1 = Anlage wur";
CM_ SG_ 1349 PA3_KD_Fehler "Kundendienstfehler /n1 = mindestens ein Fehler ist";
CM_ SG_ 1349 PA3_Geschwindigkeit_aus "v_signal_Abschaltung /n1 = Durch Erreichen von vMa";
CM_ SG_ 1349 PA3_Eis_aus "Abschaltung wegen Eiserkennung /n1 = Wegen erkannt";
CM_ SG_ 1349 PA3_Bereit "PDC-Betriebsbereitschaft /n1 = PDC ist Betriebsber";
CM_ SG_ 1349 PA3_Bereich_vo "Bereichserkennung vorn /n'0 = Initwert (Ausserhalb";
CM_ SG_ 1349 PA3_Bereich_hi "Bereichserkennung hinten /n'0 = Initwert (Ausserha";
CM_ SG_ 1349 PA3_Aufbau_erk "Aufbauten erkannt";
CM_ SG_ 1349 PA3_Anlage_defekt "Anlage defekt /n1 = PDC wurde aufgrund eines Defek";
CM_ SG_ 1349 PA3_Akust_aus "Akustische Ausgabe der PDC abschalten /n1 = Tonaus";
CM_ BO_ 1025 "
Byte 1:NM_Message
Byte 2:NM_Message
Byte 4:NM_WakeUp_Appl1";
CM_ SG_ 1025 NMZK_ZK_Neigungssensor "Weckursache: Neigungssensor Ausloesung";
CM_ SG_ 1025 NMZK_SleepInd "BusSleep Indication";
CM_ SG_ 1025 NMZK_SleepAck "BusSleep Acknowledge";
CM_ SG_ 1025 NMZK_Receiver "SG_Adresse /nBelegung Weckursachen Audi";
CM_ SG_ 1025 NMZK_NWake "Weckursache: NWake-Eingang";
CM_ SG_ 1025 NMZK_Kl_30_Reset "Weckursache: Klemme 30 Reset";
CM_ SG_ 1025 NMZK_IRUE_Ausloesung "Weckursache: IRUE-Ausloesung";
CM_ SG_ 1025 NMZK_HD_Vorraste "Weckursache: Heckdeckel-Vorraste";
CM_ SG_ 1025 NMZK_HD_Taster "Weckursache: Taster Heckdeckel";
CM_ SG_ 1025 NMZK_HD_Schloss_zu "Weckursache: Heckschloss zu";
CM_ SG_ 1025 NMZK_HD_Schloss_auf "Weckursache: Heckschloss auf";
CM_ SG_ 1025 NMZK_HD_Hauptraste "Weckursache: Heckdeckel-Hauptraste";
CM_ SG_ 1025 NMZK_Fond_Lock "Weckursache: Fond Lock /nVariante";
CM_ SG_ 1025 NMZK_Fkt_Nachlauf "Weckursache: Ablauf Timer Funktionsnachlauf";
CM_ SG_ 1025 NMZK_CmdRing "Ring Message";
CM_ SG_ 1025 NMZK_CmdLimpHome "Limp Home Message";
CM_ SG_ 1025 NMZK_CmdAlive "Alive Message";
CM_ SG_ 1025 NMZK_CAN "Weckursache: CAN";
CM_ SG_ 1025 NMZK_Bremslicht "Weckursache: Bremslicht /nVariante";
CM_ BO_ 1040 "
Byte 1:NM_Message
Byte 2:NM_Message";
CM_ SG_ 1040 NMVSG_SleepInd "BusSleep Indication";
CM_ SG_ 1040 NMVSG_SleepAck "BusSleep Acknowledge";
CM_ SG_ 1040 NMVSG_Receiver "SG_Adresse /nVerdecksteuergeraet, Grossdach-SG";
CM_ SG_ 1040 NMVSG_NWake "Weckursache: NWake-Eingang";
CM_ SG_ 1040 NMVSG_Kl_30_Reset "Weckursache: Klemme 30 Reset";
CM_ SG_ 1040 NMVSG_Fkt_Nachlauf "Weckursache: Ablauf Timer Funktionsnachlauf";
CM_ SG_ 1040 NMVSG_CmdRing "Ring Message";
CM_ SG_ 1040 NMVSG_CmdLimpHome "Limp Home Message";
CM_ SG_ 1040 NMVSG_CmdAlive "Alive Message";
CM_ SG_ 1040 NMVSG_CAN "Weckursache: CAN";
CM_ BO_ 1029 "
Byte 1:NM_Message
Byte 2:NM_Message
Byte 4:NM_WakeUp_Appl1
Byte 5:NM_WakeUp_Appl2";
CM_ SG_ 1029 NMHR_Verr_Zustand "Weckursache: Aenderung Verriegelungszustand Tuersc";
CM_ SG_ 1029 NMHR_Verr_Taster "Weckursache: Verriegelungstaster betaetigt";
CM_ SG_ 1029 NMHR_Unlock "Weckursache: Unlock-Taster";
CM_ SG_ 1029 NMHR_Tuergriff_Innern "Weckursache: Tuergriff innen betaetigt";
CM_ SG_ 1029 NMHR_Tuergriff_Aussen "Weckursache: Tuergriff aussen betaetigt";
CM_ SG_ 1029 NMHR_SleepInd "BusSleep Indication";
CM_ SG_ 1029 NMHR_SleepAck "BusSleep Acknowledge";
CM_ SG_ 1029 NMHR_Safe_Zustand "Weckursache: Aenderung Safe Zustand Tuerschloss";
CM_ SG_ 1029 NMHR_Receiver "SG_Adresse";
CM_ SG_ 1029 NMHR_PTT_Taste "Weckursache Push To Talk betaetigt";
CM_ SG_ 1029 NMHR_NWake "Weckursache: NWake-Eingang";
CM_ SG_ 1029 NMHR_Lock "Weckursache: Lock-Taster";
CM_ SG_ 1029 NMHR_Kl_30_Reset "Weckursache: Klemme 30 Reset";
CM_ SG_ 1029 NMHR_Fkt_Nachlauf "Weckursache: Ablauf Timer Funktionsnachlauf";
CM_ SG_ 1029 NMHR_Drehfalle "Weckursache: Drehfalle";
CM_ SG_ 1029 NMHR_CmdRing "Ring Message";
CM_ SG_ 1029 NMHR_CmdLimpHome "Limp Home Message";
CM_ SG_ 1029 NMHR_CmdAlive "Alive Message";
CM_ SG_ 1029 NMHR_CAN "Weckursache: CAN";
CM_ BO_ 1028 "
Byte 1:NM_Message
Byte 2:NM_Message
Byte 4:NM_WakeUp_Appl1
Byte 5:NM_WakeUp_Appl2";
CM_ SG_ 1028 NMHL_Verr_Zustand "Weckursache: Aenderung Verriegelungszustand Tuersc";
CM_ SG_ 1028 NMHL_Verr_Taster "Weckursache: Verriegelungstaster betaetigt";
CM_ SG_ 1028 NMHL_Unlock "Weckursache: Unlock-Taster";
CM_ SG_ 1028 NMHL_Tuergriff_Innern "Weckursache: Tuergriff innen betaetigt";
CM_ SG_ 1028 NMHL_Tuergriff_Aussen "Weckursache: Tuergriff aussen betaetigt";
CM_ SG_ 1028 NMHL_SleepInd "BusSleep Indication";
CM_ SG_ 1028 NMHL_SleepAck "BusSleep Acknowledge";
CM_ SG_ 1028 NMHL_Safe_Zustand "Weckursache: Aenderung Safe Zustand Tuerschloss";
CM_ SG_ 1028 NMHL_Receiver "SG_Adresse";
CM_ SG_ 1028 NMHL_PTT_Taste "Weckursache: Push To Talk betaetigt";
CM_ SG_ 1028 NMHL_NWake "Weckursache: NWake-Eingang";
CM_ SG_ 1028 NMHL_Lock "Weckursache: Lock-Taster";
CM_ SG_ 1028 NMHL_Kl_30_Reset "Weckursache: Klemme 30 Reset";
CM_ SG_ 1028 NMHL_Fkt_Nachlauf "Weckursache: Ablauf Timer Funktionsnachlauf";
CM_ SG_ 1028 NMHL_Drehfalle "Weckursache: Drehfalle";
CM_ SG_ 1028 NMHL_CmdRing "Ring Message";
CM_ SG_ 1028 NMHL_CmdLimpHome "Limp Home Message";
CM_ SG_ 1028 NMHL_CmdAlive "Alive Message";
CM_ SG_ 1028 NMHL_CAN "Weckursache: CAN";
CM_ BO_ 1026 "
Byte 1:NM_Message
Byte 2:NM_Message
Byte 4:NM_WakeUp_Appl1
Byte 5:NM_WakeUp_Appl2
Byte 6:NM_WakeUp_Appl3";
CM_ SG_ 1026 NMFT_Verr_Zustand "Weckursache: Aenderung Verriegelungszustand Tuersc";
CM_ SG_ 1026 NMFT_Verr_Taster "Verriegelungstaster betaetigt";
CM_ SG_ 1026 NMFT_Unlock "Weckursache: Unlock-Taster /nVariante";
CM_ SG_ 1026 NMFT_Tuergriff_Innern "Weckursache: Tuergriff innen betaetigt";
CM_ SG_ 1026 NMFT_Tuergriff_Aussen "Weckursache: Tuergriff aussen betaetigt";
CM_ SG_ 1026 NMFT_Taster_Tankklappe "Weckursache: Taster Tankklappe betaetigt";
CM_ SG_ 1026 NMFT_SleepInd "BusSleep Indication";
CM_ SG_ 1026 NMFT_SleepAck "BusSleep Acknowledge";
CM_ SG_ 1026 NMFT_Schloss_zu "Weckursache: Schluesselschalter zu";
CM_ SG_ 1026 NMFT_Schloss_auf "Weckursache: Schluesselschalter auf";
CM_ SG_ 1026 NMFT_Safe_Zustand "Weckursache: Aenderung Safe Zustand Tuerschloss";
CM_ SG_ 1026 NMFT_Receiver "SG_Adresse";
CM_ SG_ 1026 NMFT_NWake "Weckursache: NWake-Eingang";
CM_ SG_ 1026 NMFT_Lock "Weckursache: Lock-Taster /nVariante";
CM_ SG_ 1026 NMFT_Kl_30_Reset "Weckursache: Klemme 30 Reset";
CM_ SG_ 1026 NMFT_Fkt_Nachlauf "Weckursache: Ablauf Timer Funktionsnachlauf";
CM_ SG_ 1026 NMFT_FH_Fahrer "Weckursache: Fensterheberbedienfeld /nWecken erfol";
CM_ SG_ 1026 NMFT_Drehfalle "Weckursache: Drehfalle";
CM_ SG_ 1026 NMFT_CmdRing "Ring Message";
CM_ SG_ 1026 NMFT_CmdLimpHome "Limp Home Message";
CM_ SG_ 1026 NMFT_CmdAlive "Alive Message";
CM_ SG_ 1026 NMFT_CAN "Weckursache: CAN";
CM_ BO_ 1027 "
Byte 1:NM_Message
Byte 2:NM_Message
Byte 4:NM_WakeUp_Appl1
Byte 5:NM_WakeUp_Appl2";
CM_ SG_ 1027 NMBT_Verr_Zustand "Weckursache: Aenderung Verriegelungszustand Tuersc";
CM_ SG_ 1027 NMBT_Verr_Taster "Weckursache: Verriegelungstaster betaetigt";
CM_ SG_ 1027 NMBT_Unlock "Weckursache: Unlock-Taster /nVariante";
CM_ SG_ 1027 NMBT_Tuergriff_Innern "Weckursache: Tuergriff innen betaetigt";
CM_ SG_ 1027 NMBT_Tuergriff_Aussen "Weckursache: Tuergriff aussen betaetigt";
CM_ SG_ 1027 NMBT_SleepInd "BusSleep Indication";
CM_ SG_ 1027 NMBT_SleepAck "BusSleep Acknowledge";
CM_ SG_ 1027 NMBT_Schloss_zu "Weckursache: Schluesselschalter zu";
CM_ SG_ 1027 NMBT_Schloss_auf "Weckursache: Schluesselschalter auf";
CM_ SG_ 1027 NMBT_Safe_Zustand "Weckursache: Aenderung Safe Zustand Tuerschloss";
CM_ SG_ 1027 NMBT_Receiver "SG_Adresse";
CM_ SG_ 1027 NMBT_PTT_Taster "Weckursache Push To Talk betaetigt";
CM_ SG_ 1027 NMBT_NWake "Weckursache: NWake-Eingang";
CM_ SG_ 1027 NMBT_Lock "Weckursache: Lock-Taster /nVariante";
CM_ SG_ 1027 NMBT_Kl_30_Reset "Weckursache: Klemme 30 Reset";
CM_ SG_ 1027 NMBT_Fkt_Nachlauf "Weckursache: Ablauf Timer Funktionsnachlauf";
CM_ SG_ 1027 NMBT_Drehfalle "Weckursache: Drehfalle";
CM_ SG_ 1027 NMBT_CmdRing "Ring Message";
CM_ SG_ 1027 NMBT_CmdLimpHome "Limp Home Message";
CM_ SG_ 1027 NMBT_CmdAlive "Alive Message";
CM_ SG_ 1027 NMBT_CAN "Weckursache: CAN";
CM_ BO_ 1034 "
Byte 1:NM_Message
Byte 2:NM_Message
Byte 4:NM_WakeUp_Appl1";
CM_ SG_ 1034 NMLS_SleepInd "BusSleep Indication";
CM_ SG_ 1034 NMLS_SleepAck "BusSleep Acknowledge";
CM_ SG_ 1034 NMLS_S_Kontakt_ein_aus "Weckursache: S-Kontakt Zustandsaenderung ein-aus";
CM_ SG_ 1034 NMLS_S_Kontakt_aus_ein "Weckursache: S-Kontakt Zustandsaenderung aus-ein";
CM_ SG_ 1034 NMLS_Receiver "SG_Adresse /nSMLS: Schaltermodul Lenksaeule, Lenks";
CM_ SG_ 1034 NMLS_Parklicht_ein_aus "Weckursache: Parklicht Zustandsaenderung ein-aus";
CM_ SG_ 1034 NMLS_Parklicht_aus_ein "Weckursache: Parklicht Zustandsaenderung aus-ein";
CM_ SG_ 1034 NMLS_NWake "Weckursache: NWake-Eingang";
CM_ SG_ 1034 NMLS_LSV "Weckursache: Betaetigung Lenksaeulenverstellschalt";
CM_ SG_ 1034 NMLS_Lichthupe_ein_aus "Weckursache : Lichthupe Zustandsaenderung ein-aus";
CM_ SG_ 1034 NMLS_Lichthupe_aus_ein "Weckursache : Lichthupe Zustandsaenderung aus-ein";
CM_ SG_ 1034 NMLS_Klemme15 "Weckursache: Klemme 15 Zustandsaenderung aus-ein";
CM_ SG_ 1034 NMLS_Kl_30_Reset "Weckursache: Klemme 30 Reset";
CM_ SG_ 1034 NMLS_Fkt_Nachlauf "Weckursache: Ablauf Timer Funktionsnachlauf";
CM_ SG_ 1034 NMLS_CmdRing "Ring Message";
CM_ SG_ 1034 NMLS_CmdLimpHome "Limp Home Message";
CM_ SG_ 1034 NMLS_CmdAlive "Alive Message";
CM_ SG_ 1034 NMLS_CAN "Weckursache: CAN";
BA_DEF_ BO_  "VAGTP20_StatConnection" ENUM  "nein","ja";
BA_DEF_ SG_  "GenSigTimeoutTime_<ECU>" HEX 0 2047;
BA_DEF_ SG_  "GenSigTimeoutMsg_<ECU>" HEX 0 2047;
BA_DEF_ SG_  "GenSigInactiveValue" HEX 0 134217727;
BA_DEF_ SG_  "GenSigSendType" ENUM  "Cyclic","OnWrite","OnWriteWithRepetition","OnChange","OnChangeWithRepetition","IfActive","IfActiveWithRepetition","NoSigSendType";
BA_DEF_ BO_  "GenMsgTimeoutTime" INT 0 100000;
BA_DEF_ BO_  "GenMsgNrOfRepetition" INT 0 100;
BA_DEF_ BO_  "GenMsgNoIalSupport" ENUM  "No","Yes";
BA_DEF_ BO_  "GenMsgStartDelayTime" INT 0 100000;
BA_DEF_ BO_  "GenMsgCycleTimeFast" INT 0 65535;
BA_DEF_ BO_  "GenMsgDelayTime" INT 0 100000;
BA_DEF_ BU_  "MessageManagerUsed" ENUM  "No","Yes";
BA_DEF_ BO_  "VAGTP20_DynConnection" ENUM  "nein","ja";
BA_DEF_ BO_  "VAGTP20_DynSetup" ENUM  "nein","ja";
BA_DEF_ BU_  "VAGTP20_TargetAddress" HEX 0 127;
BA_DEF_ BU_  "GenNodAutoGenDsp" ENUM  "Yes","No";
BA_DEF_ BU_  "GenNodAutoGenSnd" ENUM  "Yes","No";
BA_DEF_ BU_  "GenNodSleepTime" INT 0 1000000;
BA_DEF_ BU_  "NodeLayerModules" STRING ;
BA_DEF_  "NWMMessageCount" INT 0 64;
BA_DEF_ BO_  "xVWTP_Channel" ENUM  "nein","ja";
BA_DEF_ BO_  "xVWTP_Setup" ENUM  "nein","ja";
BA_DEF_ SG_  "SignalRepeatDeactivation" INT 0 20;
BA_DEF_ SG_  "SignalRepeatActivation" INT 0 20;
BA_DEF_  "Manufacturer" ENUM  "DBAG","VAG","BMWAG","PAG","GM";
BA_DEF_ BU_  "NWM-Stationsadresse" INT 0 63;
BA_DEF_ BU_  "NWM-Knoten" ENUM  "nein","ja";
BA_DEF_ BO_  "GenMsgSendType" ENUM  "cyclicX","spontanX","cyclicIfActiveX","spontanWithDelay","cyclicAndSpontanX","cyclicAndSpontanWithDelay","spontanWithRepitition","cyclicIfActiveAndSpontanWD","cyclicIfActiveFast","cyclicWithRepeatOnDemand";
BA_DEF_ BO_  "GenMsgCycleTime" INT 0 65535;
BA_DEF_ BO_  "NWM-Botschaft" ENUM  "nein","ja";
BA_DEF_  "NWM-Basisadresse 4" HEX 0 536870911;
BA_DEF_  "NWM-Basisadresse 3" HEX 0 536870911;
BA_DEF_  "NWM-Basisadresse 2" HEX 0 536870911;
BA_DEF_  "NWM-Basisadresse 1" HEX 0 536870911;
BA_DEF_  "NWM-Typ" ENUM  "zentral (MB-W210)","dezentral (MB-OSAN)","keines","VAG-OSEK","BMW-OSEK","PAG-OSEK","DBAG-OSEK";
BA_DEF_DEF_  "VAGTP20_API" 0;
BA_DEF_DEF_  "VAGTP20_StatConnection" "";
BA_DEF_DEF_  "GenSigTimeoutTime_<ECU>" 0;
BA_DEF_DEF_  "GenSigTimeoutMsg_<ECU>" 0;
BA_DEF_DEF_  "GenSigInactiveValue" 0;
BA_DEF_DEF_  "GenSigSendType" "";
BA_DEF_DEF_  "GenMsgTimeoutTime" 0;
BA_DEF_DEF_  "GenMsgNrOfRepetition" 0;
BA_DEF_DEF_  "GenMsgNoIalSupport" "";
BA_DEF_DEF_  "GenMsgStartDelayTime" 0;
BA_DEF_DEF_  "GenMsgCycleTimeFast" 0;
BA_DEF_DEF_  "GenMsgDelayTime" 0;
BA_DEF_DEF_  "MessageManagerUsed" "";
BA_DEF_DEF_  "VAGTP20_DynConnection" "";
BA_DEF_DEF_  "VAGTP20_DynSetup" "";
BA_DEF_DEF_  "VAGTP20_TargetAddress" 0;
BA_DEF_DEF_  "GenNodAutoGenDsp" "";
BA_DEF_DEF_  "GenNodAutoGenSnd" "";
BA_DEF_DEF_  "GenNodSleepTime" 0;
BA_DEF_DEF_  "NodeLayerModules" "";
BA_DEF_DEF_  "NWMMessageCount" 64;
BA_DEF_DEF_  "xVWTP_Channel" "";
BA_DEF_DEF_  "xVWTP_Setup" "";
BA_DEF_DEF_  "SignalRepeatDeactivation" 0;
BA_DEF_DEF_  "SignalRepeatActivation" 0;
BA_DEF_DEF_  "Manufacturer" "VAG";
BA_DEF_DEF_  "NWM-Stationsadresse" 0;
BA_DEF_DEF_  "NWM-Knoten" "";
BA_DEF_DEF_  "GenMsgSendType" "";
BA_DEF_DEF_  "GenMsgCycleTime" 0;
BA_DEF_DEF_  "NWM-Botschaft" "";
BA_DEF_DEF_  "NWM-Basisadresse 4" 1048;
BA_DEF_DEF_  "NWM-Basisadresse 3" 1040;
BA_DEF_DEF_  "NWM-Basisadresse 2" 1032;
BA_DEF_DEF_  "NWM-Basisadresse 1" 1024;
BA_DEF_DEF_  "NWM-Typ" "VAG-OSEK";
BA_ "NodeLayerModules" BU_ Verdeck "Vagnm01.dll";
BA_ "GenNodSleepTime" BU_ Verdeck 5000;
BA_ "GenNodAutoGenSnd" BU_ Verdeck 0;
BA_ "GenNodAutoGenDsp" BU_ Verdeck 0;
BA_ "VAGTP20_TargetAddress" BU_ Verdeck 48;
BA_ "MessageManagerUsed" BU_ Verdeck 0;
BA_ "NWM-Knoten" BU_ Verdeck 1;
BA_ "NWM-Stationsadresse" BU_ Verdeck 16;
BA_ "NodeLayerModules" BU_ TSG_Fahrer "Vagnm01.dll";
BA_ "GenNodSleepTime" BU_ TSG_Fahrer 5000;
BA_ "GenNodAutoGenSnd" BU_ TSG_Fahrer 0;
BA_ "GenNodAutoGenDsp" BU_ TSG_Fahrer 0;
BA_ "VAGTP20_TargetAddress" BU_ TSG_Fahrer 34;
BA_ "MessageManagerUsed" BU_ TSG_Fahrer 0;
BA_ "NWM-Knoten" BU_ TSG_Fahrer 1;
BA_ "NWM-Stationsadresse" BU_ TSG_Fahrer 2;
BA_ "NodeLayerModules" BU_ TSG_Beifahrer "Vagnm01.dll";
BA_ "GenNodSleepTime" BU_ TSG_Beifahrer 5000;
BA_ "GenNodAutoGenSnd" BU_ TSG_Beifahrer 0;
BA_ "GenNodAutoGenDsp" BU_ TSG_Beifahrer 0;
BA_ "VAGTP20_TargetAddress" BU_ TSG_Beifahrer 35;
BA_ "MessageManagerUsed" BU_ TSG_Beifahrer 0;
BA_ "NWM-Knoten" BU_ TSG_Beifahrer 1;
BA_ "NWM-Stationsadresse" BU_ TSG_Beifahrer 3;
BA_ "NodeLayerModules" BU_ Standheizung "Vagnm01.dll";
BA_ "GenNodSleepTime" BU_ Standheizung 5000;
BA_ "GenNodAutoGenSnd" BU_ Standheizung 0;
BA_ "GenNodAutoGenDsp" BU_ Standheizung 0;
BA_ "VAGTP20_TargetAddress" BU_ Standheizung 47;
BA_ "MessageManagerUsed" BU_ Standheizung 0;
BA_ "NWM-Knoten" BU_ Standheizung 1;
BA_ "NWM-Stationsadresse" BU_ Standheizung 15;
BA_ "NodeLayerModules" BU_ SMLS "Vagnm01.dll";
BA_ "GenNodSleepTime" BU_ SMLS 5000;
BA_ "GenNodAutoGenSnd" BU_ SMLS 0;
BA_ "GenNodAutoGenDsp" BU_ SMLS 0;
BA_ "VAGTP20_TargetAddress" BU_ SMLS 42;
BA_ "MessageManagerUsed" BU_ SMLS 0;
BA_ "NWM-Knoten" BU_ SMLS 1;
BA_ "NWM-Stationsadresse" BU_ SMLS 10;
BA_ "NodeLayerModules" BU_ SitzMemo_Fahrer "Vagnm01.dll";
BA_ "GenNodSleepTime" BU_ SitzMemo_Fahrer 5000;
BA_ "GenNodAutoGenSnd" BU_ SitzMemo_Fahrer 0;
BA_ "GenNodAutoGenDsp" BU_ SitzMemo_Fahrer 0;
BA_ "VAGTP20_TargetAddress" BU_ SitzMemo_Fahrer 38;
BA_ "MessageManagerUsed" BU_ SitzMemo_Fahrer 0;
BA_ "NWM-Knoten" BU_ SitzMemo_Fahrer 1;
BA_ "NWM-Stationsadresse" BU_ SitzMemo_Fahrer 6;
BA_ "NodeLayerModules" BU_ SitzMemo_Beifahrer "Vagnm01.dll";
BA_ "GenNodSleepTime" BU_ SitzMemo_Beifahrer 5000;
BA_ "GenNodAutoGenSnd" BU_ SitzMemo_Beifahrer 0;
BA_ "GenNodAutoGenDsp" BU_ SitzMemo_Beifahrer 0;
BA_ "VAGTP20_TargetAddress" BU_ SitzMemo_Beifahrer 53;
BA_ "MessageManagerUsed" BU_ SitzMemo_Beifahrer 0;
BA_ "NWM-Knoten" BU_ SitzMemo_Beifahrer 1;
BA_ "NWM-Stationsadresse" BU_ SitzMemo_Beifahrer 21;
BA_ "NodeLayerModules" BU_ Reifendruck_VW "Vagnm01.dll";
BA_ "GenNodSleepTime" BU_ Reifendruck_VW 5000;
BA_ "GenNodAutoGenSnd" BU_ Reifendruck_VW 0;
BA_ "GenNodAutoGenDsp" BU_ Reifendruck_VW 0;
BA_ "VAGTP20_TargetAddress" BU_ Reifendruck_VW 41;
BA_ "MessageManagerUsed" BU_ Reifendruck_VW 0;
BA_ "NWM-Knoten" BU_ Reifendruck_VW 0;
BA_ "NodeLayerModules" BU_ Reifendruck_Audi "Vagnm01.dll";
BA_ "GenNodSleepTime" BU_ Reifendruck_Audi 5000;
BA_ "GenNodAutoGenSnd" BU_ Reifendruck_Audi 0;
BA_ "GenNodAutoGenDsp" BU_ Reifendruck_Audi 0;
BA_ "VAGTP20_TargetAddress" BU_ Reifendruck_Audi 41;
BA_ "MessageManagerUsed" BU_ Reifendruck_Audi 0;
BA_ "NWM-Knoten" BU_ Reifendruck_Audi 1;
BA_ "NWM-Stationsadresse" BU_ Reifendruck_Audi 9;
BA_ "NodeLayerModules" BU_ PTC_Heizung "Vagnm01.dll";
BA_ "GenNodSleepTime" BU_ PTC_Heizung 5000;
BA_ "GenNodAutoGenSnd" BU_ PTC_Heizung 0;
BA_ "GenNodAutoGenDsp" BU_ PTC_Heizung 0;
BA_ "VAGTP20_TargetAddress" BU_ PTC_Heizung 46;
BA_ "MessageManagerUsed" BU_ PTC_Heizung 0;
BA_ "NWM-Knoten" BU_ PTC_Heizung 1;
BA_ "NWM-Stationsadresse" BU_ PTC_Heizung 14;
BA_ "NodeLayerModules" BU_ Multifunktions_SG "Vagnm01.dll";
BA_ "GenNodSleepTime" BU_ Multifunktions_SG 5000;
BA_ "GenNodAutoGenSnd" BU_ Multifunktions_SG 0;
BA_ "GenNodAutoGenDsp" BU_ Multifunktions_SG 0;
BA_ "VAGTP20_TargetAddress" BU_ Multifunktions_SG 58;
BA_ "MessageManagerUsed" BU_ Multifunktions_SG 0;
BA_ "NWM-Knoten" BU_ Multifunktions_SG 1;
BA_ "NWM-Stationsadresse" BU_ Multifunktions_SG 26;
BA_ "NodeLayerModules" BU_ Komfort_SG "Vagnm01.dll";
BA_ "GenNodSleepTime" BU_ Komfort_SG 5000;
BA_ "GenNodAutoGenSnd" BU_ Komfort_SG 0;
BA_ "GenNodAutoGenDsp" BU_ Komfort_SG 0;
BA_ "VAGTP20_TargetAddress" BU_ Komfort_SG 33;
BA_ "MessageManagerUsed" BU_ Komfort_SG 0;
BA_ "NWM-Knoten" BU_ Komfort_SG 1;
BA_ "NWM-Stationsadresse" BU_ Komfort_SG 1;
BA_ "NodeLayerModules" BU_ Gateway_K "Vagnm01.dll";
BA_ "GenNodSleepTime" BU_ Gateway_K 5000;
BA_ "GenNodAutoGenSnd" BU_ Gateway_K 0;
BA_ "GenNodAutoGenDsp" BU_ Gateway_K 0;
BA_ "VAGTP20_TargetAddress" BU_ Gateway_K 31;
BA_ "MessageManagerUsed" BU_ Gateway_K 0;
BA_ "NWM-Knoten" BU_ Gateway_K 1;
BA_ "NWM-Stationsadresse" BU_ Gateway_K 11;
BA_ "NodeLayerModules" BU_ FHSG_hinten_rechts "Vagnm01.dll";
BA_ "GenNodSleepTime" BU_ FHSG_hinten_rechts 5000;
BA_ "GenNodAutoGenSnd" BU_ FHSG_hinten_rechts 0;
BA_ "GenNodAutoGenDsp" BU_ FHSG_hinten_rechts 0;
BA_ "VAGTP20_TargetAddress" BU_ FHSG_hinten_rechts 37;
BA_ "MessageManagerUsed" BU_ FHSG_hinten_rechts 0;
BA_ "NWM-Knoten" BU_ FHSG_hinten_rechts 1;
BA_ "NWM-Stationsadresse" BU_ FHSG_hinten_rechts 5;
BA_ "NodeLayerModules" BU_ FHSG_hinten_links "Vagnm01.dll";
BA_ "GenNodSleepTime" BU_ FHSG_hinten_links 5000;
BA_ "GenNodAutoGenSnd" BU_ FHSG_hinten_links 0;
BA_ "GenNodAutoGenDsp" BU_ FHSG_hinten_links 0;
BA_ "VAGTP20_TargetAddress" BU_ FHSG_hinten_links 36;
BA_ "MessageManagerUsed" BU_ FHSG_hinten_links 0;
BA_ "NWM-Knoten" BU_ FHSG_hinten_links 1;
BA_ "NWM-Stationsadresse" BU_ FHSG_hinten_links 4;
BA_ "NodeLayerModules" BU_ Einparkhilfe "Vagnm01.dll";
BA_ "GenNodSleepTime" BU_ Einparkhilfe 5000;
BA_ "GenNodAutoGenSnd" BU_ Einparkhilfe 0;
BA_ "GenNodAutoGenDsp" BU_ Einparkhilfe 0;
BA_ "VAGTP20_TargetAddress" BU_ Einparkhilfe 45;
BA_ "MessageManagerUsed" BU_ Einparkhilfe 0;
BA_ "NWM-Knoten" BU_ Einparkhilfe 1;
BA_ "NWM-Stationsadresse" BU_ Einparkhilfe 13;
BA_ "NodeLayerModules" BU_ Clima "Vagnm01.dll";
BA_ "GenNodSleepTime" BU_ Clima 5000;
BA_ "GenNodAutoGenSnd" BU_ Clima 0;
BA_ "GenNodAutoGenDsp" BU_ Clima 0;
BA_ "VAGTP20_TargetAddress" BU_ Clima 44;
BA_ "MessageManagerUsed" BU_ Clima 0;
BA_ "NWM-Knoten" BU_ Clima 1;
BA_ "NWM-Stationsadresse" BU_ Clima 12;
BA_ "NodeLayerModules" BU_ BSG "Vagnm01.dll";
BA_ "GenNodSleepTime" BU_ BSG 5000;
BA_ "GenNodAutoGenSnd" BU_ BSG 0;
BA_ "GenNodAutoGenDsp" BU_ BSG 0;
BA_ "VAGTP20_TargetAddress" BU_ BSG 50;
BA_ "MessageManagerUsed" BU_ BSG 0;
BA_ "NWM-Knoten" BU_ BSG 1;
BA_ "NodeLayerModules" BU_ Anhaenger_SG "Vagnm01.dll";
BA_ "GenNodSleepTime" BU_ Anhaenger_SG 5000;
BA_ "GenNodAutoGenSnd" BU_ Anhaenger_SG 0;
BA_ "GenNodAutoGenDsp" BU_ Anhaenger_SG 0;
BA_ "VAGTP20_TargetAddress" BU_ Anhaenger_SG 67;
BA_ "MessageManagerUsed" BU_ Anhaenger_SG 0;
BA_ "NWM-Knoten" BU_ Anhaenger_SG 1;
BA_ "NWM-Stationsadresse" BU_ Anhaenger_SG 20;
BA_ "GenMsgCycleTime" BO_ 1425 200;
BA_ "GenMsgSendType" BO_ 1425 5;
BA_ "xVWTP_Setup" BO_ 1425 0;
BA_ "xVWTP_Channel" BO_ 1425 0;
BA_ "VAGTP20_DynSetup" BO_ 1425 0;
BA_ "VAGTP20_DynConnection" BO_ 1425 0;
BA_ "GenMsgNoIalSupport" BO_ 1425 0;
BA_ "VAGTP20_StatConnection" BO_ 1425 0;
BA_ "NWM-Botschaft" BO_ 1425 0;
BA_ "GenMsgSendType" BO_ 917 7;
BA_ "xVWTP_Setup" BO_ 917 0;
BA_ "xVWTP_Channel" BO_ 917 0;
BA_ "VAGTP20_DynSetup" BO_ 917 0;
BA_ "VAGTP20_DynConnection" BO_ 917 0;
BA_ "GenMsgCycleTimeFast" BO_ 917 50;
BA_ "GenMsgNoIalSupport" BO_ 917 0;
BA_ "GenMsgNrOfRepetition" BO_ 917 5;
BA_ "VAGTP20_StatConnection" BO_ 917 0;
BA_ "NWM-Botschaft" BO_ 917 0;
BA_ "GenMsgSendType" BO_ 913 7;
BA_ "xVWTP_Setup" BO_ 913 0;
BA_ "xVWTP_Channel" BO_ 913 0;
BA_ "VAGTP20_DynSetup" BO_ 913 0;
BA_ "VAGTP20_DynConnection" BO_ 913 0;
BA_ "GenMsgCycleTimeFast" BO_ 913 20;
BA_ "GenMsgNoIalSupport" BO_ 913 0;
BA_ "GenMsgNrOfRepetition" BO_ 913 5;
BA_ "VAGTP20_StatConnection" BO_ 913 0;
BA_ "NWM-Botschaft" BO_ 913 0;
BA_ "GenMsgSendType" BO_ 657 7;
BA_ "xVWTP_Setup" BO_ 657 0;
BA_ "xVWTP_Channel" BO_ 657 0;
BA_ "VAGTP20_DynSetup" BO_ 657 0;
BA_ "VAGTP20_DynConnection" BO_ 657 0;
BA_ "GenMsgCycleTimeFast" BO_ 657 40;
BA_ "GenMsgNoIalSupport" BO_ 657 0;
BA_ "GenMsgNrOfRepetition" BO_ 657 5;
BA_ "VAGTP20_StatConnection" BO_ 657 0;
BA_ "NWM-Botschaft" BO_ 657 0;
BA_ "GenMsgCycleTime" BO_ 707 100;
BA_ "GenMsgSendType" BO_ 707 5;
BA_ "xVWTP_Setup" BO_ 707 0;
BA_ "xVWTP_Channel" BO_ 707 0;
BA_ "VAGTP20_DynSetup" BO_ 707 0;
BA_ "VAGTP20_DynConnection" BO_ 707 0;
BA_ "GenMsgNoIalSupport" BO_ 707 0;
BA_ "VAGTP20_StatConnection" BO_ 707 0;
BA_ "NWM-Botschaft" BO_ 707 0;
BA_ "GenMsgCycleTime" BO_ 1489 200;
BA_ "GenMsgSendType" BO_ 1489 5;
BA_ "xVWTP_Setup" BO_ 1489 0;
BA_ "xVWTP_Channel" BO_ 1489 0;
BA_ "VAGTP20_DynSetup" BO_ 1489 0;
BA_ "VAGTP20_DynConnection" BO_ 1489 0;
BA_ "GenMsgNoIalSupport" BO_ 1489 0;
BA_ "VAGTP20_StatConnection" BO_ 1489 0;
BA_ "NWM-Botschaft" BO_ 1489 0;
BA_ "GenMsgCycleTime" BO_ 1361 200;
BA_ "GenMsgSendType" BO_ 1361 0;
BA_ "xVWTP_Setup" BO_ 1361 0;
BA_ "xVWTP_Channel" BO_ 1361 0;
BA_ "VAGTP20_DynSetup" BO_ 1361 0;
BA_ "VAGTP20_DynConnection" BO_ 1361 0;
BA_ "GenMsgNoIalSupport" BO_ 1361 0;
BA_ "VAGTP20_StatConnection" BO_ 1361 0;
BA_ "NWM-Botschaft" BO_ 1361 0;
BA_ "GenMsgCycleTime" BO_ 1497 100;
BA_ "GenMsgSendType" BO_ 1497 5;
BA_ "xVWTP_Setup" BO_ 1497 0;
BA_ "xVWTP_Channel" BO_ 1497 0;
BA_ "VAGTP20_DynSetup" BO_ 1497 0;
BA_ "VAGTP20_DynConnection" BO_ 1497 0;
BA_ "GenMsgNoIalSupport" BO_ 1497 0;
BA_ "VAGTP20_StatConnection" BO_ 1497 0;
BA_ "NWM-Botschaft" BO_ 1497 0;
BA_ "GenMsgCycleTime" BO_ 1213 100;
BA_ "GenMsgSendType" BO_ 1213 5;
BA_ "xVWTP_Setup" BO_ 1213 0;
BA_ "xVWTP_Channel" BO_ 1213 0;
BA_ "VAGTP20_DynSetup" BO_ 1213 0;
BA_ "VAGTP20_DynConnection" BO_ 1213 0;
BA_ "GenMsgNoIalSupport" BO_ 1213 0;
BA_ "VAGTP20_StatConnection" BO_ 1213 0;
BA_ "NWM-Botschaft" BO_ 1213 0;
BA_ "GenMsgCycleTime" BO_ 1209 100;
BA_ "GenMsgSendType" BO_ 1209 5;
BA_ "xVWTP_Setup" BO_ 1209 0;
BA_ "xVWTP_Channel" BO_ 1209 0;
BA_ "VAGTP20_DynSetup" BO_ 1209 0;
BA_ "VAGTP20_DynConnection" BO_ 1209 0;
BA_ "GenMsgNoIalSupport" BO_ 1209 0;
BA_ "VAGTP20_StatConnection" BO_ 1209 0;
BA_ "NWM-Botschaft" BO_ 1209 0;
BA_ "GenMsgCycleTime" BO_ 899 100;
BA_ "GenMsgSendType" BO_ 899 5;
BA_ "xVWTP_Setup" BO_ 899 0;
BA_ "xVWTP_Channel" BO_ 899 0;
BA_ "VAGTP20_DynSetup" BO_ 899 0;
BA_ "VAGTP20_DynConnection" BO_ 899 0;
BA_ "GenMsgNoIalSupport" BO_ 899 0;
BA_ "VAGTP20_StatConnection" BO_ 899 0;
BA_ "NWM-Botschaft" BO_ 899 0;
BA_ "GenMsgCycleTime" BO_ 897 100;
BA_ "GenMsgSendType" BO_ 897 5;
BA_ "xVWTP_Setup" BO_ 897 0;
BA_ "xVWTP_Channel" BO_ 897 0;
BA_ "VAGTP20_DynSetup" BO_ 897 0;
BA_ "VAGTP20_DynConnection" BO_ 897 0;
BA_ "GenMsgNoIalSupport" BO_ 897 0;
BA_ "VAGTP20_StatConnection" BO_ 897 0;
BA_ "NWM-Botschaft" BO_ 897 0;
BA_ "GenMsgSendType" BO_ 385 7;
BA_ "xVWTP_Setup" BO_ 385 0;
BA_ "xVWTP_Channel" BO_ 385 0;
BA_ "VAGTP20_DynSetup" BO_ 385 0;
BA_ "VAGTP20_DynConnection" BO_ 385 0;
BA_ "GenMsgCycleTimeFast" BO_ 385 20;
BA_ "GenMsgNoIalSupport" BO_ 385 0;
BA_ "GenMsgNrOfRepetition" BO_ 385 5;
BA_ "VAGTP20_StatConnection" BO_ 385 0;
BA_ "NWM-Botschaft" BO_ 385 0;
BA_ "GenMsgCycleTime" BO_ 949 100;
BA_ "GenMsgSendType" BO_ 949 5;
BA_ "xVWTP_Setup" BO_ 949 0;
BA_ "xVWTP_Channel" BO_ 949 0;
BA_ "VAGTP20_DynSetup" BO_ 949 0;
BA_ "VAGTP20_DynConnection" BO_ 949 0;
BA_ "GenMsgNoIalSupport" BO_ 949 0;
BA_ "VAGTP20_StatConnection" BO_ 949 0;
BA_ "NWM-Botschaft" BO_ 949 0;
BA_ "GenMsgSendType" BO_ 562 2;
BA_ "xVWTP_Setup" BO_ 562 0;
BA_ "xVWTP_Channel" BO_ 562 0;
BA_ "VAGTP20_DynSetup" BO_ 562 1;
BA_ "VAGTP20_DynConnection" BO_ 562 0;
BA_ "GenMsgCycleTimeFast" BO_ 562 100;
BA_ "GenMsgNoIalSupport" BO_ 562 0;
BA_ "VAGTP20_StatConnection" BO_ 562 0;
BA_ "NWM-Botschaft" BO_ 562 0;
BA_ "GenMsgSendType" BO_ 560 2;
BA_ "xVWTP_Setup" BO_ 560 0;
BA_ "xVWTP_Channel" BO_ 560 0;
BA_ "VAGTP20_DynSetup" BO_ 560 1;
BA_ "VAGTP20_DynConnection" BO_ 560 0;
BA_ "GenMsgCycleTimeFast" BO_ 560 100;
BA_ "GenMsgNoIalSupport" BO_ 560 0;
BA_ "VAGTP20_StatConnection" BO_ 560 0;
BA_ "NWM-Botschaft" BO_ 560 0;
BA_ "GenMsgSendType" BO_ 549 2;
BA_ "xVWTP_Setup" BO_ 549 0;
BA_ "xVWTP_Channel" BO_ 549 0;
BA_ "VAGTP20_DynSetup" BO_ 549 1;
BA_ "VAGTP20_DynConnection" BO_ 549 0;
BA_ "GenMsgCycleTimeFast" BO_ 549 100;
BA_ "GenMsgNoIalSupport" BO_ 549 0;
BA_ "VAGTP20_StatConnection" BO_ 549 0;
BA_ "NWM-Botschaft" BO_ 549 0;
BA_ "GenMsgSendType" BO_ 548 2;
BA_ "xVWTP_Setup" BO_ 548 0;
BA_ "xVWTP_Channel" BO_ 548 0;
BA_ "VAGTP20_DynSetup" BO_ 548 1;
BA_ "VAGTP20_DynConnection" BO_ 548 0;
BA_ "GenMsgCycleTimeFast" BO_ 548 100;
BA_ "GenMsgNoIalSupport" BO_ 548 0;
BA_ "VAGTP20_StatConnection" BO_ 548 0;
BA_ "NWM-Botschaft" BO_ 548 0;
BA_ "GenMsgSendType" BO_ 546 2;
BA_ "xVWTP_Setup" BO_ 546 0;
BA_ "xVWTP_Channel" BO_ 546 0;
BA_ "VAGTP20_DynSetup" BO_ 546 1;
BA_ "VAGTP20_DynConnection" BO_ 546 0;
BA_ "GenMsgCycleTimeFast" BO_ 546 100;
BA_ "GenMsgNoIalSupport" BO_ 546 0;
BA_ "VAGTP20_StatConnection" BO_ 546 0;
BA_ "NWM-Botschaft" BO_ 546 0;
BA_ "GenMsgSendType" BO_ 547 2;
BA_ "xVWTP_Setup" BO_ 547 0;
BA_ "xVWTP_Channel" BO_ 547 0;
BA_ "VAGTP20_DynSetup" BO_ 547 1;
BA_ "VAGTP20_DynConnection" BO_ 547 0;
BA_ "GenMsgCycleTimeFast" BO_ 547 100;
BA_ "GenMsgNoIalSupport" BO_ 547 0;
BA_ "VAGTP20_StatConnection" BO_ 547 0;
BA_ "NWM-Botschaft" BO_ 547 0;
BA_ "GenMsgSendType" BO_ 512 2;
BA_ "xVWTP_Setup" BO_ 512 1;
BA_ "xVWTP_Channel" BO_ 512 0;
BA_ "VAGTP20_DynSetup" BO_ 512 1;
BA_ "VAGTP20_DynConnection" BO_ 512 0;
BA_ "GenMsgCycleTimeFast" BO_ 512 100;
BA_ "GenMsgNoIalSupport" BO_ 512 0;
BA_ "VAGTP20_StatConnection" BO_ 512 0;
BA_ "NWM-Botschaft" BO_ 512 0;
BA_ "GenMsgSendType" BO_ 554 2;
BA_ "xVWTP_Setup" BO_ 554 0;
BA_ "xVWTP_Channel" BO_ 554 0;
BA_ "VAGTP20_DynSetup" BO_ 554 1;
BA_ "VAGTP20_DynConnection" BO_ 554 0;
BA_ "GenMsgCycleTimeFast" BO_ 554 100;
BA_ "GenMsgNoIalSupport" BO_ 554 0;
BA_ "VAGTP20_StatConnection" BO_ 554 0;
BA_ "NWM-Botschaft" BO_ 554 0;
BA_ "GenMsgSendType" BO_ 559 2;
BA_ "xVWTP_Setup" BO_ 559 0;
BA_ "xVWTP_Channel" BO_ 559 0;
BA_ "VAGTP20_DynSetup" BO_ 559 1;
BA_ "VAGTP20_DynConnection" BO_ 559 0;
BA_ "GenMsgCycleTimeFast" BO_ 559 100;
BA_ "GenMsgNoIalSupport" BO_ 559 0;
BA_ "VAGTP20_StatConnection" BO_ 559 0;
BA_ "NWM-Botschaft" BO_ 559 0;
BA_ "GenMsgSendType" BO_ 553 2;
BA_ "xVWTP_Setup" BO_ 553 0;
BA_ "xVWTP_Channel" BO_ 553 0;
BA_ "VAGTP20_DynSetup" BO_ 553 1;
BA_ "VAGTP20_DynConnection" BO_ 553 0;
BA_ "GenMsgCycleTimeFast" BO_ 553 100;
BA_ "GenMsgNoIalSupport" BO_ 553 0;
BA_ "VAGTP20_StatConnection" BO_ 553 0;
BA_ "NWM-Botschaft" BO_ 553 0;
BA_ "GenMsgSendType" BO_ 558 2;
BA_ "xVWTP_Setup" BO_ 558 0;
BA_ "xVWTP_Channel" BO_ 558 0;
BA_ "VAGTP20_DynSetup" BO_ 558 1;
BA_ "VAGTP20_DynConnection" BO_ 558 0;
BA_ "GenMsgCycleTimeFast" BO_ 558 100;
BA_ "GenMsgNoIalSupport" BO_ 558 0;
BA_ "VAGTP20_StatConnection" BO_ 558 0;
BA_ "NWM-Botschaft" BO_ 558 0;
BA_ "GenMsgSendType" BO_ 570 2;
BA_ "xVWTP_Setup" BO_ 570 0;
BA_ "xVWTP_Channel" BO_ 570 0;
BA_ "VAGTP20_DynSetup" BO_ 570 1;
BA_ "VAGTP20_DynConnection" BO_ 570 0;
BA_ "GenMsgCycleTimeFast" BO_ 570 100;
BA_ "GenMsgNoIalSupport" BO_ 570 0;
BA_ "VAGTP20_StatConnection" BO_ 570 0;
BA_ "NWM-Botschaft" BO_ 570 0;
BA_ "GenMsgSendType" BO_ 565 2;
BA_ "xVWTP_Setup" BO_ 565 0;
BA_ "xVWTP_Channel" BO_ 565 0;
BA_ "VAGTP20_DynSetup" BO_ 565 1;
BA_ "VAGTP20_DynConnection" BO_ 565 0;
BA_ "GenMsgCycleTimeFast" BO_ 565 100;
BA_ "GenMsgNoIalSupport" BO_ 565 0;
BA_ "VAGTP20_StatConnection" BO_ 565 0;
BA_ "NWM-Botschaft" BO_ 565 0;
BA_ "GenMsgSendType" BO_ 550 2;
BA_ "xVWTP_Setup" BO_ 550 0;
BA_ "xVWTP_Channel" BO_ 550 0;
BA_ "VAGTP20_DynSetup" BO_ 550 1;
BA_ "VAGTP20_DynConnection" BO_ 550 0;
BA_ "GenMsgCycleTimeFast" BO_ 550 100;
BA_ "GenMsgNoIalSupport" BO_ 550 0;
BA_ "VAGTP20_StatConnection" BO_ 550 0;
BA_ "NWM-Botschaft" BO_ 550 0;
BA_ "GenMsgSendType" BO_ 545 2;
BA_ "xVWTP_Setup" BO_ 545 0;
BA_ "xVWTP_Channel" BO_ 545 0;
BA_ "VAGTP20_DynSetup" BO_ 545 1;
BA_ "VAGTP20_DynConnection" BO_ 545 0;
BA_ "GenMsgCycleTimeFast" BO_ 545 100;
BA_ "GenMsgNoIalSupport" BO_ 545 0;
BA_ "VAGTP20_StatConnection" BO_ 545 0;
BA_ "NWM-Botschaft" BO_ 545 0;
BA_ "GenMsgSendType" BO_ 543 2;
BA_ "xVWTP_Setup" BO_ 543 1;
BA_ "xVWTP_Channel" BO_ 543 0;
BA_ "VAGTP20_DynSetup" BO_ 543 1;
BA_ "VAGTP20_DynConnection" BO_ 543 0;
BA_ "GenMsgCycleTimeFast" BO_ 543 100;
BA_ "GenMsgNoIalSupport" BO_ 543 0;
BA_ "VAGTP20_StatConnection" BO_ 543 0;
BA_ "NWM-Botschaft" BO_ 543 0;
BA_ "GenMsgSendType" BO_ 556 2;
BA_ "xVWTP_Setup" BO_ 556 0;
BA_ "xVWTP_Channel" BO_ 556 0;
BA_ "VAGTP20_DynSetup" BO_ 556 1;
BA_ "VAGTP20_DynConnection" BO_ 556 0;
BA_ "GenMsgCycleTimeFast" BO_ 556 100;
BA_ "GenMsgNoIalSupport" BO_ 556 0;
BA_ "VAGTP20_StatConnection" BO_ 556 0;
BA_ "NWM-Botschaft" BO_ 556 0;
BA_ "GenMsgSendType" BO_ 544 2;
BA_ "xVWTP_Setup" BO_ 544 0;
BA_ "xVWTP_Channel" BO_ 544 0;
BA_ "VAGTP20_DynSetup" BO_ 544 1;
BA_ "VAGTP20_DynConnection" BO_ 544 0;
BA_ "GenMsgCycleTimeFast" BO_ 544 100;
BA_ "GenMsgNoIalSupport" BO_ 544 0;
BA_ "VAGTP20_StatConnection" BO_ 544 0;
BA_ "NWM-Botschaft" BO_ 544 0;
BA_ "GenMsgSendType" BO_ 557 2;
BA_ "xVWTP_Setup" BO_ 557 0;
BA_ "xVWTP_Channel" BO_ 557 0;
BA_ "VAGTP20_DynSetup" BO_ 557 1;
BA_ "VAGTP20_DynConnection" BO_ 557 0;
BA_ "GenMsgCycleTimeFast" BO_ 557 100;
BA_ "GenMsgNoIalSupport" BO_ 557 0;
BA_ "VAGTP20_StatConnection" BO_ 557 0;
BA_ "NWM-Botschaft" BO_ 557 0;
BA_ "GenMsgSendType" BO_ 579 2;
BA_ "xVWTP_Setup" BO_ 579 0;
BA_ "xVWTP_Channel" BO_ 579 0;
BA_ "VAGTP20_DynSetup" BO_ 579 1;
BA_ "VAGTP20_DynConnection" BO_ 579 0;
BA_ "GenMsgCycleTimeFast" BO_ 579 100;
BA_ "GenMsgNoIalSupport" BO_ 579 0;
BA_ "VAGTP20_StatConnection" BO_ 579 0;
BA_ "NWM-Botschaft" BO_ 579 0;
BA_ "GenMsgSendType" BO_ 811 2;
BA_ "xVWTP_Setup" BO_ 811 0;
BA_ "xVWTP_Channel" BO_ 811 1;
BA_ "VAGTP20_DynSetup" BO_ 811 0;
BA_ "VAGTP20_DynConnection" BO_ 811 1;
BA_ "GenMsgCycleTimeFast" BO_ 811 100;
BA_ "GenMsgNoIalSupport" BO_ 811 0;
BA_ "VAGTP20_StatConnection" BO_ 811 0;
BA_ "NWM-Botschaft" BO_ 811 0;
BA_ "GenMsgSendType" BO_ 810 2;
BA_ "xVWTP_Setup" BO_ 810 0;
BA_ "xVWTP_Channel" BO_ 810 1;
BA_ "VAGTP20_DynSetup" BO_ 810 0;
BA_ "VAGTP20_DynConnection" BO_ 810 1;
BA_ "GenMsgCycleTimeFast" BO_ 810 100;
BA_ "GenMsgNoIalSupport" BO_ 810 0;
BA_ "VAGTP20_StatConnection" BO_ 810 0;
BA_ "NWM-Botschaft" BO_ 810 0;
BA_ "GenMsgSendType" BO_ 791 2;
BA_ "xVWTP_Setup" BO_ 791 0;
BA_ "xVWTP_Channel" BO_ 791 1;
BA_ "VAGTP20_DynSetup" BO_ 791 0;
BA_ "VAGTP20_DynConnection" BO_ 791 1;
BA_ "GenMsgCycleTimeFast" BO_ 791 100;
BA_ "GenMsgNoIalSupport" BO_ 791 0;
BA_ "VAGTP20_StatConnection" BO_ 791 0;
BA_ "NWM-Botschaft" BO_ 791 0;
BA_ "GenMsgSendType" BO_ 790 2;
BA_ "xVWTP_Setup" BO_ 790 0;
BA_ "xVWTP_Channel" BO_ 790 1;
BA_ "VAGTP20_DynSetup" BO_ 790 0;
BA_ "VAGTP20_DynConnection" BO_ 790 1;
BA_ "GenMsgCycleTimeFast" BO_ 790 100;
BA_ "GenMsgNoIalSupport" BO_ 790 0;
BA_ "VAGTP20_StatConnection" BO_ 790 0;
BA_ "NWM-Botschaft" BO_ 790 0;
BA_ "GenMsgSendType" BO_ 789 2;
BA_ "xVWTP_Setup" BO_ 789 0;
BA_ "xVWTP_Channel" BO_ 789 1;
BA_ "VAGTP20_DynSetup" BO_ 789 0;
BA_ "VAGTP20_DynConnection" BO_ 789 1;
BA_ "GenMsgCycleTimeFast" BO_ 789 100;
BA_ "GenMsgNoIalSupport" BO_ 789 0;
BA_ "VAGTP20_StatConnection" BO_ 789 0;
BA_ "NWM-Botschaft" BO_ 789 0;
BA_ "GenMsgSendType" BO_ 788 2;
BA_ "xVWTP_Setup" BO_ 788 0;
BA_ "xVWTP_Channel" BO_ 788 1;
BA_ "VAGTP20_DynSetup" BO_ 788 0;
BA_ "VAGTP20_DynConnection" BO_ 788 1;
BA_ "GenMsgCycleTimeFast" BO_ 788 100;
BA_ "GenMsgNoIalSupport" BO_ 788 0;
BA_ "VAGTP20_StatConnection" BO_ 788 0;
BA_ "NWM-Botschaft" BO_ 788 0;
BA_ "GenMsgSendType" BO_ 785 2;
BA_ "xVWTP_Setup" BO_ 785 0;
BA_ "xVWTP_Channel" BO_ 785 1;
BA_ "VAGTP20_DynSetup" BO_ 785 0;
BA_ "VAGTP20_DynConnection" BO_ 785 1;
BA_ "GenMsgCycleTimeFast" BO_ 785 100;
BA_ "GenMsgNoIalSupport" BO_ 785 0;
BA_ "VAGTP20_StatConnection" BO_ 785 0;
BA_ "NWM-Botschaft" BO_ 785 0;
BA_ "GenMsgSendType" BO_ 784 2;
BA_ "xVWTP_Setup" BO_ 784 0;
BA_ "xVWTP_Channel" BO_ 784 1;
BA_ "VAGTP20_DynSetup" BO_ 784 0;
BA_ "VAGTP20_DynConnection" BO_ 784 1;
BA_ "GenMsgCycleTimeFast" BO_ 784 100;
BA_ "GenMsgNoIalSupport" BO_ 784 0;
BA_ "VAGTP20_StatConnection" BO_ 784 0;
BA_ "NWM-Botschaft" BO_ 784 0;
BA_ "GenMsgSendType" BO_ 787 2;
BA_ "xVWTP_Setup" BO_ 787 0;
BA_ "xVWTP_Channel" BO_ 787 1;
BA_ "VAGTP20_DynSetup" BO_ 787 0;
BA_ "VAGTP20_DynConnection" BO_ 787 1;
BA_ "GenMsgCycleTimeFast" BO_ 787 100;
BA_ "GenMsgNoIalSupport" BO_ 787 0;
BA_ "VAGTP20_StatConnection" BO_ 787 0;
BA_ "NWM-Botschaft" BO_ 787 0;
BA_ "GenMsgSendType" BO_ 786 2;
BA_ "xVWTP_Setup" BO_ 786 0;
BA_ "xVWTP_Channel" BO_ 786 1;
BA_ "VAGTP20_DynSetup" BO_ 786 0;
BA_ "VAGTP20_DynConnection" BO_ 786 1;
BA_ "GenMsgCycleTimeFast" BO_ 786 100;
BA_ "GenMsgNoIalSupport" BO_ 786 0;
BA_ "VAGTP20_StatConnection" BO_ 786 0;
BA_ "NWM-Botschaft" BO_ 786 0;
BA_ "GenMsgSendType" BO_ 765 2;
BA_ "xVWTP_Setup" BO_ 765 1;
BA_ "xVWTP_Channel" BO_ 765 0;
BA_ "VAGTP20_DynSetup" BO_ 765 0;
BA_ "VAGTP20_DynConnection" BO_ 765 1;
BA_ "GenMsgCycleTimeFast" BO_ 765 100;
BA_ "GenMsgNoIalSupport" BO_ 765 0;
BA_ "VAGTP20_StatConnection" BO_ 765 0;
BA_ "NWM-Botschaft" BO_ 765 0;
BA_ "GenMsgSendType" BO_ 764 2;
BA_ "xVWTP_Setup" BO_ 764 1;
BA_ "xVWTP_Channel" BO_ 764 0;
BA_ "VAGTP20_DynSetup" BO_ 764 0;
BA_ "VAGTP20_DynConnection" BO_ 764 1;
BA_ "GenMsgCycleTimeFast" BO_ 764 100;
BA_ "GenMsgNoIalSupport" BO_ 764 0;
BA_ "VAGTP20_StatConnection" BO_ 764 0;
BA_ "NWM-Botschaft" BO_ 764 0;
BA_ "GenMsgSendType" BO_ 805 2;
BA_ "xVWTP_Setup" BO_ 805 0;
BA_ "xVWTP_Channel" BO_ 805 1;
BA_ "VAGTP20_DynSetup" BO_ 805 0;
BA_ "VAGTP20_DynConnection" BO_ 805 1;
BA_ "GenMsgCycleTimeFast" BO_ 805 100;
BA_ "GenMsgNoIalSupport" BO_ 805 0;
BA_ "VAGTP20_StatConnection" BO_ 805 0;
BA_ "NWM-Botschaft" BO_ 805 0;
BA_ "GenMsgSendType" BO_ 804 2;
BA_ "xVWTP_Setup" BO_ 804 0;
BA_ "xVWTP_Channel" BO_ 804 1;
BA_ "VAGTP20_DynSetup" BO_ 804 0;
BA_ "VAGTP20_DynConnection" BO_ 804 1;
BA_ "GenMsgCycleTimeFast" BO_ 804 100;
BA_ "GenMsgNoIalSupport" BO_ 804 0;
BA_ "VAGTP20_StatConnection" BO_ 804 0;
BA_ "NWM-Botschaft" BO_ 804 0;
BA_ "GenMsgSendType" BO_ 803 2;
BA_ "xVWTP_Setup" BO_ 803 0;
BA_ "xVWTP_Channel" BO_ 803 1;
BA_ "VAGTP20_DynSetup" BO_ 803 0;
BA_ "VAGTP20_DynConnection" BO_ 803 1;
BA_ "GenMsgCycleTimeFast" BO_ 803 100;
BA_ "GenMsgNoIalSupport" BO_ 803 0;
BA_ "VAGTP20_StatConnection" BO_ 803 0;
BA_ "NWM-Botschaft" BO_ 803 0;
BA_ "GenMsgSendType" BO_ 802 2;
BA_ "xVWTP_Setup" BO_ 802 0;
BA_ "xVWTP_Channel" BO_ 802 1;
BA_ "VAGTP20_DynSetup" BO_ 802 0;
BA_ "VAGTP20_DynConnection" BO_ 802 1;
BA_ "GenMsgCycleTimeFast" BO_ 802 100;
BA_ "GenMsgNoIalSupport" BO_ 802 0;
BA_ "VAGTP20_StatConnection" BO_ 802 0;
BA_ "NWM-Botschaft" BO_ 802 0;
BA_ "GenMsgSendType" BO_ 827 2;
BA_ "xVWTP_Setup" BO_ 827 0;
BA_ "xVWTP_Channel" BO_ 827 1;
BA_ "VAGTP20_DynSetup" BO_ 827 0;
BA_ "VAGTP20_DynConnection" BO_ 827 1;
BA_ "GenMsgCycleTimeFast" BO_ 827 100;
BA_ "GenMsgNoIalSupport" BO_ 827 0;
BA_ "VAGTP20_StatConnection" BO_ 827 0;
BA_ "NWM-Botschaft" BO_ 827 0;
BA_ "GenMsgSendType" BO_ 826 2;
BA_ "xVWTP_Setup" BO_ 826 0;
BA_ "xVWTP_Channel" BO_ 826 1;
BA_ "VAGTP20_DynSetup" BO_ 826 0;
BA_ "VAGTP20_DynConnection" BO_ 826 1;
BA_ "GenMsgCycleTimeFast" BO_ 826 100;
BA_ "GenMsgNoIalSupport" BO_ 826 0;
BA_ "VAGTP20_StatConnection" BO_ 826 0;
BA_ "NWM-Botschaft" BO_ 826 0;
BA_ "GenMsgSendType" BO_ 767 2;
BA_ "xVWTP_Setup" BO_ 767 1;
BA_ "xVWTP_Channel" BO_ 767 0;
BA_ "VAGTP20_DynSetup" BO_ 767 0;
BA_ "VAGTP20_DynConnection" BO_ 767 1;
BA_ "GenMsgCycleTimeFast" BO_ 767 100;
BA_ "GenMsgNoIalSupport" BO_ 767 0;
BA_ "VAGTP20_StatConnection" BO_ 767 0;
BA_ "NWM-Botschaft" BO_ 767 0;
BA_ "GenMsgSendType" BO_ 766 2;
BA_ "xVWTP_Setup" BO_ 766 1;
BA_ "xVWTP_Channel" BO_ 766 0;
BA_ "VAGTP20_DynSetup" BO_ 766 0;
BA_ "VAGTP20_DynConnection" BO_ 766 1;
BA_ "GenMsgCycleTimeFast" BO_ 766 100;
BA_ "GenMsgNoIalSupport" BO_ 766 0;
BA_ "VAGTP20_StatConnection" BO_ 766 0;
BA_ "NWM-Botschaft" BO_ 766 0;
BA_ "GenMsgSendType" BO_ 793 2;
BA_ "xVWTP_Setup" BO_ 793 0;
BA_ "xVWTP_Channel" BO_ 793 1;
BA_ "VAGTP20_DynSetup" BO_ 793 0;
BA_ "VAGTP20_DynConnection" BO_ 793 1;
BA_ "GenMsgCycleTimeFast" BO_ 793 100;
BA_ "GenMsgNoIalSupport" BO_ 793 0;
BA_ "VAGTP20_StatConnection" BO_ 793 0;
BA_ "NWM-Botschaft" BO_ 793 0;
BA_ "GenMsgSendType" BO_ 792 2;
BA_ "xVWTP_Setup" BO_ 792 0;
BA_ "xVWTP_Channel" BO_ 792 1;
BA_ "VAGTP20_DynSetup" BO_ 792 0;
BA_ "VAGTP20_DynConnection" BO_ 792 1;
BA_ "GenMsgCycleTimeFast" BO_ 792 100;
BA_ "GenMsgNoIalSupport" BO_ 792 0;
BA_ "VAGTP20_StatConnection" BO_ 792 0;
BA_ "NWM-Botschaft" BO_ 792 0;
BA_ "GenMsgSendType" BO_ 795 2;
BA_ "xVWTP_Setup" BO_ 795 0;
BA_ "xVWTP_Channel" BO_ 795 1;
BA_ "VAGTP20_DynSetup" BO_ 795 0;
BA_ "VAGTP20_DynConnection" BO_ 795 1;
BA_ "GenMsgCycleTimeFast" BO_ 795 100;
BA_ "GenMsgNoIalSupport" BO_ 795 0;
BA_ "VAGTP20_StatConnection" BO_ 795 0;
BA_ "NWM-Botschaft" BO_ 795 0;
BA_ "GenMsgSendType" BO_ 794 2;
BA_ "xVWTP_Setup" BO_ 794 0;
BA_ "xVWTP_Channel" BO_ 794 1;
BA_ "VAGTP20_DynSetup" BO_ 794 0;
BA_ "VAGTP20_DynConnection" BO_ 794 1;
BA_ "GenMsgCycleTimeFast" BO_ 794 100;
BA_ "GenMsgNoIalSupport" BO_ 794 0;
BA_ "VAGTP20_StatConnection" BO_ 794 0;
BA_ "NWM-Botschaft" BO_ 794 0;
BA_ "GenMsgSendType" BO_ 809 2;
BA_ "xVWTP_Setup" BO_ 809 0;
BA_ "xVWTP_Channel" BO_ 809 1;
BA_ "VAGTP20_DynSetup" BO_ 809 0;
BA_ "VAGTP20_DynConnection" BO_ 809 1;
BA_ "GenMsgCycleTimeFast" BO_ 809 100;
BA_ "GenMsgNoIalSupport" BO_ 809 0;
BA_ "VAGTP20_StatConnection" BO_ 809 0;
BA_ "NWM-Botschaft" BO_ 809 0;
BA_ "GenMsgSendType" BO_ 808 2;
BA_ "xVWTP_Setup" BO_ 808 0;
BA_ "xVWTP_Channel" BO_ 808 1;
BA_ "VAGTP20_DynSetup" BO_ 808 0;
BA_ "VAGTP20_DynConnection" BO_ 808 1;
BA_ "GenMsgCycleTimeFast" BO_ 808 100;
BA_ "GenMsgNoIalSupport" BO_ 808 0;
BA_ "VAGTP20_StatConnection" BO_ 808 0;
BA_ "NWM-Botschaft" BO_ 808 0;
BA_ "GenMsgSendType" BO_ 815 2;
BA_ "xVWTP_Setup" BO_ 815 0;
BA_ "xVWTP_Channel" BO_ 815 1;
BA_ "VAGTP20_DynSetup" BO_ 815 0;
BA_ "VAGTP20_DynConnection" BO_ 815 1;
BA_ "GenMsgCycleTimeFast" BO_ 815 100;
BA_ "GenMsgNoIalSupport" BO_ 815 0;
BA_ "VAGTP20_StatConnection" BO_ 815 0;
BA_ "NWM-Botschaft" BO_ 815 0;
BA_ "GenMsgSendType" BO_ 814 2;
BA_ "xVWTP_Setup" BO_ 814 0;
BA_ "xVWTP_Channel" BO_ 814 1;
BA_ "VAGTP20_DynSetup" BO_ 814 0;
BA_ "VAGTP20_DynConnection" BO_ 814 1;
BA_ "GenMsgCycleTimeFast" BO_ 814 100;
BA_ "GenMsgNoIalSupport" BO_ 814 0;
BA_ "VAGTP20_StatConnection" BO_ 814 0;
BA_ "NWM-Botschaft" BO_ 814 0;
BA_ "GenMsgSendType" BO_ 1235 2;
BA_ "xVWTP_Setup" BO_ 1235 1;
BA_ "xVWTP_Channel" BO_ 1235 0;
BA_ "VAGTP20_DynSetup" BO_ 1235 0;
BA_ "VAGTP20_DynConnection" BO_ 1235 1;
BA_ "GenMsgCycleTimeFast" BO_ 1235 100;
BA_ "GenMsgNoIalSupport" BO_ 1235 0;
BA_ "VAGTP20_StatConnection" BO_ 1235 0;
BA_ "NWM-Botschaft" BO_ 1235 0;
BA_ "GenMsgSendType" BO_ 1234 2;
BA_ "xVWTP_Setup" BO_ 1234 1;
BA_ "xVWTP_Channel" BO_ 1234 0;
BA_ "VAGTP20_DynSetup" BO_ 1234 0;
BA_ "VAGTP20_DynConnection" BO_ 1234 1;
BA_ "GenMsgCycleTimeFast" BO_ 1234 100;
BA_ "GenMsgNoIalSupport" BO_ 1234 0;
BA_ "VAGTP20_StatConnection" BO_ 1234 0;
BA_ "NWM-Botschaft" BO_ 1234 0;
BA_ "GenMsgSendType" BO_ 1233 2;
BA_ "xVWTP_Setup" BO_ 1233 1;
BA_ "xVWTP_Channel" BO_ 1233 0;
BA_ "VAGTP20_DynSetup" BO_ 1233 0;
BA_ "VAGTP20_DynConnection" BO_ 1233 1;
BA_ "GenMsgCycleTimeFast" BO_ 1233 100;
BA_ "GenMsgNoIalSupport" BO_ 1233 0;
BA_ "VAGTP20_StatConnection" BO_ 1233 0;
BA_ "NWM-Botschaft" BO_ 1233 0;
BA_ "GenMsgSendType" BO_ 1232 2;
BA_ "xVWTP_Setup" BO_ 1232 1;
BA_ "xVWTP_Channel" BO_ 1232 0;
BA_ "VAGTP20_DynSetup" BO_ 1232 0;
BA_ "VAGTP20_DynConnection" BO_ 1232 1;
BA_ "GenMsgCycleTimeFast" BO_ 1232 100;
BA_ "GenMsgNoIalSupport" BO_ 1232 0;
BA_ "VAGTP20_StatConnection" BO_ 1232 0;
BA_ "NWM-Botschaft" BO_ 1232 0;
BA_ "GenMsgSendType" BO_ 829 2;
BA_ "xVWTP_Setup" BO_ 829 0;
BA_ "xVWTP_Channel" BO_ 829 1;
BA_ "VAGTP20_DynSetup" BO_ 829 0;
BA_ "VAGTP20_DynConnection" BO_ 829 1;
BA_ "GenMsgCycleTimeFast" BO_ 829 100;
BA_ "GenMsgNoIalSupport" BO_ 829 0;
BA_ "VAGTP20_StatConnection" BO_ 829 0;
BA_ "NWM-Botschaft" BO_ 829 0;
BA_ "GenMsgSendType" BO_ 828 2;
BA_ "xVWTP_Setup" BO_ 828 0;
BA_ "xVWTP_Channel" BO_ 828 1;
BA_ "VAGTP20_DynSetup" BO_ 828 0;
BA_ "VAGTP20_DynConnection" BO_ 828 1;
BA_ "GenMsgCycleTimeFast" BO_ 828 100;
BA_ "GenMsgNoIalSupport" BO_ 828 0;
BA_ "VAGTP20_StatConnection" BO_ 828 0;
BA_ "NWM-Botschaft" BO_ 828 0;
BA_ "GenMsgSendType" BO_ 825 2;
BA_ "xVWTP_Setup" BO_ 825 0;
BA_ "xVWTP_Channel" BO_ 825 1;
BA_ "VAGTP20_DynSetup" BO_ 825 0;
BA_ "VAGTP20_DynConnection" BO_ 825 1;
BA_ "GenMsgCycleTimeFast" BO_ 825 100;
BA_ "GenMsgNoIalSupport" BO_ 825 0;
BA_ "VAGTP20_StatConnection" BO_ 825 0;
BA_ "NWM-Botschaft" BO_ 825 0;
BA_ "GenMsgSendType" BO_ 824 2;
BA_ "xVWTP_Setup" BO_ 824 0;
BA_ "xVWTP_Channel" BO_ 824 1;
BA_ "VAGTP20_DynSetup" BO_ 824 0;
BA_ "VAGTP20_DynConnection" BO_ 824 1;
BA_ "GenMsgCycleTimeFast" BO_ 824 100;
BA_ "GenMsgNoIalSupport" BO_ 824 0;
BA_ "VAGTP20_StatConnection" BO_ 824 0;
BA_ "NWM-Botschaft" BO_ 824 0;
BA_ "GenMsgSendType" BO_ 819 2;
BA_ "xVWTP_Setup" BO_ 819 0;
BA_ "xVWTP_Channel" BO_ 819 1;
BA_ "VAGTP20_DynSetup" BO_ 819 0;
BA_ "VAGTP20_DynConnection" BO_ 819 1;
BA_ "GenMsgCycleTimeFast" BO_ 819 100;
BA_ "GenMsgNoIalSupport" BO_ 819 0;
BA_ "VAGTP20_StatConnection" BO_ 819 0;
BA_ "NWM-Botschaft" BO_ 819 0;
BA_ "GenMsgSendType" BO_ 818 2;
BA_ "xVWTP_Setup" BO_ 818 0;
BA_ "xVWTP_Channel" BO_ 818 1;
BA_ "VAGTP20_DynSetup" BO_ 818 0;
BA_ "VAGTP20_DynConnection" BO_ 818 1;
BA_ "GenMsgCycleTimeFast" BO_ 818 100;
BA_ "GenMsgNoIalSupport" BO_ 818 0;
BA_ "VAGTP20_StatConnection" BO_ 818 0;
BA_ "NWM-Botschaft" BO_ 818 0;
BA_ "GenMsgSendType" BO_ 823 2;
BA_ "xVWTP_Setup" BO_ 823 0;
BA_ "xVWTP_Channel" BO_ 823 1;
BA_ "VAGTP20_DynSetup" BO_ 823 0;
BA_ "VAGTP20_DynConnection" BO_ 823 1;
BA_ "GenMsgCycleTimeFast" BO_ 823 100;
BA_ "GenMsgNoIalSupport" BO_ 823 0;
BA_ "VAGTP20_StatConnection" BO_ 823 0;
BA_ "NWM-Botschaft" BO_ 823 0;
BA_ "GenMsgSendType" BO_ 822 2;
BA_ "xVWTP_Setup" BO_ 822 0;
BA_ "xVWTP_Channel" BO_ 822 1;
BA_ "VAGTP20_DynSetup" BO_ 822 0;
BA_ "VAGTP20_DynConnection" BO_ 822 1;
BA_ "GenMsgCycleTimeFast" BO_ 822 100;
BA_ "GenMsgNoIalSupport" BO_ 822 0;
BA_ "VAGTP20_StatConnection" BO_ 822 0;
BA_ "NWM-Botschaft" BO_ 822 0;
BA_ "GenMsgSendType" BO_ 1449 2;
BA_ "xVWTP_Setup" BO_ 1449 0;
BA_ "xVWTP_Channel" BO_ 1449 0;
BA_ "VAGTP20_DynSetup" BO_ 1449 0;
BA_ "VAGTP20_DynConnection" BO_ 1449 0;
BA_ "GenMsgCycleTimeFast" BO_ 1449 100;
BA_ "GenMsgNoIalSupport" BO_ 1449 0;
BA_ "GenMsgNrOfRepetition" BO_ 1449 5;
BA_ "VAGTP20_StatConnection" BO_ 1449 0;
BA_ "NWM-Botschaft" BO_ 1449 0;
BA_ "GenMsgCycleTime" BO_ 1637 1000;
BA_ "GenMsgSendType" BO_ 1637 5;
BA_ "xVWTP_Setup" BO_ 1637 0;
BA_ "xVWTP_Channel" BO_ 1637 0;
BA_ "VAGTP20_DynSetup" BO_ 1637 0;
BA_ "VAGTP20_DynConnection" BO_ 1637 0;
BA_ "GenMsgNoIalSupport" BO_ 1637 0;
BA_ "VAGTP20_StatConnection" BO_ 1637 0;
BA_ "NWM-Botschaft" BO_ 1637 0;
BA_ "GenMsgCycleTime" BO_ 1617 500;
BA_ "GenMsgSendType" BO_ 1617 0;
BA_ "xVWTP_Setup" BO_ 1617 0;
BA_ "xVWTP_Channel" BO_ 1617 0;
BA_ "VAGTP20_DynSetup" BO_ 1617 0;
BA_ "VAGTP20_DynConnection" BO_ 1617 0;
BA_ "GenMsgNoIalSupport" BO_ 1617 0;
BA_ "VAGTP20_StatConnection" BO_ 1617 0;
BA_ "NWM-Botschaft" BO_ 1617 0;
BA_ "GenMsgCycleTime" BO_ 997 200;
BA_ "GenMsgSendType" BO_ 997 5;
BA_ "xVWTP_Setup" BO_ 997 0;
BA_ "xVWTP_Channel" BO_ 997 0;
BA_ "VAGTP20_DynSetup" BO_ 997 0;
BA_ "VAGTP20_DynConnection" BO_ 997 0;
BA_ "GenMsgNoIalSupport" BO_ 997 0;
BA_ "VAGTP20_StatConnection" BO_ 997 0;
BA_ "NWM-Botschaft" BO_ 997 0;
BA_ "GenMsgCycleTime" BO_ 1537 200;
BA_ "GenMsgSendType" BO_ 1537 5;
BA_ "xVWTP_Setup" BO_ 1537 0;
BA_ "xVWTP_Channel" BO_ 1537 0;
BA_ "VAGTP20_DynSetup" BO_ 1537 0;
BA_ "VAGTP20_DynConnection" BO_ 1537 0;
BA_ "GenMsgNoIalSupport" BO_ 1537 0;
BA_ "VAGTP20_StatConnection" BO_ 1537 0;
BA_ "NWM-Botschaft" BO_ 1537 0;
BA_ "GenMsgSendType" BO_ 1281 7;
BA_ "xVWTP_Setup" BO_ 1281 0;
BA_ "xVWTP_Channel" BO_ 1281 0;
BA_ "VAGTP20_DynSetup" BO_ 1281 0;
BA_ "VAGTP20_DynConnection" BO_ 1281 0;
BA_ "GenMsgCycleTimeFast" BO_ 1281 100;
BA_ "GenMsgNoIalSupport" BO_ 1281 0;
BA_ "GenMsgNrOfRepetition" BO_ 1281 5;
BA_ "VAGTP20_StatConnection" BO_ 1281 0;
BA_ "NWM-Botschaft" BO_ 1281 0;
BA_ "GenMsgCycleTime" BO_ 1621 500;
BA_ "GenMsgSendType" BO_ 1621 0;
BA_ "xVWTP_Setup" BO_ 1621 0;
BA_ "xVWTP_Channel" BO_ 1621 0;
BA_ "VAGTP20_DynSetup" BO_ 1621 0;
BA_ "VAGTP20_DynConnection" BO_ 1621 0;
BA_ "GenMsgNoIalSupport" BO_ 1621 0;
BA_ "VAGTP20_StatConnection" BO_ 1621 0;
BA_ "NWM-Botschaft" BO_ 1621 0;
BA_ "GenMsgCycleTime" BO_ 1451 1000;
BA_ "GenMsgSendType" BO_ 1451 5;
BA_ "xVWTP_Setup" BO_ 1451 0;
BA_ "xVWTP_Channel" BO_ 1451 0;
BA_ "VAGTP20_DynSetup" BO_ 1451 0;
BA_ "VAGTP20_DynConnection" BO_ 1451 0;
BA_ "GenMsgNoIalSupport" BO_ 1451 0;
BA_ "VAGTP20_StatConnection" BO_ 1451 0;
BA_ "NWM-Botschaft" BO_ 1451 0;
BA_ "GenMsgCycleTime" BO_ 1603 800;
BA_ "GenMsgSendType" BO_ 1603 0;
BA_ "xVWTP_Setup" BO_ 1603 0;
BA_ "xVWTP_Channel" BO_ 1603 0;
BA_ "VAGTP20_DynSetup" BO_ 1603 0;
BA_ "VAGTP20_DynConnection" BO_ 1603 0;
BA_ "GenMsgNoIalSupport" BO_ 1603 0;
BA_ "VAGTP20_StatConnection" BO_ 1603 0;
BA_ "NWM-Botschaft" BO_ 1603 0;
BA_ "GenMsgCycleTime" BO_ 1601 800;
BA_ "GenMsgSendType" BO_ 1601 0;
BA_ "xVWTP_Setup" BO_ 1601 0;
BA_ "xVWTP_Channel" BO_ 1601 0;
BA_ "VAGTP20_DynSetup" BO_ 1601 0;
BA_ "VAGTP20_DynConnection" BO_ 1601 0;
BA_ "GenMsgNoIalSupport" BO_ 1601 0;
BA_ "VAGTP20_StatConnection" BO_ 1601 0;
BA_ "NWM-Botschaft" BO_ 1601 0;
BA_ "GenMsgCycleTime" BO_ 833 800;
BA_ "GenMsgSendType" BO_ 833 5;
BA_ "xVWTP_Setup" BO_ 833 0;
BA_ "xVWTP_Channel" BO_ 833 0;
BA_ "VAGTP20_DynSetup" BO_ 833 0;
BA_ "VAGTP20_DynConnection" BO_ 833 0;
BA_ "GenMsgNoIalSupport" BO_ 833 0;
BA_ "VAGTP20_StatConnection" BO_ 833 0;
BA_ "NWM-Botschaft" BO_ 833 0;
BA_ "GenMsgCycleTime" BO_ 1091 500;
BA_ "GenMsgSendType" BO_ 1091 5;
BA_ "xVWTP_Setup" BO_ 1091 0;
BA_ "xVWTP_Channel" BO_ 1091 0;
BA_ "VAGTP20_DynSetup" BO_ 1091 0;
BA_ "VAGTP20_DynConnection" BO_ 1091 0;
BA_ "GenMsgNoIalSupport" BO_ 1091 0;
BA_ "VAGTP20_StatConnection" BO_ 1091 0;
BA_ "NWM-Botschaft" BO_ 1091 0;
BA_ "GenMsgCycleTime" BO_ 1633 1000;
BA_ "GenMsgSendType" BO_ 1633 5;
BA_ "xVWTP_Setup" BO_ 1633 0;
BA_ "xVWTP_Channel" BO_ 1633 0;
BA_ "VAGTP20_DynSetup" BO_ 1633 0;
BA_ "VAGTP20_DynConnection" BO_ 1633 0;
BA_ "GenMsgNoIalSupport" BO_ 1633 0;
BA_ "VAGTP20_StatConnection" BO_ 1633 0;
BA_ "NWM-Botschaft" BO_ 1633 0;
BA_ "GenMsgCycleTime" BO_ 1519 200;
BA_ "GenMsgSendType" BO_ 1519 5;
BA_ "xVWTP_Setup" BO_ 1519 0;
BA_ "xVWTP_Channel" BO_ 1519 0;
BA_ "VAGTP20_DynSetup" BO_ 1519 0;
BA_ "VAGTP20_DynConnection" BO_ 1519 0;
BA_ "GenMsgNoIalSupport" BO_ 1519 0;
BA_ "VAGTP20_StatConnection" BO_ 1519 0;
BA_ "NWM-Botschaft" BO_ 1519 0;
BA_ "GenMsgCycleTime" BO_ 1349 500;
BA_ "GenMsgSendType" BO_ 1349 5;
BA_ "xVWTP_Setup" BO_ 1349 0;
BA_ "xVWTP_Channel" BO_ 1349 0;
BA_ "VAGTP20_DynSetup" BO_ 1349 0;
BA_ "VAGTP20_DynConnection" BO_ 1349 0;
BA_ "GenMsgNoIalSupport" BO_ 1349 0;
BA_ "VAGTP20_StatConnection" BO_ 1349 0;
BA_ "NWM-Botschaft" BO_ 1349 0;
BA_ "GenMsgCycleTime" BO_ 1025 100;
BA_ "GenMsgSendType" BO_ 1025 5;
BA_ "xVWTP_Setup" BO_ 1025 0;
BA_ "xVWTP_Channel" BO_ 1025 0;
BA_ "VAGTP20_DynSetup" BO_ 1025 0;
BA_ "VAGTP20_DynConnection" BO_ 1025 0;
BA_ "GenMsgNoIalSupport" BO_ 1025 0;
BA_ "VAGTP20_StatConnection" BO_ 1025 0;
BA_ "NWM-Botschaft" BO_ 1025 1;
BA_ "GenMsgCycleTime" BO_ 1040 100;
BA_ "GenMsgSendType" BO_ 1040 5;
BA_ "xVWTP_Setup" BO_ 1040 0;
BA_ "xVWTP_Channel" BO_ 1040 0;
BA_ "VAGTP20_DynSetup" BO_ 1040 0;
BA_ "VAGTP20_DynConnection" BO_ 1040 0;
BA_ "GenMsgNoIalSupport" BO_ 1040 0;
BA_ "VAGTP20_StatConnection" BO_ 1040 0;
BA_ "NWM-Botschaft" BO_ 1040 1;
BA_ "GenMsgCycleTime" BO_ 1029 100;
BA_ "GenMsgSendType" BO_ 1029 5;
BA_ "xVWTP_Setup" BO_ 1029 0;
BA_ "xVWTP_Channel" BO_ 1029 0;
BA_ "VAGTP20_DynSetup" BO_ 1029 0;
BA_ "VAGTP20_DynConnection" BO_ 1029 0;
BA_ "GenMsgNoIalSupport" BO_ 1029 0;
BA_ "VAGTP20_StatConnection" BO_ 1029 0;
BA_ "NWM-Botschaft" BO_ 1029 1;
BA_ "GenMsgCycleTime" BO_ 1028 100;
BA_ "GenMsgSendType" BO_ 1028 5;
BA_ "xVWTP_Setup" BO_ 1028 0;
BA_ "xVWTP_Channel" BO_ 1028 0;
BA_ "VAGTP20_DynSetup" BO_ 1028 0;
BA_ "VAGTP20_DynConnection" BO_ 1028 0;
BA_ "GenMsgNoIalSupport" BO_ 1028 0;
BA_ "VAGTP20_StatConnection" BO_ 1028 0;
BA_ "NWM-Botschaft" BO_ 1028 1;
BA_ "GenMsgCycleTime" BO_ 1026 100;
BA_ "GenMsgSendType" BO_ 1026 5;
BA_ "xVWTP_Setup" BO_ 1026 0;
BA_ "xVWTP_Channel" BO_ 1026 0;
BA_ "VAGTP20_DynSetup" BO_ 1026 0;
BA_ "VAGTP20_DynConnection" BO_ 1026 0;
BA_ "GenMsgNoIalSupport" BO_ 1026 0;
BA_ "VAGTP20_StatConnection" BO_ 1026 0;
BA_ "NWM-Botschaft" BO_ 1026 1;
BA_ "GenMsgCycleTime" BO_ 1027 100;
BA_ "GenMsgSendType" BO_ 1027 5;
BA_ "xVWTP_Setup" BO_ 1027 0;
BA_ "xVWTP_Channel" BO_ 1027 0;
BA_ "VAGTP20_DynSetup" BO_ 1027 0;
BA_ "VAGTP20_DynConnection" BO_ 1027 0;
BA_ "GenMsgNoIalSupport" BO_ 1027 0;
BA_ "VAGTP20_StatConnection" BO_ 1027 0;
BA_ "NWM-Botschaft" BO_ 1027 1;
BA_ "GenMsgCycleTime" BO_ 1034 100;
BA_ "GenMsgSendType" BO_ 1034 5;
BA_ "xVWTP_Setup" BO_ 1034 0;
BA_ "xVWTP_Channel" BO_ 1034 0;
BA_ "VAGTP20_DynSetup" BO_ 1034 0;
BA_ "VAGTP20_DynConnection" BO_ 1034 0;
BA_ "GenMsgNoIalSupport" BO_ 1034 0;
BA_ "VAGTP20_StatConnection" BO_ 1034 0;
BA_ "NWM-Botschaft" BO_ 1034 1;
BA_ "GenSigSendType" SG_ 1425 ZK4_ZVOeffnung 3;
BA_ "GenSigSendType" SG_ 1425 ZK4_verriegelt_int 3;
BA_ "GenSigSendType" SG_ 1425 ZK4_verriegelt_ext 3;
BA_ "GenSigSendType" SG_ 1425 ZK4_Verdeck_enable 3;
BA_ "GenSigSendType" SG_ 1425 ZK4_Verbau_ZV 3;
BA_ "GenSigSendType" SG_ 1425 ZK4_Verbau_Viertuerer 3;
BA_ "GenSigSendType" SG_ 1425 ZK4_Verbau_Neigung 3;
BA_ "GenSigSendType" SG_ 1425 ZK4_Verbau_eFH_vorn 3;
BA_ "GenSigSendType" SG_ 1425 ZK4_Verbau_eFH_hinten 3;
BA_ "GenSigSendType" SG_ 1425 ZK4_Synchro_Spiegel 3;
BA_ "GenSigSendType" SG_ 1425 ZK4_SD_Komfortoeffnen 3;
BA_ "GenSigSendType" SG_ 1425 ZK4_Schlosstyp 3;
BA_ "GenSigSendType" SG_ 1425 ZK4_SAD_Freigabe 3;
BA_ "GenSigSendType" SG_ 1425 ZK4_Rechtslenker 3;
BA_ "GenSigSendType" SG_ 1425 ZK4_Neigung_aktiv 3;
BA_ "GenSigSendType" SG_ 1425 ZK4_Komfortfkt_Enable 3;
BA_ "GenSigSendType" SG_ 1425 ZK4_KD_Fehler 3;
BA_ "GenSigSendType" SG_ 1425 ZK4_ist_verriegelt_intern 3;
BA_ "GenSigSendType" SG_ 1425 ZK4_IRUE_aktiv 3;
BA_ "GenSigSendType" SG_ 1425 ZK4_HR_Tuer_offen 3;
BA_ "GenSigSendType" SG_ 1425 ZK4_HL_Tuer_offen 3;
BA_ "GenSigSendType" SG_ 1425 ZK4_HDOeffnung 3;
BA_ "GenSigSendType" SG_ 1425 ZK4_HD_Vorraste 3;
BA_ "GenSigSendType" SG_ 1425 ZK4_HD_Hauptraste 3;
BA_ "GenSigSendType" SG_ 1425 ZK4_HD_Auf_Taster 3;
BA_ "GenSigSendType" SG_ 1425 ZK4_Handbremse_aktiv 3;
BA_ "GenSigSendType" SG_ 1425 ZK4_gesafet_ext 3;
BA_ "GenSigSendType" SG_ 1425 ZK4_FH_Komfortoeffnen 3;
BA_ "GenSigSendType" SG_ 1425 ZK4_FH_Freigabe 3;
BA_ "GenSigSendType" SG_ 1425 ZK4_Einzeltuerentrieg 3;
BA_ "GenSigSendType" SG_ 1425 ZK4_DWA_Akku_leer 3;
BA_ "GenSigSendType" SG_ 1425 ZK4_Autolock 3;
BA_ "GenSigSendType" SG_ 1425 ZK4_Auto_Unlock 3;
BA_ "GenSigSendType" SG_ 1425 ZK4_AD_Komfortoeffnen 3;
BA_ "GenSigSendType" SG_ 1425 ZK4_Absenk_Spiegel 3;
BA_ "SignalRepeatActivation" SG_ 917 ZK3_Blk_ZV_zu 5;
BA_ "SignalRepeatDeactivation" SG_ 917 ZK3_Blk_ZV_zu 5;
BA_ "GenSigSendType" SG_ 917 ZK3_Blk_ZV_zu 4;
BA_ "SignalRepeatActivation" SG_ 917 ZK3_Blk_ZV_auf 5;
BA_ "SignalRepeatDeactivation" SG_ 917 ZK3_Blk_ZV_auf 5;
BA_ "GenSigSendType" SG_ 917 ZK3_Blk_ZV_auf 4;
BA_ "SignalRepeatActivation" SG_ 917 ZK3_Blk_Panik 5;
BA_ "SignalRepeatDeactivation" SG_ 917 ZK3_Blk_Panik 5;
BA_ "GenSigSendType" SG_ 917 ZK3_Blk_Panik 4;
BA_ "SignalRepeatActivation" SG_ 917 ZK3_Blk_learn 5;
BA_ "SignalRepeatDeactivation" SG_ 917 ZK3_Blk_learn 5;
BA_ "GenSigSendType" SG_ 917 ZK3_Blk_learn 4;
BA_ "SignalRepeatActivation" SG_ 917 ZK3_Blk_DWA_ein 5;
BA_ "SignalRepeatDeactivation" SG_ 917 ZK3_Blk_DWA_ein 5;
BA_ "GenSigSendType" SG_ 917 ZK3_Blk_DWA_ein 4;
BA_ "SignalRepeatActivation" SG_ 917 ZK3_Blk_DWA_Alarm 5;
BA_ "SignalRepeatDeactivation" SG_ 917 ZK3_Blk_DWA_Alarm 5;
BA_ "GenSigSendType" SG_ 917 ZK3_Blk_DWA_Alarm 4;
BA_ "SignalRepeatActivation" SG_ 917 ZK3_Blk_Crash 5;
BA_ "SignalRepeatDeactivation" SG_ 917 ZK3_Blk_Crash 5;
BA_ "GenSigSendType" SG_ 917 ZK3_Blk_Crash 4;
BA_ "SignalRepeatActivation" SG_ 917 ZK3_Blinker_ein 5;
BA_ "SignalRepeatDeactivation" SG_ 917 ZK3_Blinker_ein 5;
BA_ "GenSigSendType" SG_ 917 ZK3_Blinker_ein 4;
BA_ "SignalRepeatActivation" SG_ 913 ZK2_ZV_zu_Heck 5;
BA_ "SignalRepeatDeactivation" SG_ 913 ZK2_ZV_zu_Heck 5;
BA_ "GenSigSendType" SG_ 913 ZK2_ZV_zu_Heck 4;
BA_ "SignalRepeatActivation" SG_ 913 ZK2_ZV_zu_Funk 5;
BA_ "SignalRepeatDeactivation" SG_ 913 ZK2_ZV_zu_Funk 5;
BA_ "GenSigSendType" SG_ 913 ZK2_ZV_zu_Funk 4;
BA_ "SignalRepeatActivation" SG_ 913 ZK2_ZV_zu_FT 5;
BA_ "SignalRepeatDeactivation" SG_ 913 ZK2_ZV_zu_FT 5;
BA_ "GenSigSendType" SG_ 913 ZK2_ZV_zu_FT 4;
BA_ "SignalRepeatActivation" SG_ 913 ZK2_ZV_zu_BT 5;
BA_ "SignalRepeatDeactivation" SG_ 913 ZK2_ZV_zu_BT 5;
BA_ "GenSigSendType" SG_ 913 ZK2_ZV_zu_BT 4;
BA_ "SignalRepeatActivation" SG_ 913 ZK2_ZV_auf_Heck 5;
BA_ "SignalRepeatDeactivation" SG_ 913 ZK2_ZV_auf_Heck 5;
BA_ "GenSigSendType" SG_ 913 ZK2_ZV_auf_Heck 4;
BA_ "SignalRepeatActivation" SG_ 913 ZK2_ZV_auf_Funk 5;
BA_ "SignalRepeatDeactivation" SG_ 913 ZK2_ZV_auf_Funk 5;
BA_ "GenSigSendType" SG_ 913 ZK2_ZV_auf_Funk 4;
BA_ "SignalRepeatActivation" SG_ 913 ZK2_ZV_auf_FT 5;
BA_ "SignalRepeatDeactivation" SG_ 913 ZK2_ZV_auf_FT 5;
BA_ "GenSigSendType" SG_ 913 ZK2_ZV_auf_FT 4;
BA_ "SignalRepeatActivation" SG_ 913 ZK2_ZV_auf_BT 5;
BA_ "SignalRepeatDeactivation" SG_ 913 ZK2_ZV_auf_BT 5;
BA_ "GenSigSendType" SG_ 913 ZK2_ZV_auf_BT 4;
BA_ "SignalRepeatActivation" SG_ 913 ZK2_SAD_Zu 5;
BA_ "SignalRepeatDeactivation" SG_ 913 ZK2_SAD_Zu 5;
BA_ "GenSigSendType" SG_ 913 ZK2_SAD_Zu 4;
BA_ "SignalRepeatActivation" SG_ 913 ZK2_SAD_Hoch 5;
BA_ "SignalRepeatDeactivation" SG_ 913 ZK2_SAD_Hoch 5;
BA_ "GenSigSendType" SG_ 913 ZK2_SAD_Hoch 4;
BA_ "SignalRepeatActivation" SG_ 913 ZK2_SAD_Auf 5;
BA_ "SignalRepeatDeactivation" SG_ 913 ZK2_SAD_Auf 5;
BA_ "GenSigSendType" SG_ 913 ZK2_SAD_Auf 4;
BA_ "SignalRepeatActivation" SG_ 913 ZK2_FH_Zu_Z_man 5;
BA_ "SignalRepeatDeactivation" SG_ 913 ZK2_FH_Zu_Z_man 5;
BA_ "GenSigSendType" SG_ 913 ZK2_FH_Zu_Z_man 4;
BA_ "SignalRepeatActivation" SG_ 913 ZK2_FH_Zu_Z_auto 5;
BA_ "SignalRepeatDeactivation" SG_ 913 ZK2_FH_Zu_Z_auto 5;
BA_ "GenSigSendType" SG_ 913 ZK2_FH_Zu_Z_auto 4;
BA_ "SignalRepeatActivation" SG_ 913 ZK2_FH_HR_tief 5;
BA_ "SignalRepeatDeactivation" SG_ 913 ZK2_FH_HR_tief 5;
BA_ "GenSigSendType" SG_ 913 ZK2_FH_HR_tief 4;
BA_ "SignalRepeatActivation" SG_ 913 ZK2_FH_HR_hoch 5;
BA_ "SignalRepeatDeactivation" SG_ 913 ZK2_FH_HR_hoch 5;
BA_ "GenSigSendType" SG_ 913 ZK2_FH_HR_hoch 4;
BA_ "SignalRepeatActivation" SG_ 913 ZK2_FH_HL_tief 5;
BA_ "SignalRepeatDeactivation" SG_ 913 ZK2_FH_HL_tief 5;
BA_ "GenSigSendType" SG_ 913 ZK2_FH_HL_tief 4;
BA_ "SignalRepeatActivation" SG_ 913 ZK2_FH_HL_hoch 5;
BA_ "SignalRepeatDeactivation" SG_ 913 ZK2_FH_HL_hoch 5;
BA_ "GenSigSendType" SG_ 913 ZK2_FH_HL_hoch 4;
BA_ "SignalRepeatActivation" SG_ 913 ZK2_FH_FT_tief 5;
BA_ "SignalRepeatDeactivation" SG_ 913 ZK2_FH_FT_tief 5;
BA_ "GenSigSendType" SG_ 913 ZK2_FH_FT_tief 4;
BA_ "SignalRepeatActivation" SG_ 913 ZK2_FH_FT_hoch 5;
BA_ "SignalRepeatDeactivation" SG_ 913 ZK2_FH_FT_hoch 5;
BA_ "GenSigSendType" SG_ 913 ZK2_FH_FT_hoch 4;
BA_ "SignalRepeatActivation" SG_ 913 ZK2_FH_BT_tief 5;
BA_ "SignalRepeatDeactivation" SG_ 913 ZK2_FH_BT_tief 5;
BA_ "GenSigSendType" SG_ 913 ZK2_FH_BT_tief 4;
BA_ "SignalRepeatActivation" SG_ 913 ZK2_FH_BT_hoch 5;
BA_ "SignalRepeatDeactivation" SG_ 913 ZK2_FH_BT_hoch 5;
BA_ "GenSigSendType" SG_ 913 ZK2_FH_BT_hoch 4;
BA_ "SignalRepeatActivation" SG_ 913 ZK2_FH_Auf_Z_man 5;
BA_ "SignalRepeatDeactivation" SG_ 913 ZK2_FH_Auf_Z_man 5;
BA_ "GenSigSendType" SG_ 913 ZK2_FH_Auf_Z_man 4;
BA_ "SignalRepeatActivation" SG_ 913 ZK2_FH_Auf_Z_auto 5;
BA_ "SignalRepeatDeactivation" SG_ 913 ZK2_FH_Auf_Z_auto 5;
BA_ "GenSigSendType" SG_ 913 ZK2_FH_Auf_Z_auto 4;
BA_ "SignalRepeatActivation" SG_ 657 ZK1_Zent_safen 5;
BA_ "SignalRepeatDeactivation" SG_ 657 ZK1_Zent_safen 5;
BA_ "GenSigSendType" SG_ 657 ZK1_Zent_safen 4;
BA_ "SignalRepeatActivation" SG_ 657 ZK1_Zent_entsafen 5;
BA_ "SignalRepeatDeactivation" SG_ 657 ZK1_Zent_entsafen 5;
BA_ "GenSigSendType" SG_ 657 ZK1_Zent_entsafen 4;
BA_ "SignalRepeatActivation" SG_ 657 ZK1_Taste_Zu 5;
BA_ "SignalRepeatDeactivation" SG_ 657 ZK1_Taste_Zu 5;
BA_ "GenSigSendType" SG_ 657 ZK1_Taste_Zu 4;
BA_ "SignalRepeatActivation" SG_ 657 ZK1_Taste_Panik 5;
BA_ "SignalRepeatDeactivation" SG_ 657 ZK1_Taste_Panik 5;
BA_ "GenSigSendType" SG_ 657 ZK1_Taste_Panik 4;
BA_ "SignalRepeatActivation" SG_ 657 ZK1_Taste_HDF 5;
BA_ "SignalRepeatDeactivation" SG_ 657 ZK1_Taste_HDF 5;
BA_ "GenSigSendType" SG_ 657 ZK1_Taste_HDF 4;
BA_ "SignalRepeatActivation" SG_ 657 ZK1_Taste_Auf 5;
BA_ "SignalRepeatDeactivation" SG_ 657 ZK1_Taste_Auf 5;
BA_ "GenSigSendType" SG_ 657 ZK1_Taste_Auf 4;
BA_ "SignalRepeatActivation" SG_ 657 ZK1_LED_Uebernahme 5;
BA_ "SignalRepeatDeactivation" SG_ 657 ZK1_LED_Uebernahme 5;
BA_ "GenSigSendType" SG_ 657 ZK1_LED_Uebernahme 4;
BA_ "SignalRepeatActivation" SG_ 657 ZK1_LED_Steuerung 5;
BA_ "SignalRepeatDeactivation" SG_ 657 ZK1_LED_Steuerung 5;
BA_ "GenSigSendType" SG_ 657 ZK1_LED_Steuerung 4;
BA_ "SignalRepeatActivation" SG_ 657 ZK1_HR_verriegeln 5;
BA_ "SignalRepeatDeactivation" SG_ 657 ZK1_HR_verriegeln 5;
BA_ "GenSigSendType" SG_ 657 ZK1_HR_verriegeln 4;
BA_ "SignalRepeatActivation" SG_ 657 ZK1_HR_Tuer_offen 5;
BA_ "SignalRepeatDeactivation" SG_ 657 ZK1_HR_Tuer_offen 5;
BA_ "GenSigSendType" SG_ 657 ZK1_HR_Tuer_offen 4;
BA_ "SignalRepeatActivation" SG_ 657 ZK1_HR_entriegeln 5;
BA_ "SignalRepeatDeactivation" SG_ 657 ZK1_HR_entriegeln 5;
BA_ "GenSigSendType" SG_ 657 ZK1_HR_entriegeln 4;
BA_ "SignalRepeatActivation" SG_ 657 ZK1_HL_verriegeln 5;
BA_ "SignalRepeatDeactivation" SG_ 657 ZK1_HL_verriegeln 5;
BA_ "GenSigSendType" SG_ 657 ZK1_HL_verriegeln 4;
BA_ "SignalRepeatActivation" SG_ 657 ZK1_HL_Tuer_offen 5;
BA_ "SignalRepeatDeactivation" SG_ 657 ZK1_HL_Tuer_offen 5;
BA_ "GenSigSendType" SG_ 657 ZK1_HL_Tuer_offen 4;
BA_ "SignalRepeatActivation" SG_ 657 ZK1_HL_entriegeln 5;
BA_ "SignalRepeatDeactivation" SG_ 657 ZK1_HL_entriegeln 5;
BA_ "GenSigSendType" SG_ 657 ZK1_HL_entriegeln 4;
BA_ "SignalRepeatActivation" SG_ 657 ZK1_HD_verriegeln 5;
BA_ "SignalRepeatDeactivation" SG_ 657 ZK1_HD_verriegeln 5;
BA_ "GenSigSendType" SG_ 657 ZK1_HD_verriegeln 4;
BA_ "SignalRepeatActivation" SG_ 657 ZK1_HD_schliessen 5;
BA_ "SignalRepeatDeactivation" SG_ 657 ZK1_HD_schliessen 5;
BA_ "GenSigSendType" SG_ 657 ZK1_HD_schliessen 4;
BA_ "SignalRepeatActivation" SG_ 657 ZK1_HD_oeffnen 5;
BA_ "SignalRepeatDeactivation" SG_ 657 ZK1_HD_oeffnen 5;
BA_ "GenSigSendType" SG_ 657 ZK1_HD_oeffnen 4;
BA_ "SignalRepeatActivation" SG_ 657 ZK1_HD_entriegeln 5;
BA_ "SignalRepeatDeactivation" SG_ 657 ZK1_HD_entriegeln 5;
BA_ "GenSigSendType" SG_ 657 ZK1_HD_entriegeln 4;
BA_ "SignalRepeatActivation" SG_ 657 ZK1_Funkschl_Nr 5;
BA_ "SignalRepeatDeactivation" SG_ 657 ZK1_Funkschl_Nr 5;
BA_ "GenSigSendType" SG_ 657 ZK1_Funkschl_Nr 4;
BA_ "SignalRepeatActivation" SG_ 657 ZK1_FT_verriegeln 5;
BA_ "SignalRepeatDeactivation" SG_ 657 ZK1_FT_verriegeln 5;
BA_ "GenSigSendType" SG_ 657 ZK1_FT_verriegeln 4;
BA_ "SignalRepeatActivation" SG_ 657 ZK1_FT_entriegeln 5;
BA_ "SignalRepeatDeactivation" SG_ 657 ZK1_FT_entriegeln 5;
BA_ "GenSigSendType" SG_ 657 ZK1_FT_entriegeln 4;
BA_ "SignalRepeatActivation" SG_ 657 ZK1_BT_verriegeln 5;
BA_ "SignalRepeatDeactivation" SG_ 657 ZK1_BT_verriegeln 5;
BA_ "GenSigSendType" SG_ 657 ZK1_BT_verriegeln 4;
BA_ "SignalRepeatActivation" SG_ 657 ZK1_BT_entriegeln 5;
BA_ "SignalRepeatDeactivation" SG_ 657 ZK1_BT_entriegeln 5;
BA_ "GenSigSendType" SG_ 657 ZK1_BT_entriegeln 4;
BA_ "SignalRepeatActivation" SG_ 657 ZK1_433_MHz 5;
BA_ "SignalRepeatDeactivation" SG_ 657 ZK1_433_MHz 5;
BA_ "GenSigSendType" SG_ 657 ZK1_433_MHz 4;
BA_ "GenSigSendType" SG_ 707 ZS1_ZAS_Kl_X 3;
BA_ "GenSigSendType" SG_ 707 ZS1_ZAS_Kl_S 3;
BA_ "GenSigSendType" SG_ 707 ZS1_ZAS_KL_P 3;
BA_ "GenSigSendType" SG_ 707 ZS1_ZAS_Kl_50 3;
BA_ "GenSigSendType" SG_ 707 ZS1_ZAS_Kl_15 3;
BA_ "GenSigSendType" SG_ 1489 WI1_Heck_Wasch 3;
BA_ "GenSigSendType" SG_ 1489 WI1_Heck_Normal 3;
BA_ "GenSigSendType" SG_ 1489 WI1_Heck_ein 3;
BA_ "GenSigSendType" SG_ 1489 WI1_Heck_Blockiert 3;
BA_ "GenSigSendType" SG_ 1489 WI1_Front_Wasch 3;
BA_ "GenSigSendType" SG_ 1489 WI1_Front_Schnell 3;
BA_ "GenSigSendType" SG_ 1489 WI1_Front_Parklage 3;
BA_ "GenSigSendType" SG_ 1489 WI1_Front_Normal 3;
BA_ "GenSigSendType" SG_ 1489 WI1_Front_ein 3;
BA_ "GenSigSendType" SG_ 1361 WF1_Schluessel 7;
BA_ "GenSigSendType" SG_ 1497 VS1_Verdeck_Anf 3;
BA_ "GenSigSendType" SG_ 1497 VS1_VD_Zwischenposition 3;
BA_ "GenSigSendType" SG_ 1497 VS1_VD_zu_ver 3;
BA_ "GenSigSendType" SG_ 1497 VS1_VD_offen_ver 3;
BA_ "GenSigSendType" SG_ 1497 VS1_VD_Fehler 3;
BA_ "GenSigSendType" SG_ 1497 VS1_VD_entriegelt 3;
BA_ "GenSigSendType" SG_ 1497 VS1_VD_Bew_zu 3;
BA_ "GenSigSendType" SG_ 1497 VS1_VD_Bew_auf 3;
BA_ "GenSigSendType" SG_ 1497 VS1_Texte 3;
BA_ "GenSigSendType" SG_ 1497 VS1_Lampe_Blk 3;
BA_ "GenSigSendType" SG_ 1497 VS1_KD_Fehler 3;
BA_ "GenSigSendType" SG_ 1497 VS1_HHS_enable 3;
BA_ "GenSigSendType" SG_ 1497 VS1_Hardtop 3;
BA_ "GenSigSendType" SG_ 1497 VS1_Freigabe_FH 3;
BA_ "GenSigSendType" SG_ 1497 VS1_FH_HR_tief 3;
BA_ "GenSigSendType" SG_ 1497 VS1_FH_HR_hoch 3;
BA_ "GenSigSendType" SG_ 1497 VS1_FH_HL_tief 3;
BA_ "GenSigSendType" SG_ 1497 VS1_FH_HL_hoch 3;
BA_ "GenSigSendType" SG_ 1497 VS1_FH_FT_tief 3;
BA_ "GenSigSendType" SG_ 1497 VS1_FH_FT_hoch 3;
BA_ "GenSigSendType" SG_ 1497 VS1_FH_BT_tief 3;
BA_ "GenSigSendType" SG_ 1497 VS1_FH_BT_hoch 3;
BA_ "GenSigSendType" SG_ 1497 VS1_Buzzer 3;
BA_ "GenSigSendType" SG_ 1213 HR1_UEKB_aktiviert 7;
BA_ "GenSigSendType" SG_ 1213 HR1_KD_Fehler 3;
BA_ "GenSigSendType" SG_ 1213 HR1_FH_Thermo 7;
BA_ "GenSigSendType" SG_ 1213 HR1_FH_Oeffnung 7;
BA_ "GenSigSendType" SG_ 1213 HR1_FH_normiert 7;
BA_ "GenSigSendType" SG_ 1213 HR1_FH_Fang 7;
BA_ "GenSigSendType" SG_ 1213 HR1_FH_Block 7;
BA_ "GenSigSendType" SG_ 1213 HR1_FH_Bew_tief 7;
BA_ "GenSigSendType" SG_ 1213 HR1_FH_Bew_hoch 7;
BA_ "GenSigSendType" SG_ 1209 HL1_UEKB_aktiviert 7;
BA_ "GenSigSendType" SG_ 1209 HL1_KD_Fehler 3;
BA_ "GenSigSendType" SG_ 1209 HL1_FH_Thermo 7;
BA_ "GenSigSendType" SG_ 1209 HL1_FH_Oeffnung 7;
BA_ "GenSigSendType" SG_ 1209 HL1_FH_normiert 7;
BA_ "GenSigSendType" SG_ 1209 HL1_FH_Fang 7;
BA_ "GenSigSendType" SG_ 1209 HL1_FH_Block 7;
BA_ "GenSigSendType" SG_ 1209 HL1_FH_Bew_tief 7;
BA_ "GenSigSendType" SG_ 1209 HL1_FH_Bew_hoch 7;
BA_ "GenSigSendType" SG_ 899 FT3_Verriegeln 3;
BA_ "GenSigSendType" SG_ 899 FT3_TIG_FT_Freigabe 3;
BA_ "GenSigSendType" SG_ 899 FT3_TIG_BT_Freigabe 3;
BA_ "GenSigSendType" SG_ 899 FT3_TIG 3;
BA_ "GenSigSendType" SG_ 899 FT3_TAG 3;
BA_ "GenSigSendType" SG_ 897 FT1_verriegelt 3;
BA_ "GenSigSendType" SG_ 897 FT1_Unlock_Taster 3;
BA_ "GenSigSendType" SG_ 897 FT1_UEKB_aktiviert 7;
BA_ "GenSigSendType" SG_ 897 FT1_Tuer_geoeffnet 3;
BA_ "GenSigSendType" SG_ 897 FT1_Tankklappe_oeffnen 7;
BA_ "GenSigSendType" SG_ 897 FT1_SP_Heizung_ein 7;
BA_ "GenSigSendType" SG_ 897 FT1_SP_ausgerastet 7;
BA_ "GenSigSendType" SG_ 897 FT1_SP_AS_verbaut 7;
BA_ "GenSigSendType" SG_ 897 FT1_Schl_zu 3;
BA_ "GenSigSendType" SG_ 897 FT1_Schl_auf 3;
BA_ "GenSigSendType" SG_ 897 FT1_Neig_Taster 7;
BA_ "GenSigSendType" SG_ 897 FT1_Lock_Taster 3;
BA_ "GenSigSendType" SG_ 897 FT1_KD_Fehler 3;
BA_ "GenSigSendType" SG_ 897 FT1_IRUE_Taste 7;
BA_ "GenSigSendType" SG_ 897 FT1_HD_oeffnen 7;
BA_ "GenSigSendType" SG_ 897 FT1_gesafet 3;
BA_ "GenSigSendType" SG_ 897 FT1_FH_Thermo 7;
BA_ "GenSigSendType" SG_ 897 FT1_FH_Oeffnung 7;
BA_ "GenSigSendType" SG_ 897 FT1_FH_normiert 7;
BA_ "GenSigSendType" SG_ 897 FT1_FH_HR_Freigabe 7;
BA_ "GenSigSendType" SG_ 897 FT1_FH_HL_Freigabe 7;
BA_ "GenSigSendType" SG_ 897 FT1_FH_FT_Freigabe 7;
BA_ "GenSigSendType" SG_ 897 FT1_FH_Fang 7;
BA_ "GenSigSendType" SG_ 897 FT1_FH_BT_Freigabe 7;
BA_ "GenSigSendType" SG_ 897 FT1_FH_Block 7;
BA_ "GenSigSendType" SG_ 897 FT1_FH_Bew_tief 7;
BA_ "GenSigSendType" SG_ 897 FT1_FH_Bew_hoch 7;
BA_ "SignalRepeatActivation" SG_ 385 FT0_FH_HR_ManTief 5;
BA_ "SignalRepeatDeactivation" SG_ 385 FT0_FH_HR_ManTief 5;
BA_ "GenSigSendType" SG_ 385 FT0_FH_HR_ManTief 4;
BA_ "SignalRepeatActivation" SG_ 385 FT0_FH_HR_ManHoch 5;
BA_ "SignalRepeatDeactivation" SG_ 385 FT0_FH_HR_ManHoch 5;
BA_ "GenSigSendType" SG_ 385 FT0_FH_HR_ManHoch 4;
BA_ "SignalRepeatActivation" SG_ 385 FT0_FH_HR_AutoTief 5;
BA_ "SignalRepeatDeactivation" SG_ 385 FT0_FH_HR_AutoTief 5;
BA_ "GenSigSendType" SG_ 385 FT0_FH_HR_AutoTief 4;
BA_ "SignalRepeatActivation" SG_ 385 FT0_FH_HR_AutoHoch 5;
BA_ "SignalRepeatDeactivation" SG_ 385 FT0_FH_HR_AutoHoch 5;
BA_ "GenSigSendType" SG_ 385 FT0_FH_HR_AutoHoch 4;
BA_ "SignalRepeatActivation" SG_ 385 FT0_FH_HL_ManTief 5;
BA_ "SignalRepeatDeactivation" SG_ 385 FT0_FH_HL_ManTief 5;
BA_ "GenSigSendType" SG_ 385 FT0_FH_HL_ManTief 4;
BA_ "SignalRepeatActivation" SG_ 385 FT0_FH_HL_ManHoch 5;
BA_ "SignalRepeatDeactivation" SG_ 385 FT0_FH_HL_ManHoch 5;
BA_ "GenSigSendType" SG_ 385 FT0_FH_HL_ManHoch 4;
BA_ "SignalRepeatActivation" SG_ 385 FT0_FH_HL_AutoTief 5;
BA_ "SignalRepeatDeactivation" SG_ 385 FT0_FH_HL_AutoTief 5;
BA_ "GenSigSendType" SG_ 385 FT0_FH_HL_AutoTief 4;
BA_ "SignalRepeatActivation" SG_ 385 FT0_FH_HL_AutoHoch 5;
BA_ "SignalRepeatDeactivation" SG_ 385 FT0_FH_HL_AutoHoch 5;
BA_ "GenSigSendType" SG_ 385 FT0_FH_HL_AutoHoch 4;
BA_ "SignalRepeatActivation" SG_ 385 FT0_FH_FT_ManTief 5;
BA_ "SignalRepeatDeactivation" SG_ 385 FT0_FH_FT_ManTief 5;
BA_ "GenSigSendType" SG_ 385 FT0_FH_FT_ManTief 4;
BA_ "SignalRepeatActivation" SG_ 385 FT0_FH_FT_ManHoch 5;
BA_ "SignalRepeatDeactivation" SG_ 385 FT0_FH_FT_ManHoch 5;
BA_ "GenSigSendType" SG_ 385 FT0_FH_FT_ManHoch 4;
BA_ "SignalRepeatActivation" SG_ 385 FT0_FH_FT_AutoTief 5;
BA_ "SignalRepeatDeactivation" SG_ 385 FT0_FH_FT_AutoTief 5;
BA_ "GenSigSendType" SG_ 385 FT0_FH_FT_AutoTief 4;
BA_ "SignalRepeatActivation" SG_ 385 FT0_FH_FT_AutoHoch 5;
BA_ "SignalRepeatDeactivation" SG_ 385 FT0_FH_FT_AutoHoch 5;
BA_ "GenSigSendType" SG_ 385 FT0_FH_FT_AutoHoch 4;
BA_ "SignalRepeatActivation" SG_ 385 FT0_FH_BT_ManTief 5;
BA_ "SignalRepeatDeactivation" SG_ 385 FT0_FH_BT_ManTief 5;
BA_ "GenSigSendType" SG_ 385 FT0_FH_BT_ManTief 4;
BA_ "SignalRepeatActivation" SG_ 385 FT0_FH_BT_ManHoch 5;
BA_ "SignalRepeatDeactivation" SG_ 385 FT0_FH_BT_ManHoch 5;
BA_ "GenSigSendType" SG_ 385 FT0_FH_BT_ManHoch 4;
BA_ "SignalRepeatActivation" SG_ 385 FT0_FH_BT_AutoTief 5;
BA_ "SignalRepeatDeactivation" SG_ 385 FT0_FH_BT_AutoTief 5;
BA_ "GenSigSendType" SG_ 385 FT0_FH_BT_AutoTief 4;
BA_ "SignalRepeatActivation" SG_ 385 FT0_FH_BT_AutoHoch 5;
BA_ "SignalRepeatDeactivation" SG_ 385 FT0_FH_BT_AutoHoch 5;
BA_ "GenSigSendType" SG_ 385 FT0_FH_BT_AutoHoch 4;
BA_ "GenSigSendType" SG_ 949 BT1_verriegelt 3;
BA_ "GenSigSendType" SG_ 949 BT1_Unlock_Taster 3;
BA_ "GenSigSendType" SG_ 949 BT1_UEKB_aktiviert 7;
BA_ "GenSigSendType" SG_ 949 BT1_Tuer_geoeffnet 3;
BA_ "GenSigSendType" SG_ 949 BT1_SP_Heizung_ein 7;
BA_ "GenSigSendType" SG_ 949 BT1_SP_ausgerastet 7;
BA_ "GenSigSendType" SG_ 949 BT1_SP_AS_verbaut 7;
BA_ "GenSigSendType" SG_ 949 BT1_Schl_zu 3;
BA_ "GenSigSendType" SG_ 949 BT1_Schl_auf 3;
BA_ "GenSigSendType" SG_ 949 BT1_Lock_Taster 3;
BA_ "GenSigSendType" SG_ 949 BT1_KD_Fehler 3;
BA_ "GenSigSendType" SG_ 949 BT1_gesafet 3;
BA_ "GenSigSendType" SG_ 949 BT1_FH_Thermo 7;
BA_ "GenSigSendType" SG_ 949 BT1_FH_Oeffnung 7;
BA_ "GenSigSendType" SG_ 949 BT1_FH_normiert 7;
BA_ "GenSigSendType" SG_ 949 BT1_FH_Fang 7;
BA_ "GenSigSendType" SG_ 949 BT1_FH_Block 7;
BA_ "GenSigSendType" SG_ 949 BT1_FH_Bew_tief 7;
BA_ "GenSigSendType" SG_ 949 BT1_FH_Bew_hoch 7;
BA_ "GenSigSendType" SG_ 562 Wischermodul_TP_Er 5;
BA_ "GenSigSendType" SG_ 560 VSG_TP_Er 5;
BA_ "GenSigSendType" SG_ 549 HR_TP_Er 5;
BA_ "GenSigSendType" SG_ 548 HL_TP_Er 5;
BA_ "GenSigSendType" SG_ 546 FT_TP_Er 5;
BA_ "GenSigSendType" SG_ 547 BT_TP_Er 5;
BA_ "GenSigSendType" SG_ 512 Tester_TP_Er 5;
BA_ "GenSigSendType" SG_ 554 SMLS_TP_Er 5;
BA_ "GenSigSendType" SG_ 559 SH_TP_Er 5;
BA_ "GenSigSendType" SG_ 553 RDK_TP_Er 5;
BA_ "GenSigSendType" SG_ 558 PTC_TP_Er 5;
BA_ "GenSigSendType" SG_ 570 MFG_TP_Er 5;
BA_ "GenSigSendType" SG_ 565 Mem_BF_TP_Er 5;
BA_ "GenSigSendType" SG_ 550 MEM_TP_Er 5;
BA_ "GenSigSendType" SG_ 545 KSG_TP_Er 5;
BA_ "GenSigSendType" SG_ 543 Gateway_TP_Er 5;
BA_ "GenSigSendType" SG_ 556 CL_TP_Er 5;
BA_ "GenSigSendType" SG_ 544 BSG_TP_Er 5;
BA_ "GenSigSendType" SG_ 557 APS_TP_Er 5;
BA_ "GenSigSendType" SG_ 579 AAG_TP_Er 5;
BA_ "GenSigSendType" SG_ 811 TPDyn_VSG_2 5;
BA_ "GenSigSendType" SG_ 810 TPDyn_VSG_1 5;
BA_ "GenSigSendType" SG_ 791 TPDyn_TSG_HR_2 5;
BA_ "GenSigSendType" SG_ 790 TPDyn_TSG_HR_1 5;
BA_ "GenSigSendType" SG_ 789 TPDyn_TSG_HL_2 5;
BA_ "GenSigSendType" SG_ 788 TPDyn_TSG_HL_1 5;
BA_ "GenSigSendType" SG_ 785 TPDyn_TSG_F_2 5;
BA_ "GenSigSendType" SG_ 784 TPDyn_TSG_F_1 5;
BA_ "GenSigSendType" SG_ 787 TPDyn_TSG_BF_2 5;
BA_ "GenSigSendType" SG_ 786 TPDyn_TSG_BF_1 5;
BA_ "GenSigSendType" SG_ 765 TPDyn_SMLS_2 5;
BA_ "GenSigSendType" SG_ 764 TPDyn_SMLS_1 5;
BA_ "GenSigSendType" SG_ 805 TPDyn_SH_2 5;
BA_ "GenSigSendType" SG_ 804 TPDyn_SH_1 5;
BA_ "GenSigSendType" SG_ 803 TPDyn_RDK_2 5;
BA_ "GenSigSendType" SG_ 802 TPDyn_RDK_1 5;
BA_ "GenSigSendType" SG_ 827 TPDyn_PTC_2 5;
BA_ "GenSigSendType" SG_ 826 TPDyn_PTC_1 5;
BA_ "GenSigSendType" SG_ 767 TPDyn_MFG_2 5;
BA_ "GenSigSendType" SG_ 766 TPDyn_MFG_1 5;
BA_ "GenSigSendType" SG_ 793 TPDyn_Mem_F_2 5;
BA_ "GenSigSendType" SG_ 792 TPDyn_Mem_F_1 5;
BA_ "GenSigSendType" SG_ 795 TPDyn_MEM_BF_2 5;
BA_ "GenSigSendType" SG_ 794 TPDyn_MEM_BF_1 5;
BA_ "GenSigSendType" SG_ 809 TPDyn_KSG_2 5;
BA_ "GenSigSendType" SG_ 808 TPDyn_KSG_1 5;
BA_ "GenSigSendType" SG_ 815 TPDyn_GW_2 5;
BA_ "GenSigSendType" SG_ 814 TPDyn_GW_1 5;
BA_ "GenSigSendType" SG_ 1235 TPDyn_Grafik_4 5;
BA_ "GenSigSendType" SG_ 1234 TPDyn_Grafik_3 5;
BA_ "GenSigSendType" SG_ 1233 TPDyn_Grafik_2 5;
BA_ "GenSigSendType" SG_ 1232 TPDyn_Grafik_1 5;
BA_ "GenSigSendType" SG_ 829 TPDyn_Clima_2 5;
BA_ "GenSigSendType" SG_ 828 TPDyn_Clima_1 5;
BA_ "GenSigSendType" SG_ 825 TPDyn_BSG_2 5;
BA_ "GenSigSendType" SG_ 824 TPDyn_BSG_1 5;
BA_ "GenSigSendType" SG_ 819 TPDyn_APS_2 5;
BA_ "GenSigSendType" SG_ 818 TPDyn_APS_1 5;
BA_ "GenSigSendType" SG_ 823 TPDyn_AAG_2 5;
BA_ "GenSigSendType" SG_ 822 TPDyn_AAG_1 5;
BA_ "SignalRepeatDeactivation" SG_ 1449 TM2_Warnblink 5;
BA_ "GenSigSendType" SG_ 1449 TM2_Warnblink 6;
BA_ "SignalRepeatActivation" SG_ 1449 TM2_Unlock 5;
BA_ "SignalRepeatDeactivation" SG_ 1449 TM2_Unlock 5;
BA_ "GenSigSendType" SG_ 1449 TM2_Unlock 6;
BA_ "SignalRepeatDeactivation" SG_ 1449 TM2_Signalhorn 5;
BA_ "GenSigSendType" SG_ 1449 TM2_Signalhorn 6;
BA_ "SignalRepeatActivation" SG_ 1449 TM2_Lock 5;
BA_ "SignalRepeatDeactivation" SG_ 1449 TM2_Lock 5;
BA_ "GenSigSendType" SG_ 1449 TM2_Lock 6;
BA_ "GenSigSendType" SG_ 1637 TF3_Show_Phone 3;
BA_ "GenSigSendType" SG_ 1637 TF3_Registrierungsstatus 3;
BA_ "GenSigSendType" SG_ 1637 TF3_Provider 3;
BA_ "GenSigSendType" SG_ 1637 TF3_Phone_sim_OK 3;
BA_ "GenSigSendType" SG_ 1637 TF3_Phone_ring 3;
BA_ "GenSigSendType" SG_ 1637 TF3_Phone_reset_timer 3;
BA_ "GenSigSendType" SG_ 1637 TF3_Phone_res 3;
BA_ "GenSigSendType" SG_ 1637 TF3_Phone_pin_OK 3;
BA_ "GenSigSendType" SG_ 1637 TF3_Phone_on 3;
BA_ "GenSigSendType" SG_ 1637 TF3_Phone_mute 3;
BA_ "GenSigSendType" SG_ 1637 TF3_Phone_Level 3;
BA_ "GenSigSendType" SG_ 1637 TF3_Phone_Error_flag 3;
BA_ "GenSigSendType" SG_ 1637 TF3_Phone_active_call 3;
BA_ "GenSigSendType" SG_ 1637 TF3_Laendercode 3;
BA_ "GenSigSendType" SG_ 1637 TF3_Feldstaerke_Fehler 3;
BA_ "GenSigSendType" SG_ 1637 TF3_Feldstaerke 3;
BA_ "GenSigSendType" SG_ 1617 SY1_Viertuerer 7;
BA_ "GenSigSendType" SG_ 1617 SY1_VersLowCAN_Komfort 7;
BA_ "GenSigSendType" SG_ 1617 SY1_VersLowCAN_Antrieb 7;
BA_ "GenSigSendType" SG_ 1617 SY1_VersHighCAN_Komfort 7;
BA_ "GenSigSendType" SG_ 1617 SY1_VersHighCAN_Antrieb 7;
BA_ "GenSigSendType" SG_ 1617 SY1_Verbauliste_gueltig 7;
BA_ "GenSigSendType" SG_ 1617 SY1_Transportmode 7;
BA_ "GenSigSendType" SG_ 1617 SY1_Sleep_Komfort 7;
BA_ "GenSigSendType" SG_ 1617 SY1_Sleep_Infotainment 7;
BA_ "GenSigSendType" SG_ 1617 SY1_Rechtslenker 7;
BA_ "GenSigSendType" SG_ 1617 SY1_Marke 7;
BA_ "GenSigSendType" SG_ 1617 SY1_Klasse 7;
BA_ "GenSigSendType" SG_ 1617 SY1_KD_Fehler 7;
BA_ "GenSigSendType" SG_ 1617 SY1_Infotainment 7;
BA_ "GenSigSendType" SG_ 1617 SY1_Generation 7;
BA_ "GenSigSendType" SG_ 1617 SY1_Erweiterung 7;
BA_ "GenSigSendType" SG_ 1617 SY1_Diag_Komfort 7;
BA_ "GenSigSendType" SG_ 1617 SY1_Diag_Infotainment 7;
BA_ "GenSigSendType" SG_ 1617 SY1_Diag_Antrieb 7;
BA_ "GenSigSendType" SG_ 1617 SY1_Derivat 7;
BA_ "GenSigSendType" SG_ 1617 SY1_CAN_Extern 7;
BA_ "GenSigSendType" SG_ 997 SH1_ZusatzHeizung 3;
BA_ "GenSigSendType" SG_ 997 SH1_SH_Modus 3;
BA_ "GenSigSendType" SG_ 997 SH1_Prog_Modus 3;
BA_ "GenSigSendType" SG_ 997 SH1_LED 3;
BA_ "GenSigSendType" SG_ 997 SH1_KD_Fehler 3;
BA_ "GenSigSendType" SG_ 997 SH1_K_Verbrauch 3;
BA_ "GenSigSendType" SG_ 997 SH1_K_Fehler 3;
BA_ "GenSigSendType" SG_ 997 SH1_Heizleistung 3;
BA_ "GenSigSendType" SG_ 997 SH1_Geblaese 3;
BA_ "GenSigSendType" SG_ 997 SH1_FunkStLftg 3;
BA_ "GenSigSendType" SG_ 997 SH1_FunkSH_Ein 3;
BA_ "GenSigSendType" SG_ 997 SH1_Funk_ein 3;
BA_ "GenSigSendType" SG_ 997 SH1_Funk_aus 3;
BA_ "GenSigSendType" SG_ 997 SH1_Fehlerstatus 3;
BA_ "GenSigSendType" SG_ 1537 SP2_S_unten 3;
BA_ "GenSigSendType" SG_ 1537 SP2_S_rechts 3;
BA_ "GenSigSendType" SG_ 1537 SP2_S_oben 3;
BA_ "GenSigSendType" SG_ 1537 SP2_S_links 3;
BA_ "GenSigSendType" SG_ 1537 SP2_S_Klappen 3;
BA_ "GenSigSendType" SG_ 1537 SP2_S_Heizung 3;
BA_ "GenSigSendType" SG_ 1537 SP2_Auswahl_rechts 3;
BA_ "GenSigSendType" SG_ 1537 SP2_Auswahl_links 3;
BA_ "SignalRepeatActivation" SG_ 1281 SP1_normieren 5;
BA_ "SignalRepeatDeactivation" SG_ 1281 SP1_normieren 5;
BA_ "GenSigSendType" SG_ 1281 SP1_normieren 4;
BA_ "SignalRepeatActivation" SG_ 1281 SP1_Hzg_Taster 5;
BA_ "SignalRepeatDeactivation" SG_ 1281 SP1_Hzg_Taster 5;
BA_ "GenSigSendType" SG_ 1281 SP1_Hzg_Taster 4;
BA_ "SignalRepeatActivation" SG_ 1281 SP1_FT_unten 5;
BA_ "SignalRepeatDeactivation" SG_ 1281 SP1_FT_unten 5;
BA_ "GenSigSendType" SG_ 1281 SP1_FT_unten 4;
BA_ "SignalRepeatActivation" SG_ 1281 SP1_FT_rechts 5;
BA_ "SignalRepeatDeactivation" SG_ 1281 SP1_FT_rechts 5;
BA_ "GenSigSendType" SG_ 1281 SP1_FT_rechts 4;
BA_ "SignalRepeatActivation" SG_ 1281 SP1_FT_oben 5;
BA_ "SignalRepeatDeactivation" SG_ 1281 SP1_FT_oben 5;
BA_ "GenSigSendType" SG_ 1281 SP1_FT_oben 4;
BA_ "SignalRepeatActivation" SG_ 1281 SP1_FT_links 5;
BA_ "SignalRepeatDeactivation" SG_ 1281 SP1_FT_links 5;
BA_ "GenSigSendType" SG_ 1281 SP1_FT_links 4;
BA_ "SignalRepeatActivation" SG_ 1281 SP1_BT_unten 5;
BA_ "SignalRepeatDeactivation" SG_ 1281 SP1_BT_unten 5;
BA_ "GenSigSendType" SG_ 1281 SP1_BT_unten 4;
BA_ "SignalRepeatActivation" SG_ 1281 SP1_BT_rechts 5;
BA_ "SignalRepeatDeactivation" SG_ 1281 SP1_BT_rechts 5;
BA_ "GenSigSendType" SG_ 1281 SP1_BT_rechts 4;
BA_ "SignalRepeatActivation" SG_ 1281 SP1_BT_oben 5;
BA_ "SignalRepeatDeactivation" SG_ 1281 SP1_BT_oben 5;
BA_ "GenSigSendType" SG_ 1281 SP1_BT_oben 4;
BA_ "SignalRepeatActivation" SG_ 1281 SP1_BT_links 5;
BA_ "SignalRepeatDeactivation" SG_ 1281 SP1_BT_links 5;
BA_ "GenSigSendType" SG_ 1281 SP1_BT_links 4;
BA_ "SignalRepeatActivation" SG_ 1281 SP1_anklappen 5;
BA_ "SignalRepeatDeactivation" SG_ 1281 SP1_anklappen 5;
BA_ "GenSigSendType" SG_ 1281 SP1_anklappen 4;
BA_ "SignalRepeatActivation" SG_ 1281 SP1_abklappen 5;
BA_ "SignalRepeatDeactivation" SG_ 1281 SP1_abklappen 5;
BA_ "GenSigSendType" SG_ 1281 SP1_abklappen 4;
BA_ "GenSigSendType" SG_ 1621 VBN_VSG_K 7;
BA_ "GenSigSendType" SG_ 1621 VBN_TV_Tuner_I 7;
BA_ "GenSigSendType" SG_ 1621 VBN_TSG_HR_K 7;
BA_ "GenSigSendType" SG_ 1621 VBN_TSG_HL_K 7;
BA_ "GenSigSendType" SG_ 1621 VBN_TSG_FT_K 7;
BA_ "GenSigSendType" SG_ 1621 VBN_TSG_BT_K 7;
BA_ "GenSigSendType" SG_ 1621 VBN_Telematik_I 7;
BA_ "GenSigSendType" SG_ 1621 VBN_Telefon_I 7;
BA_ "GenSigSendType" SG_ 1621 VBN_Standhzg_K 7;
BA_ "GenSigSendType" SG_ 1621 VBN_Spracheingabe_I 7;
BA_ "GenSigSendType" SG_ 1621 VBN_Sonderfahrzeug_SG_K 7;
BA_ "GenSigSendType" SG_ 1621 VBN_Soll_Ist_OK 7;
BA_ "GenSigSendType" SG_ 1621 VBN_SMLS_K 7;
BA_ "GenSigSendType" SG_ 1621 VBN_RDK_K 7;
BA_ "GenSigSendType" SG_ 1621 VBN_Radio_I 7;
BA_ "GenSigSendType" SG_ 1621 VBN_PTC_Heizung_K 7;
BA_ "GenSigSendType" SG_ 1621 VBN_Navigation_I 7;
BA_ "GenSigSendType" SG_ 1621 VBN_Motor_A 7;
BA_ "GenSigSendType" SG_ 1621 VBN_Memory_K 7;
BA_ "GenSigSendType" SG_ 1621 VBN_Mem_BF_K 7;
BA_ "GenSigSendType" SG_ 1621 VBN_LSM_A 7;
BA_ "GenSigSendType" SG_ 1621 VBN_Lenkhilfe_A 7;
BA_ "GenSigSendType" SG_ 1621 VBN_KSG_K 7;
BA_ "GenSigSendType" SG_ 1621 VBN_Kombi_A 7;
BA_ "GenSigSendType" SG_ 1621 VBN_Getriebe_A 7;
BA_ "GenSigSendType" SG_ 1621 VBN_Gateway_K 7;
BA_ "GenSigSendType" SG_ 1621 VBN_dyn_LWR_A 7;
BA_ "GenSigSendType" SG_ 1621 VBN_DSP_I 7;
BA_ "GenSigSendType" SG_ 1621 VBN_Clima_K 7;
BA_ "GenSigSendType" SG_ 1621 VBN_BSG_K 7;
BA_ "GenSigSendType" SG_ 1621 VBN_Bremse_A 7;
BA_ "GenSigSendType" SG_ 1621 VBN_APS_K 7;
BA_ "GenSigSendType" SG_ 1621 VBN_Allrad_A 7;
BA_ "GenSigSendType" SG_ 1621 VBN_Airbag_A 7;
BA_ "GenSigSendType" SG_ 1621 VBN_AAG_K 7;
BA_ "GenSigSendType" SG_ 1451 SB3_Show_SBS 3;
BA_ "GenSigSendType" SG_ 1451 SB3_SBS_on 3;
BA_ "GenSigSendType" SG_ 1451 SB3_SBS_mute 3;
BA_ "GenSigSendType" SG_ 1451 SB3_SBS_Level 3;
BA_ "GenSigSendType" SG_ 1451 SB3_SBS_Error_flag 3;
BA_ "GenSigSendType" SG_ 1451 SB3_SBS_com_send 3;
BA_ "GenSigSendType" SG_ 1451 SB3_SBS_active 3;
BA_ "GenSigSendType" SG_ 1603 RK4_Temp_RR 7;
BA_ "GenSigSendType" SG_ 1603 RK4_Reifenstecher_RR 7;
BA_ "GenSigSendType" SG_ 1603 RK4_Druck_RR 7;
BA_ "GenSigSendType" SG_ 1603 RK4_Diebstahl_RR 7;
BA_ "GenSigSendType" SG_ 1601 RK3_Temp_VR 7;
BA_ "GenSigSendType" SG_ 1601 RK3_Temp_VL 7;
BA_ "GenSigSendType" SG_ 1601 RK3_Temp_HR 7;
BA_ "GenSigSendType" SG_ 1601 RK3_Temp_HL 7;
BA_ "GenSigSendType" SG_ 1601 RK3_Reifenstecher_VR 7;
BA_ "GenSigSendType" SG_ 1601 RK3_Reifenstecher_VL 7;
BA_ "GenSigSendType" SG_ 1601 RK3_Reifenstecher_HR 7;
BA_ "GenSigSendType" SG_ 1601 RK3_Reifenstecher_HL 7;
BA_ "GenSigSendType" SG_ 1601 RK3_Druck_VR 7;
BA_ "GenSigSendType" SG_ 1601 RK3_Druck_VL 7;
BA_ "GenSigSendType" SG_ 1601 RK3_Druck_HR 7;
BA_ "GenSigSendType" SG_ 1601 RK3_Druck_HL 7;
BA_ "GenSigSendType" SG_ 1601 RK3_Diebstahl_VR 7;
BA_ "GenSigSendType" SG_ 1601 RK3_Diebstahl_VL 7;
BA_ "GenSigSendType" SG_ 1601 RK3_Diebstahl_HR 7;
BA_ "GenSigSendType" SG_ 1601 RK3_Diebstahl_HL 7;
BA_ "GenSigSendType" SG_ 833 RK2_Warnung_2 3;
BA_ "GenSigSendType" SG_ 833 RK2_Warnung_1 3;
BA_ "GenSigSendType" SG_ 833 RK2_Text_5 7;
BA_ "GenSigSendType" SG_ 833 RK2_Text_3 7;
BA_ "GenSigSendType" SG_ 833 RK2_Text_2 7;
BA_ "GenSigSendType" SG_ 833 RK2_Text_1 7;
BA_ "GenSigSendType" SG_ 833 RK2_Sytem_Aus 7;
BA_ "GenSigSendType" SG_ 833 RK2_Systemfehler 3;
BA_ "GenSigSendType" SG_ 833 RK2_Reifen_VR 3;
BA_ "GenSigSendType" SG_ 833 RK2_Reifen_VL 3;
BA_ "GenSigSendType" SG_ 833 RK2_Reifen_RR 3;
BA_ "GenSigSendType" SG_ 833 RK2_Reifen_HR 3;
BA_ "GenSigSendType" SG_ 833 RK2_Reifen_HL 3;
BA_ "GenSigSendType" SG_ 833 RK2_KD_Fehler 7;
BA_ "GenSigSendType" SG_ 833 RK2_Kalibrier_abgew 7;
BA_ "GenSigSendType" SG_ 833 RK2_Gelaendedruck 7;
BA_ "GenSigSendType" SG_ 833 RK2_Funkstoerung 7;
BA_ "GenSigSendType" SG_ 833 RK2_Druckdiff_Vorn 7;
BA_ "GenSigSendType" SG_ 833 RK2_Druckdiff_Hinten 7;
BA_ "GenSigSendType" SG_ 833 RK2_Befuellung_RR_low 7;
BA_ "GenSigSendType" SG_ 1091 RDK_xx_Status_Sensor 7;
BA_ "GenSigSendType" SG_ 1091 RDK_xx_Soll_Druck 7;
BA_ "GenSigSendType" SG_ 1091 RDK_xx_Ist_Temp 7;
BA_ "GenSigSendType" SG_ 1091 RDK_xx_Ist_Druck 7;
BA_ "GenSigSendType" SG_ 1091 RDK_xx_Color 7;
BA_ "GenSigSendType" SG_ 1091 RDK_Warnungen 3;
BA_ "GenSigSendType" SG_ 1091 RDK_Status 3;
BA_ "GenSigSendType" SG_ 1091 RDK_Sensor_Multiplex 7;
BA_ "GenSigSendType" SG_ 1091 RDK_Prio2_Warnung 3;
BA_ "GenSigSendType" SG_ 1091 RDK_Prio1_Warnung 3;
BA_ "GenSigSendType" SG_ 1091 RDK_neue_Solldruecke 3;
BA_ "GenSigSendType" SG_ 1091 RDK_KD_Fehler 3;
BA_ "GenSigSendType" SG_ 1091 RDK_Geschw_Warnung 3;
BA_ "GenSigSendType" SG_ 1091 RDK_Ack_IstZu_Solldruecke 3;
BA_ "GenSigSendType" SG_ 1633 RA4_Show_Radio 3;
BA_ "GenSigSendType" SG_ 1633 RA4_Radio_Para6 3;
BA_ "GenSigSendType" SG_ 1633 RA4_Radio_Para5 3;
BA_ "GenSigSendType" SG_ 1633 RA4_Radio_Para4 3;
BA_ "GenSigSendType" SG_ 1633 RA4_Radio_Para3 3;
BA_ "GenSigSendType" SG_ 1633 RA4_Radio_Para2 3;
BA_ "GenSigSendType" SG_ 1633 RA4_Radio_Para1 3;
BA_ "GenSigSendType" SG_ 1633 RA4_Radio_on 3;
BA_ "GenSigSendType" SG_ 1633 RA4_Radio_mute 3;
BA_ "GenSigSendType" SG_ 1633 RA4_Radio_Mode 3;
BA_ "GenSigSendType" SG_ 1633 RA4_Radio_Master_locked 3;
BA_ "GenSigSendType" SG_ 1633 RA4_Radio_Error_flag 3;
BA_ "GenSigSendType" SG_ 1519 PT1_Nenn_Strom 3;
BA_ "GenSigSendType" SG_ 1519 PT1_KD_Fehler 3;
BA_ "GenSigSendType" SG_ 1519 PT1_Ist_Strom 3;
BA_ "GenSigSendType" SG_ 1519 PT1_Fehlerstatus 3;
BA_ "GenSigSendType" SG_ 1519 PT1_Fehler_Nenn_Strom 3;
BA_ "GenSigSendType" SG_ 1519 PT1_Fehler_Ist_Strom 3;
BA_ "GenSigSendType" SG_ 1519 PT1_Aktiv 3;
BA_ "GenSigSendType" SG_ 1349 PA3_Tongeber_v_defekt 3;
BA_ "GenSigSendType" SG_ 1349 PA3_Tongeber_h_defekt 3;
BA_ "GenSigSendType" SG_ 1349 PA3_Taster_aktiviert 3;
BA_ "GenSigSendType" SG_ 1349 PA3_System_codierung 3;
BA_ "GenSigSendType" SG_ 1349 PA3_Sensor_vrr_defekt 3;
BA_ "GenSigSendType" SG_ 1349 PA3_Sensor_vrm_defekt 3;
BA_ "GenSigSendType" SG_ 1349 PA3_Sensor_vlm_defekt 3;
BA_ "GenSigSendType" SG_ 1349 PA3_Sensor_vll_defekt 3;
BA_ "GenSigSendType" SG_ 1349 PA3_Sensor_hrr_defekt 3;
BA_ "GenSigSendType" SG_ 1349 PA3_Sensor_hrm_defekt 3;
BA_ "GenSigSendType" SG_ 1349 PA3_Sensor_hlm_defekt 3;
BA_ "GenSigSendType" SG_ 1349 PA3_Sensor_hll_defekt 3;
BA_ "GenSigSendType" SG_ 1349 PA3_Schlechtweg_aus 3;
BA_ "GenSigSendType" SG_ 1349 PA3_Rueckwaertsgang_aktiv 3;
BA_ "GenSigSendType" SG_ 1349 PA3_KD_Fehler 3;
BA_ "GenSigSendType" SG_ 1349 PA3_Geschwindigkeit_aus 3;
BA_ "GenSigSendType" SG_ 1349 PA3_Eis_aus 3;
BA_ "GenSigSendType" SG_ 1349 PA3_Bereit 3;
BA_ "GenSigSendType" SG_ 1349 PA3_Bereich_vo 3;
BA_ "GenSigSendType" SG_ 1349 PA3_Bereich_hi 3;
BA_ "GenSigSendType" SG_ 1349 PA3_Aufbau_erk 3;
BA_ "GenSigSendType" SG_ 1349 PA3_Anlage_defekt 3;
BA_ "GenSigSendType" SG_ 1349 PA3_Akust_aus 3;
BA_ "GenSigSendType" SG_ 1025 NMZK_ZK_Neigungssensor 3;
BA_ "GenSigSendType" SG_ 1025 NMZK_SleepInd 3;
BA_ "GenSigSendType" SG_ 1025 NMZK_SleepAck 3;
BA_ "GenSigSendType" SG_ 1025 NMZK_Receiver 3;
BA_ "GenSigSendType" SG_ 1025 NMZK_NWake 3;
BA_ "GenSigSendType" SG_ 1025 NMZK_Kl_30_Reset 3;
BA_ "GenSigSendType" SG_ 1025 NMZK_IRUE_Ausloesung 3;
BA_ "GenSigSendType" SG_ 1025 NMZK_HD_Vorraste 3;
BA_ "GenSigSendType" SG_ 1025 NMZK_HD_Taster 3;
BA_ "GenSigSendType" SG_ 1025 NMZK_HD_Schloss_zu 3;
BA_ "GenSigSendType" SG_ 1025 NMZK_HD_Schloss_auf 3;
BA_ "GenSigSendType" SG_ 1025 NMZK_HD_Hauptraste 3;
BA_ "GenSigSendType" SG_ 1025 NMZK_Fond_Lock 3;
BA_ "GenSigSendType" SG_ 1025 NMZK_Fkt_Nachlauf 3;
BA_ "GenSigSendType" SG_ 1025 NMZK_CmdRing 3;
BA_ "GenSigSendType" SG_ 1025 NMZK_CmdLimpHome 3;
BA_ "GenSigSendType" SG_ 1025 NMZK_CmdAlive 3;
BA_ "GenSigSendType" SG_ 1025 NMZK_CAN 3;
BA_ "GenSigSendType" SG_ 1025 NMZK_Bremslicht 3;
BA_ "GenSigSendType" SG_ 1040 NMVSG_SleepInd 3;
BA_ "GenSigSendType" SG_ 1040 NMVSG_SleepAck 3;
BA_ "GenSigSendType" SG_ 1040 NMVSG_Receiver 3;
BA_ "GenSigSendType" SG_ 1040 NMVSG_NWake 3;
BA_ "GenSigSendType" SG_ 1040 NMVSG_Kl_30_Reset 3;
BA_ "GenSigSendType" SG_ 1040 NMVSG_Fkt_Nachlauf 3;
BA_ "GenSigSendType" SG_ 1040 NMVSG_CmdRing 3;
BA_ "GenSigSendType" SG_ 1040 NMVSG_CmdLimpHome 3;
BA_ "GenSigSendType" SG_ 1040 NMVSG_CmdAlive 3;
BA_ "GenSigSendType" SG_ 1040 NMVSG_CAN 3;
BA_ "GenSigSendType" SG_ 1029 NMHR_Verr_Zustand 3;
BA_ "GenSigSendType" SG_ 1029 NMHR_Verr_Taster 3;
BA_ "GenSigSendType" SG_ 1029 NMHR_Unlock 3;
BA_ "GenSigSendType" SG_ 1029 NMHR_Tuergriff_Innern 3;
BA_ "GenSigSendType" SG_ 1029 NMHR_Tuergriff_Aussen 3;
BA_ "GenSigSendType" SG_ 1029 NMHR_SleepInd 3;
BA_ "GenSigSendType" SG_ 1029 NMHR_SleepAck 3;
BA_ "GenSigSendType" SG_ 1029 NMHR_Safe_Zustand 3;
BA_ "GenSigSendType" SG_ 1029 NMHR_Receiver 3;
BA_ "GenSigSendType" SG_ 1029 NMHR_PTT_Taste 3;
BA_ "GenSigSendType" SG_ 1029 NMHR_NWake 3;
BA_ "GenSigSendType" SG_ 1029 NMHR_Lock 3;
BA_ "GenSigSendType" SG_ 1029 NMHR_Kl_30_Reset 3;
BA_ "GenSigSendType" SG_ 1029 NMHR_Fkt_Nachlauf 3;
BA_ "GenSigSendType" SG_ 1029 NMHR_Drehfalle 3;
BA_ "GenSigSendType" SG_ 1029 NMHR_CmdRing 3;
BA_ "GenSigSendType" SG_ 1029 NMHR_CmdLimpHome 3;
BA_ "GenSigSendType" SG_ 1029 NMHR_CmdAlive 3;
BA_ "GenSigSendType" SG_ 1029 NMHR_CAN 3;
BA_ "GenSigSendType" SG_ 1028 NMHL_Verr_Zustand 3;
BA_ "GenSigSendType" SG_ 1028 NMHL_Verr_Taster 3;
BA_ "GenSigSendType" SG_ 1028 NMHL_Unlock 3;
BA_ "GenSigSendType" SG_ 1028 NMHL_Tuergriff_Innern 3;
BA_ "GenSigSendType" SG_ 1028 NMHL_Tuergriff_Aussen 3;
BA_ "GenSigSendType" SG_ 1028 NMHL_SleepInd 3;
BA_ "GenSigSendType" SG_ 1028 NMHL_SleepAck 3;
BA_ "GenSigSendType" SG_ 1028 NMHL_Safe_Zustand 3;
BA_ "GenSigSendType" SG_ 1028 NMHL_Receiver 3;
BA_ "GenSigSendType" SG_ 1028 NMHL_PTT_Taste 3;
BA_ "GenSigSendType" SG_ 1028 NMHL_NWake 3;
BA_ "GenSigSendType" SG_ 1028 NMHL_Lock 3;
BA_ "GenSigSendType" SG_ 1028 NMHL_Kl_30_Reset 3;
BA_ "GenSigSendType" SG_ 1028 NMHL_Fkt_Nachlauf 3;
BA_ "GenSigSendType" SG_ 1028 NMHL_Drehfalle 3;
BA_ "GenSigSendType" SG_ 1028 NMHL_CmdRing 3;
BA_ "GenSigSendType" SG_ 1028 NMHL_CmdLimpHome 3;
BA_ "GenSigSendType" SG_ 1028 NMHL_CmdAlive 3;
BA_ "GenSigSendType" SG_ 1028 NMHL_CAN 3;
BA_ "GenSigSendType" SG_ 1026 NMFT_Verr_Zustand 3;
BA_ "GenSigSendType" SG_ 1026 NMFT_Verr_Taster 3;
BA_ "GenSigSendType" SG_ 1026 NMFT_Unlock 3;
BA_ "GenSigSendType" SG_ 1026 NMFT_Tuergriff_Innern 3;
BA_ "GenSigSendType" SG_ 1026 NMFT_Tuergriff_Aussen 3;
BA_ "GenSigSendType" SG_ 1026 NMFT_Taster_Tankklappe 3;
BA_ "GenSigSendType" SG_ 1026 NMFT_SleepInd 3;
BA_ "GenSigSendType" SG_ 1026 NMFT_SleepAck 3;
BA_ "GenSigSendType" SG_ 1026 NMFT_Schloss_zu 3;
BA_ "GenSigSendType" SG_ 1026 NMFT_Schloss_auf 3;
BA_ "GenSigSendType" SG_ 1026 NMFT_Safe_Zustand 3;
BA_ "GenSigSendType" SG_ 1026 NMFT_Receiver 3;
BA_ "GenSigSendType" SG_ 1026 NMFT_NWake 3;
BA_ "GenSigSendType" SG_ 1026 NMFT_Lock 3;
BA_ "GenSigSendType" SG_ 1026 NMFT_Kl_30_Reset 3;
BA_ "GenSigSendType" SG_ 1026 NMFT_Fkt_Nachlauf 3;
BA_ "GenSigSendType" SG_ 1026 NMFT_FH_Fahrer 3;
BA_ "GenSigSendType" SG_ 1026 NMFT_Drehfalle 3;
BA_ "GenSigSendType" SG_ 1026 NMFT_CmdRing 3;
BA_ "GenSigSendType" SG_ 1026 NMFT_CmdLimpHome 3;
BA_ "GenSigSendType" SG_ 1026 NMFT_CmdAlive 3;
BA_ "GenSigSendType" SG_ 1026 NMFT_CAN 3;
BA_ "GenSigSendType" SG_ 1027 NMBT_Verr_Zustand 3;
BA_ "GenSigSendType" SG_ 1027 NMBT_Verr_Taster 3;
BA_ "GenSigSendType" SG_ 1027 NMBT_Unlock 3;
BA_ "GenSigSendType" SG_ 1027 NMBT_Tuergriff_Innern 3;
BA_ "GenSigSendType" SG_ 1027 NMBT_Tuergriff_Aussen 3;
BA_ "GenSigSendType" SG_ 1027 NMBT_SleepInd 3;
BA_ "GenSigSendType" SG_ 1027 NMBT_SleepAck 3;
BA_ "GenSigSendType" SG_ 1027 NMBT_Schloss_zu 3;
BA_ "GenSigSendType" SG_ 1027 NMBT_Schloss_auf 3;
BA_ "GenSigSendType" SG_ 1027 NMBT_Safe_Zustand 3;
BA_ "GenSigSendType" SG_ 1027 NMBT_Receiver 3;
BA_ "GenSigSendType" SG_ 1027 NMBT_PTT_Taster 3;
BA_ "GenSigSendType" SG_ 1027 NMBT_NWake 3;
BA_ "GenSigSendType" SG_ 1027 NMBT_Lock 3;
BA_ "GenSigSendType" SG_ 1027 NMBT_Kl_30_Reset 3;
BA_ "GenSigSendType" SG_ 1027 NMBT_Fkt_Nachlauf 3;
BA_ "GenSigSendType" SG_ 1027 NMBT_Drehfalle 3;
BA_ "GenSigSendType" SG_ 1027 NMBT_CmdRing 3;
BA_ "GenSigSendType" SG_ 1027 NMBT_CmdLimpHome 3;
BA_ "GenSigSendType" SG_ 1027 NMBT_CmdAlive 3;
BA_ "GenSigSendType" SG_ 1027 NMBT_CAN 3;
BA_ "GenSigSendType" SG_ 1034 NMLS_SleepInd 3;
BA_ "GenSigSendType" SG_ 1034 NMLS_SleepAck 3;
BA_ "GenSigSendType" SG_ 1034 NMLS_S_Kontakt_ein_aus 3;
BA_ "GenSigSendType" SG_ 1034 NMLS_S_Kontakt_aus_ein 3;
BA_ "GenSigSendType" SG_ 1034 NMLS_Receiver 3;
BA_ "GenSigSendType" SG_ 1034 NMLS_Parklicht_ein_aus 3;
BA_ "GenSigSendType" SG_ 1034 NMLS_Parklicht_aus_ein 3;
BA_ "GenSigSendType" SG_ 1034 NMLS_NWake 3;
BA_ "GenSigSendType" SG_ 1034 NMLS_LSV 3;
BA_ "GenSigSendType" SG_ 1034 NMLS_Lichthupe_ein_aus 3;
BA_ "GenSigSendType" SG_ 1034 NMLS_Lichthupe_aus_ein 3;
BA_ "GenSigSendType" SG_ 1034 NMLS_Klemme15 3;
BA_ "GenSigSendType" SG_ 1034 NMLS_Kl_30_Reset 3;
BA_ "GenSigSendType" SG_ 1034 NMLS_Fkt_Nachlauf 3;
BA_ "GenSigSendType" SG_ 1034 NMLS_CmdRing 3;
BA_ "GenSigSendType" SG_ 1034 NMLS_CmdLimpHome 3;
BA_ "GenSigSendType" SG_ 1034 NMLS_CmdAlive 3;
BA_ "GenSigSendType" SG_ 1034 NMLS_CAN 3;
